VERSION "dbc-export 1 2025.20.8"

NS_ :

BS_:

BU_: ADSP APB APP APS APSB BB BMS CC CMP CMPD CP DAS DI DIF DIR DPB EPAS3P EPAS3S EPASTP EPASTS EPBL EPBR ESP EVSE FC GTW HCML HCMR HVP IBST ICR IDB LS OCS1P ODIN PARK PCS PLG PM PMF PMR PNCD PTC RADC RCM RCM2 RCM3 RCU SCCM SCM SCS SDCR TAS TCU TPMS TRCM UDS UI UIS UMC USM VC VCFRONT VCLEFT VCRIGHT VCSEC VEH

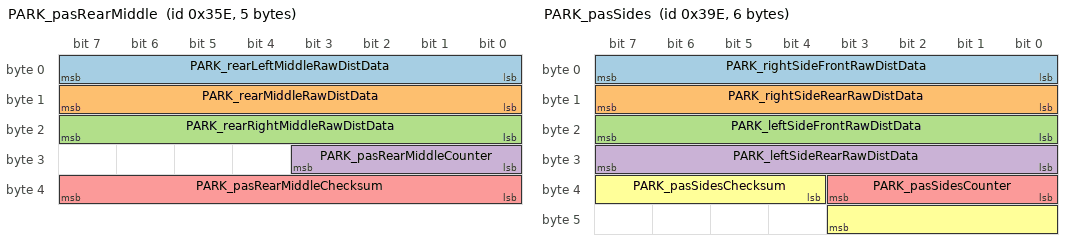
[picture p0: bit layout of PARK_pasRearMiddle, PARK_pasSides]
BO_ 862 PARK_pasRearMiddle: 5 PARK
 SG_ PARK_rearLeftMiddleRawDistData : 0|8@1+ (1,0) [0|254] "cm" Vector__XXX
 SG_ PARK_rearMiddleRawDistData : 8|8@1+ (1,0) [0|254] "cm" Vector__XXX
 SG_ PARK_rearRightMiddleRawDistData : 16|8@1+ (1,0) [0|254] "cm" Vector__XXX
 SG_ PARK_pasRearMiddleCounter : 24|4@1+ (1,0) [0|15] "" Vector__XXX
 SG_ PARK_pasRearMiddleChecksum : 32|8@1+ (1,0) [0|255] "" Vector__XXX

BO_ 926 PARK_pasSides: 6 PARK
 SG_ PARK_rightSideFrontRawDistData : 0|8@1+ (1,0) [0|254] "cm" Vector__XXX
 SG_ PARK_rightSideRearRawDistData : 8|8@1+ (1,0) [0|254] "cm" Vector__XXX
 SG_ PARK_leftSideFrontRawDistData : 16|8@1+ (1,0) [0|254] "cm" Vector__XXX
 SG_ PARK_leftSideRearRawDistData : 24|8@1+ (1,0) [0|254] "cm" Vector__XXX
 SG_ PARK_pasSidesCounter : 32|4@1+ (1,0) [0|15] "" Vector__XXX
 SG_ PARK_pasSidesChecksum : 36|8@1+ (1,0) [0|255] "" Vector__XXX

BO_ 606 PARK_pscEnvSlot: 8 PARK
 SG_ PARK_pscEnvSlotType M : 0|2@1+ (1,0) [0|3] "" Vector__XXX
 SG_ PARK_pscLeftParallelObj1X m0 : 3|11@1+ (2,-2048) [-2048|2044] "cm" Vector__XXX
 SG_ PARK_pscLeftParallelObj1Y m0 : 14|11@1+ (2,-2048) [-2048|2044] "cm" Vector__XXX
 SG_ PARK_pscLeftParallelObj1Alpha m0 : 25|7@1+ (2,-128) [-128|124] "deg" Vector__XXX
 SG_ PARK_pscLeftParallelObj2Y m0 : 35|11@1+ (2,-2048) [-2048|2044] "cm" Vector__XXX
 SG_ PARK_pscLeftParallelObj2X m0 : 46|11@1+ (2,-2048) [-2048|2044] "cm" Vector__XXX
 SG_ PARK_pscLeftParallelObj2Alpha m0 : 57|7@1+ (2,-128) [-128|124] "deg" Vector__XXX
 SG_ PARK_pscLeftCrossObj1X m1 : 3|11@1+ (2,-2048) [-2048|2044] "cm" Vector__XXX
 SG_ PARK_pscLeftCrossObj1Y m1 : 14|11@1+ (2,-2048) [-2048|2044] "cm" Vector__XXX
 SG_ PARK_pscLeftCrossObj1Alpha m1 : 25|7@1+ (2,-128) [-128|124] "deg" Vector__XXX
 SG_ PARK_pscLeftCrossObj2Y m1 : 35|11@1+ (2,-2048) [-2048|2044] "cm" Vector__XXX
 SG_ PARK_pscLeftCrossObj2X m1 : 46|11@1+ (2,-2048) [-2048|2044] "cm" Vector__XXX
 SG_ PARK_pscLeftCrossObj2Alpha m1 : 57|7@1+ (2,-128) [-128|124] "deg" Vector__XXX
 SG_ PARK_pscRightParallelObj1X m2 : 3|11@1+ (2,-2048) [-2048|2044] "cm" Vector__XXX
 SG_ PARK_pscRightParallelObj1Y m2 : 14|11@1+ (2,-2048) [-2048|2044] "cm" Vector__XXX
 SG_ PARK_pscRightParallelObj1Alpha m2 : 25|7@1+ (2,-128) [-128|124] "deg" Vector__XXX
 SG_ PARK_pscRightParallelObj2Y m2 : 35|11@1+ (2,-2048) [-2048|2044] "cm" Vector__XXX
 SG_ PARK_pscRightParallelObj2X m2 : 46|11@1+ (2,-2048) [-2048|2044] "cm" Vector__XXX
 SG_ PARK_pscRightParallelObj2Alpha m2 : 57|7@1+ (2,-128) [-128|124] "deg" Vector__XXX
 SG_ PARK_pscRightCrossObj1X m3 : 3|11@1+ (2,-2048) [-2048|2044] "cm" Vector__XXX
 SG_ PARK_pscRightCrossObj1Y m3 : 14|11@1+ (2,-2048) [-2048|2044] "cm" Vector__XXX
 SG_ PARK_pscRightCrossObj1Alpha m3 : 25|7@1+ (2,-128) [-128|124] "deg" Vector__XXX
 SG_ PARK_pscRightCrossObj2Y m3 : 35|11@1+ (2,-2048) [-2048|2044] "cm" Vector__XXX
 SG_ PARK_pscRightCrossObj2X m3 : 46|11@1+ (2,-2048) [-2048|2044] "cm" Vector__XXX
 SG_ PARK_pscRightCrossObj2Alpha m3 : 57|7@1+ (2,-128) [-128|124] "deg" Vector__XXX

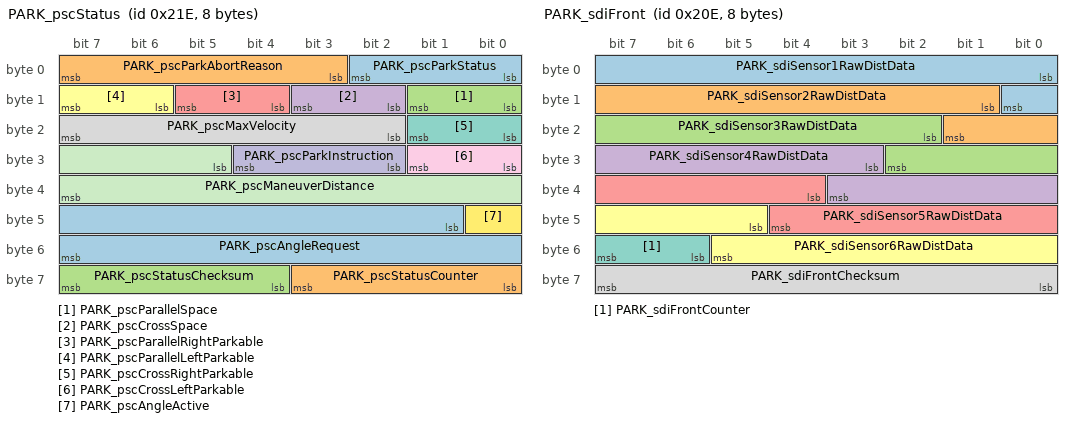
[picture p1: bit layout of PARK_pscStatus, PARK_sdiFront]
BO_ 542 PARK_pscStatus: 8 PARK
 SG_ PARK_pscParkStatus : 0|3@1+ (1,0) [0|6] "" Vector__XXX
 SG_ PARK_pscParkAbortReason : 3|5@1+ (1,0) [0|30] "" Vector__XXX
 SG_ PARK_pscParallelSpace : 8|2@1+ (1,0) [0|3] "" Vector__XXX
 SG_ PARK_pscCrossSpace : 10|2@1+ (1,0) [0|3] "" Vector__XXX
 SG_ PARK_pscParallelRightParkable : 12|2@1+ (1,0) [0|2] "" Vector__XXX
 SG_ PARK_pscParallelLeftParkable : 14|2@1+ (1,0) [0|2] "" Vector__XXX
 SG_ PARK_pscCrossRightParkable : 16|2@1+ (1,0) [0|2] "" Vector__XXX
 SG_ PARK_pscMaxVelocity : 18|6@1+ (0.1,0) [0|6.2] "kph" Vector__XXX
 SG_ PARK_pscCrossLeftParkable : 24|2@1+ (1,0) [0|2] "" Vector__XXX
 SG_ PARK_pscParkInstruction : 26|3@1+ (1,0) [0|6] "" Vector__XXX
 SG_ PARK_pscManeuverDistance : 29|11@1+ (1,0) [0|2046] "cm" Vector__XXX
 SG_ PARK_pscAngleActive : 40|1@1+ (1,0) [0|1] "" Vector__XXX
 SG_ PARK_pscAngleRequest : 41|15@1+ (0.1,-1638.4) [-1638.4|1638.3] "deg" Vector__XXX
 SG_ PARK_pscStatusCounter : 56|4@1+ (1,0) [0|15] "" Vector__XXX
 SG_ PARK_pscStatusChecksum : 60|4@1+ (1,0) [0|15] "" Vector__XXX

BO_ 590 PARK_pscVehSlot: 8 PARK
 SG_ PARK_pscVehSlotType M : 0|2@1+ (1,0) [0|3] "" Vector__XXX
 SG_ PARK_pscLeftParallelVehX m0 : 5|11@1+ (2,-2048) [-2048|2044] "cm" Vector__XXX
 SG_ PARK_pscLeftParallelVehY m0 : 16|11@1+ (2,-2048) [-2048|2044] "cm" Vector__XXX
 SG_ PARK_pscLeftParallelPsi m0 : 32|13@1+ (0.0009765625,0) [0|7.998046875] "radians" Vector__XXX
 SG_ PARK_pscLeftParallelSizeX m0 : 48|8@1+ (4,0) [0|1016] "cm" Vector__XXX
 SG_ PARK_pscLeftParallelSizeY m0 : 56|8@1+ (4,0) [0|1016] "cm" Vector__XXX
 SG_ PARK_pscLeftCrossVehX m1 : 5|11@1+ (2,-2048) [-2048|2044] "cm" Vector__XXX
 SG_ PARK_pscLeftCrossVehY m1 : 16|11@1+ (2,-2048) [-2048|2044] "cm" Vector__XXX
 SG_ PARK_pscLeftCrossPsi m1 : 32|13@1+ (0.0009765625,0) [0|7.998046875] "radians" Vector__XXX
 SG_ PARK_pscLeftCrossSizeX m1 : 48|8@1+ (4,0) [0|1016] "cm" Vector__XXX
 SG_ PARK_pscLeftCrossSizeY m1 : 56|8@1+ (4,0) [0|1016] "cm" Vector__XXX
 SG_ PARK_pscRightParallelVehX m2 : 5|11@1+ (2,-2048) [-2048|2044] "cm" Vector__XXX
 SG_ PARK_pscRightParallelVehY m2 : 16|11@1+ (2,-2048) [-2048|2044] "cm" Vector__XXX
 SG_ PARK_pscRightParallelPsi m2 : 32|13@1+ (0.0009765625,0) [0|7.998046875] "radians" Vector__XXX
 SG_ PARK_pscRightParallelSizeX m2 : 48|8@1+ (4,0) [0|1016] "cm" Vector__XXX
 SG_ PARK_pscRightParallelSizeY m2 : 56|8@1+ (4,0) [0|1016] "cm" Vector__XXX
 SG_ PARK_pscRightCrossVehX m3 : 5|11@1+ (2,-2048) [-2048|2044] "cm" Vector__XXX
 SG_ PARK_pscRightCrossVehY m3 : 16|11@1+ (2,-2048) [-2048|2044] "cm" Vector__XXX
 SG_ PARK_pscRightCrossPsi m3 : 32|13@1+ (0.0009765625,0) [0|7.998046875] "radians" Vector__XXX
 SG_ PARK_pscRightCrossSizeX m3 : 48|8@1+ (4,0) [0|1016] "cm" Vector__XXX
 SG_ PARK_pscRightCrossSizeY m3 : 56|8@1+ (4,0) [0|1016] "cm" Vector__XXX

BO_ 526 PARK_sdiFront: 8 PARK
 SG_ PARK_sdiSensor1RawDistData : 0|9@1+ (1,0) [0|510] "cm" Vector__XXX
 SG_ PARK_sdiSensor2RawDistData : 9|9@1+ (1,0) [0|510] "cm" Vector__XXX
 SG_ PARK_sdiSensor3RawDistData : 18|9@1+ (1,0) [0|510] "cm" Vector__XXX
 SG_ PARK_sdiSensor4RawDistData : 27|9@1+ (1,0) [0|510] "cm" Vector__XXX
 SG_ PARK_sdiSensor5RawDistData : 36|9@1+ (1,0) [0|510] "cm" Vector__XXX
 SG_ PARK_sdiSensor6RawDistData : 45|9@1+ (1,0) [0|510] "cm" Vector__XXX
 SG_ PARK_sdiFrontCounter : 54|2@1+ (1,0) [0|3] "" Vector__XXX
 SG_ PARK_sdiFrontChecksum : 56|8@1+ (1,0) [0|255] "" Vector__XXX

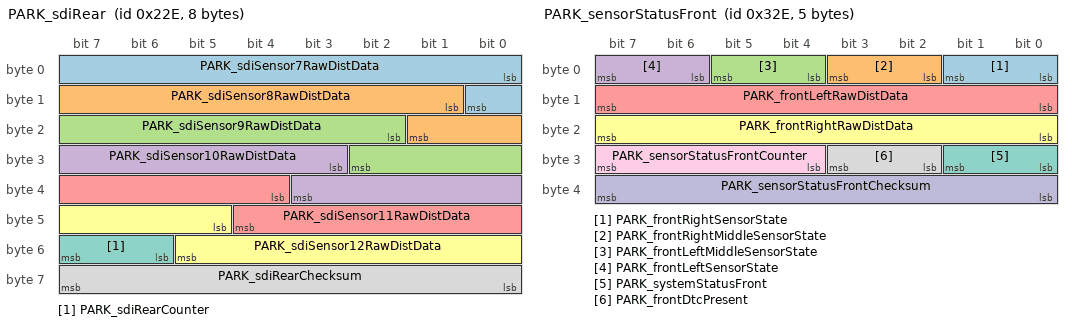
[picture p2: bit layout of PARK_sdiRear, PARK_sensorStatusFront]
BO_ 558 PARK_sdiRear: 8 PARK
 SG_ PARK_sdiSensor7RawDistData : 0|9@1+ (1,0) [0|510] "cm" Vector__XXX
 SG_ PARK_sdiSensor8RawDistData : 9|9@1+ (1,0) [0|510] "cm" Vector__XXX
 SG_ PARK_sdiSensor9RawDistData : 18|9@1+ (1,0) [0|510] "cm" Vector__XXX
 SG_ PARK_sdiSensor10RawDistData : 27|9@1+ (1,0) [0|510] "cm" Vector__XXX
 SG_ PARK_sdiSensor11RawDistData : 36|9@1+ (1,0) [0|510] "cm" Vector__XXX
 SG_ PARK_sdiSensor12RawDistData : 45|9@1+ (1,0) [0|510] "cm" Vector__XXX
 SG_ PARK_sdiRearCounter : 54|2@1+ (1,0) [0|3] "" Vector__XXX
 SG_ PARK_sdiRearChecksum : 56|8@1+ (1,0) [0|255] "" Vector__XXX

BO_ 814 PARK_sensorStatusFront: 5 PARK
 SG_ PARK_frontRightSensorState : 0|2@1+ (1,0) [0|2] "" Vector__XXX
 SG_ PARK_frontRightMiddleSensorState : 2|2@1+ (1,0) [0|2] "" Vector__XXX
 SG_ PARK_frontLeftMiddleSensorState : 4|2@1+ (1,0) [0|2] "" Vector__XXX
 SG_ PARK_frontLeftSensorState : 6|2@1+ (1,0) [0|2] "" Vector__XXX
 SG_ PARK_frontLeftRawDistData : 8|8@1+ (1,0) [0|254] "cm" Vector__XXX
 SG_ PARK_frontRightRawDistData : 16|8@1+ (1,0) [0|254] "cm" Vector__XXX
 SG_ PARK_systemStatusFront : 24|2@1+ (1,0) [0|2] "" Vector__XXX
 SG_ PARK_frontDtcPresent : 26|2@1+ (1,0) [0|2] "" Vector__XXX
 SG_ PARK_sensorStatusFrontCounter : 28|4@1+ (1,0) [0|15] "" Vector__XXX
 SG_ PARK_sensorStatusFrontChecksum : 32|8@1+ (1,0) [0|255] "" Vector__XXX

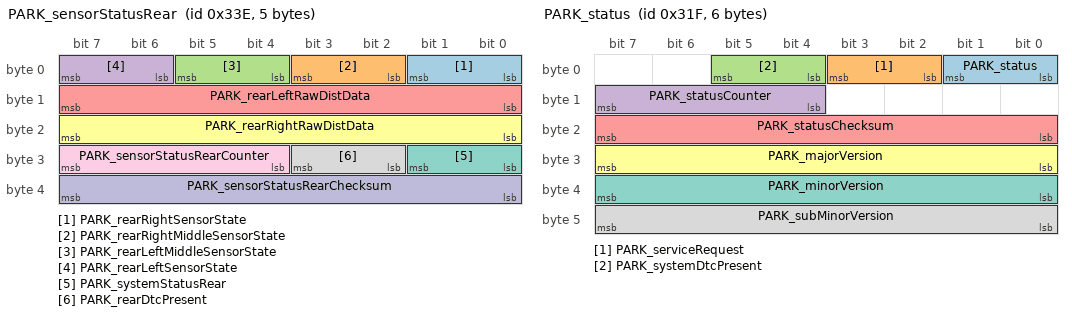
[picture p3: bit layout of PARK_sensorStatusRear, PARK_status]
BO_ 830 PARK_sensorStatusRear: 5 PARK
 SG_ PARK_rearRightSensorState : 0|2@1+ (1,0) [0|2] "" Vector__XXX
 SG_ PARK_rearRightMiddleSensorState : 2|2@1+ (1,0) [0|2] "" Vector__XXX
 SG_ PARK_rearLeftMiddleSensorState : 4|2@1+ (1,0) [0|2] "" Vector__XXX
 SG_ PARK_rearLeftSensorState : 6|2@1+ (1,0) [0|2] "" Vector__XXX
 SG_ PARK_rearLeftRawDistData : 8|8@1+ (1,0) [0|254] "cm" Vector__XXX
 SG_ PARK_rearRightRawDistData : 16|8@1+ (1,0) [0|254] "cm" Vector__XXX
 SG_ PARK_systemStatusRear : 24|2@1+ (1,0) [0|2] "" Vector__XXX
 SG_ PARK_rearDtcPresent : 26|2@1+ (1,0) [0|2] "" Vector__XXX
 SG_ PARK_sensorStatusRearCounter : 28|4@1+ (1,0) [0|15] "" Vector__XXX
 SG_ PARK_sensorStatusRearChecksum : 32|8@1+ (1,0) [0|255] "" Vector__XXX

BO_ 799 PARK_status: 6 PARK
 SG_ PARK_status : 0|2@1+ (1,0) [0|2] "" Vector__XXX
 SG_ PARK_serviceRequest : 2|2@1+ (1,0) [0|2] "" Vector__XXX
 SG_ PARK_systemDtcPresent : 4|2@1+ (1,0) [0|2] "" Vector__XXX
 SG_ PARK_statusCounter : 12|4@1+ (1,0) [0|15] "" Vector__XXX
 SG_ PARK_statusChecksum : 16|8@1+ (1,0) [0|255] "" Vector__XXX
 SG_ PARK_majorVersion : 24|8@1+ (1,0) [0|254] "" Vector__XXX
 SG_ PARK_minorVersion : 32|8@1+ (1,0) [0|254] "" Vector__XXX
 SG_ PARK_subMinorVersion : 40|8@1+ (1,0) [0|254] "" Vector__XXX

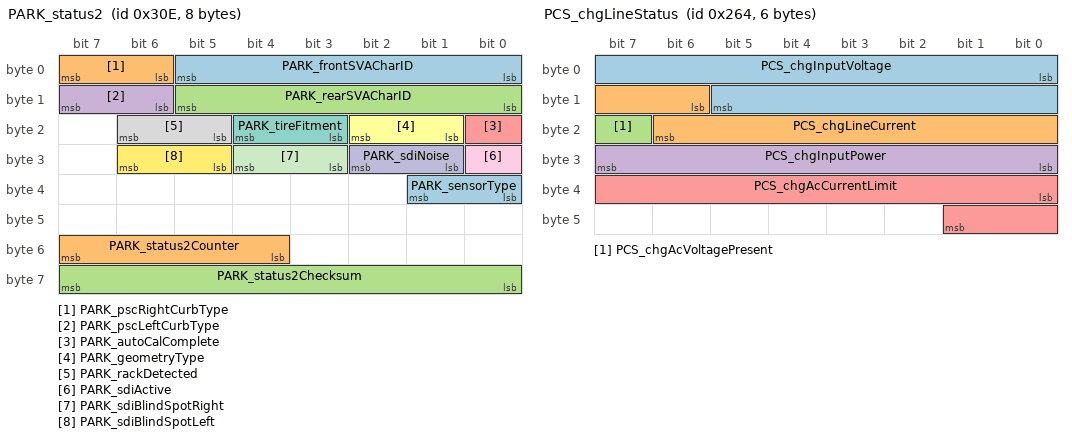
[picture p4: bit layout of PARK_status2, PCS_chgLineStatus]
BO_ 782 PARK_status2: 8 PARK
 SG_ PARK_frontSVACharID : 0|6@1+ (1,0) [0|63] "" Vector__XXX
 SG_ PARK_pscRightCurbType : 6|2@1+ (1,0) [0|3] "" Vector__XXX
 SG_ PARK_rearSVACharID : 8|6@1+ (1,0) [0|63] "" Vector__XXX
 SG_ PARK_pscLeftCurbType : 14|2@1+ (1,0) [0|3] "" Vector__XXX
 SG_ PARK_autoCalComplete : 16|1@1+ (1,0) [0|1] "" Vector__XXX
 SG_ PARK_geometryType : 17|2@1+ (1,0) [0|3] "" Vector__XXX
 SG_ PARK_tireFitment : 19|2@1+ (1,0) [0|2] "" Vector__XXX
 SG_ PARK_rackDetected : 21|2@1+ (1,0) [0|2] "" Vector__XXX
 SG_ PARK_sdiActive : 24|1@1+ (1,0) [0|1] "" Vector__XXX
 SG_ PARK_sdiNoise : 25|2@1+ (1,0) [0|2] "" Vector__XXX
 SG_ PARK_sdiBlindSpotRight : 27|2@1+ (1,0) [0|2] "" Vector__XXX
 SG_ PARK_sdiBlindSpotLeft : 29|2@1+ (1,0) [0|2] "" Vector__XXX
 SG_ PARK_sensorType : 32|2@1+ (1,0) [0|2] "" Vector__XXX
 SG_ PARK_status2Counter : 52|4@1+ (1,0) [0|15] "" Vector__XXX
 SG_ PARK_status2Checksum : 56|8@1+ (1,0) [0|255] "" Vector__XXX

BO_ 1630 PARK_udsResponse: 8 PARK
 SG_ PARK_udsResponseData : 0|64@1+ (1,0) [0|1.84467440737e+19] "" Vector__XXX

BO_ 894 PARK_warningMatrix: 8 PARK
 SG_ PARK_matrixIndex M : 0|4@1+ (1,0) [0|15] "" Vector__XXX
 SG_ PARK_a001_s1_overTemp m0 : 4|1@1+ (1,0) [0|1] "" Vector__XXX
 SG_ PARK_a002_s1_internalFail m0 : 5|1@1+ (1,0) [0|1] "" Vector__XXX
 SG_ PARK_a003_s1_linCommError m0 : 6|1@1+ (1,0) [0|1] "" Vector__XXX
 SG_ PARK_a004_s1_blocked m0 : 7|1@1+ (1,0) [0|1] "" Vector__XXX
 SG_ PARK_a005_s1_crossTalk m0 : 8|1@1+ (1,0) [0|1] "" Vector__XXX
 SG_ PARK_a006_s2_overTemp m0 : 9|1@1+ (1,0) [0|1] "" Vector__XXX
 SG_ PARK_a007_s2_internalFail m0 : 10|1@1+ (1,0) [0|1] "" Vector__XXX
 SG_ PARK_a008_s2_linCommError m0 : 11|1@1+ (1,0) [0|1] "" Vector__XXX
 SG_ PARK_a009_s2_blocked m0 : 12|1@1+ (1,0) [0|1] "" Vector__XXX
 SG_ PARK_a010_s2_crossTalk m0 : 13|1@1+ (1,0) [0|1] "" Vector__XXX
 SG_ PARK_a011_s3_overTemp m0 : 14|1@1+ (1,0) [0|1] "" Vector__XXX
 SG_ PARK_a012_s3_internalFail m0 : 15|1@1+ (1,0) [0|1] "" Vector__XXX
 SG_ PARK_a013_s3_linCommError m0 : 16|1@1+ (1,0) [0|1] "" Vector__XXX
 SG_ PARK_a014_s3_blocked m0 : 17|1@1+ (1,0) [0|1] "" Vector__XXX
 SG_ PARK_a015_s3_crossTalk m0 : 18|1@1+ (1,0) [0|1] "" Vector__XXX
 SG_ PARK_a016_s4_overTemp m0 : 19|1@1+ (1,0) [0|1] "" Vector__XXX
 SG_ PARK_a017_s4_internalFail m0 : 20|1@1+ (1,0) [0|1] "" Vector__XXX
 SG_ PARK_a018_s4_linCommError m0 : 21|1@1+ (1,0) [0|1] "" Vector__XXX
 SG_ PARK_a019_s4_blocked m0 : 22|1@1+ (1,0) [0|1] "" Vector__XXX
 SG_ PARK_a020_s4_crossTalk m0 : 23|1@1+ (1,0) [0|1] "" Vector__XXX
 SG_ PARK_a021_s5_overTemp m0 : 24|1@1+ (1,0) [0|1] "" Vector__XXX
 SG_ PARK_a022_s5_internalFail m0 : 25|1@1+ (1,0) [0|1] "" Vector__XXX
 SG_ PARK_a023_s5_linCommError m0 : 26|1@1+ (1,0) [0|1] "" Vector__XXX
 SG_ PARK_a024_s5_blocked m0 : 27|1@1+ (1,0) [0|1] "" Vector__XXX
 SG_ PARK_a025_s5_crossTalk m0 : 28|1@1+ (1,0) [0|1] "" Vector__XXX
 SG_ PARK_a026_s6_overTemp m0 : 29|1@1+ (1,0) [0|1] "" Vector__XXX
 SG_ PARK_a027_s6_internalFail m0 : 30|1@1+ (1,0) [0|1] "" Vector__XXX
 SG_ PARK_a028_s6_linCommError m0 : 31|1@1+ (1,0) [0|1] "" Vector__XXX
 SG_ PARK_a029_s6_blocked m0 : 32|1@1+ (1,0) [0|1] "" Vector__XXX
 SG_ PARK_a030_s6_crossTalk m0 : 33|1@1+ (1,0) [0|1] "" Vector__XXX
 SG_ PARK_a031_s7_overTemp m0 : 34|1@1+ (1,0) [0|1] "" Vector__XXX
 SG_ PARK_a032_s7_internalFail m0 : 35|1@1+ (1,0) [0|1] "" Vector__XXX
 SG_ PARK_a033_s7_linCommError m0 : 36|1@1+ (1,0) [0|1] "" Vector__XXX
 SG_ PARK_a034_s7_blocked m0 : 37|1@1+ (1,0) [0|1] "" Vector__XXX
 SG_ PARK_a035_s7_crossTalk m0 : 38|1@1+ (1,0) [0|1] "" Vector__XXX
 SG_ PARK_a036_s8_overTemp m0 : 39|1@1+ (1,0) [0|1] "" Vector__XXX
 SG_ PARK_a037_s8_internalFail m0 : 40|1@1+ (1,0) [0|1] "" Vector__XXX
 SG_ PARK_a038_s8_linCommError m0 : 41|1@1+ (1,0) [0|1] "" Vector__XXX
 SG_ PARK_a039_s8_blocked m0 : 42|1@1+ (1,0) [0|1] "" Vector__XXX
 SG_ PARK_a040_s8_crossTalk m0 : 43|1@1+ (1,0) [0|1] "" Vector__XXX
 SG_ PARK_a041_s9_overTemp m0 : 44|1@1+ (1,0) [0|1] "" Vector__XXX
 SG_ PARK_a042_s9_internalFail m0 : 45|1@1+ (1,0) [0|1] "" Vector__XXX
 SG_ PARK_a043_s9_linCommError m0 : 46|1@1+ (1,0) [0|1] "" Vector__XXX
 SG_ PARK_a044_s9_blocked m0 : 47|1@1+ (1,0) [0|1] "" Vector__XXX
 SG_ PARK_a045_s9_crossTalk m0 : 48|1@1+ (1,0) [0|1] "" Vector__XXX
 SG_ PARK_a046_s10_overTemp m0 : 49|1@1+ (1,0) [0|1] "" Vector__XXX
 SG_ PARK_a047_s10_internalFail m0 : 50|1@1+ (1,0) [0|1] "" Vector__XXX
 SG_ PARK_a048_s10_linCommError m0 : 51|1@1+ (1,0) [0|1] "" Vector__XXX
 SG_ PARK_a049_s10_blocked m0 : 52|1@1+ (1,0) [0|1] "" Vector__XXX
 SG_ PARK_a050_s10_crossTalk m0 : 53|1@1+ (1,0) [0|1] "" Vector__XXX
 SG_ PARK_a051_s11_overTemp m0 : 54|1@1+ (1,0) [0|1] "" Vector__XXX
 SG_ PARK_a052_s11_internalFail m0 : 55|1@1+ (1,0) [0|1] "" Vector__XXX
 SG_ PARK_a053_s11_linCommError m0 : 56|1@1+ (1,0) [0|1] "" Vector__XXX
 SG_ PARK_a054_s11_blocked m0 : 57|1@1+ (1,0) [0|1] "" Vector__XXX
 SG_ PARK_a055_s11_crossTalk m0 : 58|1@1+ (1,0) [0|1] "" Vector__XXX
 SG_ PARK_a056_s12_overTemp m0 : 59|1@1+ (1,0) [0|1] "" Vector__XXX
 SG_ PARK_a057_s12_internalFail m0 : 60|1@1+ (1,0) [0|1] "" Vector__XXX
 SG_ PARK_a058_s12_linCommError m0 : 61|1@1+ (1,0) [0|1] "" Vector__XXX
 SG_ PARK_a059_s12_blocked m0 : 62|1@1+ (1,0) [0|1] "" Vector__XXX
 SG_ PARK_a060_s12_crossTalk m0 : 63|1@1+ (1,0) [0|1] "" Vector__XXX
 SG_ PARK_a061_ecuUnderVoltage m1 : 4|1@1+ (1,0) [0|1] "" Vector__XXX
 SG_ PARK_a062_ecuOverVoltage m1 : 5|1@1+ (1,0) [0|1] "" Vector__XXX
 SG_ PARK_a063_sensorVoltage m1 : 6|1@1+ (1,0) [0|1] "" Vector__XXX
 SG_ PARK_a064_ecuFault m1 : 7|1@1+ (1,0) [0|1] "" Vector__XXX
 SG_ PARK_a065_crcFault m1 : 8|1@1+ (1,0) [0|1] "" Vector__XXX
 SG_ PARK_a066_calibrationMissing m1 : 9|1@1+ (1,0) [0|1] "" Vector__XXX
 SG_ PARK_a067_privateCANBusOff m1 : 10|1@1+ (1,0) [0|1] "" Vector__XXX
 SG_ PARK_a068_hardwareWatchDog m1 : 11|1@1+ (1,0) [0|1] "" Vector__XXX
 SG_ PARK_a069_dasMia m1 : 12|1@1+ (1,0) [0|1] "" Vector__XXX
 SG_ PARK_a070_sccmMia m1 : 13|1@1+ (1,0) [0|1] "" Vector__XXX
 SG_ PARK_a071_diMia m1 : 14|1@1+ (1,0) [0|1] "" Vector__XXX
 SG_ PARK_a072_epasMia m1 : 15|1@1+ (1,0) [0|1] "" Vector__XXX
 SG_ PARK_a073_epbMia m1 : 16|1@1+ (1,0) [0|1] "" Vector__XXX
 SG_ PARK_a074_espMia m1 : 17|1@1+ (1,0) [0|1] "" Vector__XXX
 SG_ PARK_a075_rcmMia m1 : 18|1@1+ (1,0) [0|1] "" Vector__XXX
 SG_ PARK_a076_vcFrontMia m1 : 19|1@1+ (1,0) [0|1] "" Vector__XXX
 SG_ PARK_a077_dasError m1 : 20|1@1+ (1,0) [0|1] "" Vector__XXX
 SG_ PARK_a078_diError m1 : 21|1@1+ (1,0) [0|1] "" Vector__XXX
 SG_ PARK_a079_epasError m1 : 22|1@1+ (1,0) [0|1] "" Vector__XXX
 SG_ PARK_a080_epbError m1 : 23|1@1+ (1,0) [0|1] "" Vector__XXX
 SG_ PARK_a081_espError m1 : 24|1@1+ (1,0) [0|1] "" Vector__XXX
 SG_ PARK_a082_rcmError m1 : 25|1@1+ (1,0) [0|1] "" Vector__XXX
 SG_ PARK_a083_vcFrontError m1 : 26|1@1+ (1,0) [0|1] "" Vector__XXX
 SG_ PARK_a084_sccmError m1 : 27|1@1+ (1,0) [0|1] "" Vector__XXX
 SG_ PARK_a085_watchdogReset m1 : 28|1@1+ (1,0) [0|1] "" Vector__XXX
 SG_ PARK_a086_nvmFault m1 : 29|1@1+ (1,0) [0|1] "" Vector__XXX
 SG_ PARK_a087_sensorMismatchError m1 : 30|1@1+ (1,0) [0|1] "" Vector__XXX

BO_ 1060 PCS_alertLog: 8 PCS
 SG_ PCS_alertID M : 0|7@1+ (1,0) [0|127] "" Vector__XXX
 SG_ PCS_alertSet : 15|1@1+ (1,0) [0|1] "" Vector__XXX
 SG_ PCS_alertSource : 61|3@1+ (1,0) [0|7] "" Vector__XXX
 SG_ PCS_a001_llcFrequency m1 : 16|8@1+ (1,50) [50|305] "kHz" Vector__XXX
 SG_ PCS_a001_llcCurrent m1 : 24|8@1+ (0.1,0) [0|25.5] "A" Vector__XXX
 SG_ PCS_a001_phState m1 : 32|4@1+ (1,0) [0|15] "" Vector__XXX
 SG_ PCS_a001_pfcCurrentRms m1 : 36|9@1+ (0.1,0) [0|51.1] "A" Vector__XXX
 SG_ PCS_a001_intBusV m1 : 45|9@1+ (1,0) [0|511] "V" Vector__XXX
 SG_ PCS_a002_phState m2 : 16|4@1+ (1,0) [0|15] "" Vector__XXX
 SG_ PCS_a003_phState m3 : 16|4@1+ (1,0) [0|15] "" Vector__XXX
 SG_ PCS_a004_phState m4 : 16|4@1+ (1,0) [0|15] "" Vector__XXX
 SG_ PCS_a005_outputV m5 : 16|8@1+ (2,0) [0|510] "V" Vector__XXX
 SG_ PCS_a005_outputVOvThreshold m5 : 24|8@1+ (2,0) [0|510] "V" Vector__XXX
 SG_ PCS_a006_phState m6 : 16|4@1+ (1,0) [0|15] "" Vector__XXX
 SG_ PCS_a006_intBusPrechargeTarget m6 : 20|9@1+ (1,0) [0|511] "V" Vector__XXX
 SG_ PCS_a006_intBusV m6 : 29|9@1+ (1,0) [0|511] "V" Vector__XXX
 SG_ PCS_a006_inputVrms m6 : 38|9@1+ (1,0) [0|511] "V" Vector__XXX
 SG_ PCS_a006_inputVToIntBusDeltaMax m6 : 47|7@1+ (1,0) [0|127] "V" Vector__XXX
 SG_ PCS_a006_inputFrequency m6 : 54|7@1+ (1,40) [40|167] "Hz" Vector__XXX
 SG_ PCS_a007_phATemperature m7 : 16|7@1+ (1,0) [0|127] "C" Vector__XXX
 SG_ PCS_a007_phBTemperature m7 : 23|7@1+ (1,0) [0|127] "C" Vector__XXX
 SG_ PCS_a007_phCTemperature m7 : 30|7@1+ (1,0) [0|127] "C" Vector__XXX
 SG_ PCS_a007_ambientTemperature m7 : 37|7@1+ (1,0) [0|127] "C" Vector__XXX
 SG_ PCS_a007_inputVrms m7 : 44|9@1+ (1,0) [0|511] "V" Vector__XXX
 SG_ PCS_a007_inputIrms m7 : 53|8@1+ (0.5,0) [0|127.5] "A" Vector__XXX
 SG_ PCS_a008_phState m8 : 16|4@1+ (1,0) [0|15] "" Vector__XXX
 SG_ PCS_a008_phaseTemperature m8 : 20|11@1- (0.1,40) [-62.4|142.3] "C" Vector__XXX
 SG_ PCS_a008_inputVrms m8 : 31|9@1+ (1,0) [0|511] "V" Vector__XXX
 SG_ PCS_a008_inputIrms m8 : 40|10@1+ (0.1,0) [0|102.3] "A" Vector__XXX
 SG_ PCS_a009_phState m9 : 16|4@1+ (1,0) [0|15] "" Vector__XXX
 SG_ PCS_a009_pfcCurrentRms m9 : 20|9@1+ (0.1,0) [0|51.1] "A" Vector__XXX
 SG_ PCS_a009_pfcCurrentTarget m9 : 32|12@1+ (0.01,0) [0|40.95] "A" Vector__XXX
 SG_ PCS_a009_llcCurrent m9 : 44|8@1+ (0.1,0) [0|25.5] "A" Vector__XXX
 SG_ PCS_a009_intBusV m9 : 52|8@1+ (2,0) [0|510] "V" Vector__XXX
 SG_ PCS_a010_phState m10 : 16|4@1+ (1,0) [0|15] "" Vector__XXX
 SG_ PCS_a010_pfcCurrentRms m10 : 20|9@1+ (0.1,0) [0|51.1] "A" Vector__XXX
 SG_ PCS_a010_llcCurrent m10 : 32|8@1+ (0.1,0) [0|25.5] "A" Vector__XXX
 SG_ PCS_a010_intBusV m10 : 40|9@1+ (1,0) [0|511] "V" Vector__XXX
 SG_ PCS_a010_intBusVTarget m10 : 49|9@1+ (1,0) [0|511] "V" Vector__XXX
 SG_ PCS_a011_phState m11 : 16|4@1+ (1,0) [0|15] "" Vector__XXX
 SG_ PCS_a011_llcCurrent m11 : 20|8@1+ (0.1,0) [0|25.5] "A" Vector__XXX
 SG_ PCS_a011_llcCurrentTarget m11 : 28|8@1+ (0.1,0) [0|25.5] "A" Vector__XXX
 SG_ PCS_a011_llcFrequency m11 : 36|8@1+ (1,50) [50|305] "kHz" Vector__XXX
 SG_ PCS_a011_intBusV m11 : 44|8@1+ (2,0) [0|510] "V" Vector__XXX
 SG_ PCS_a011_outputV m11 : 52|8@1+ (2,0) [0|510] "V" Vector__XXX
 SG_ PCS_a012_phState m12 : 16|4@1+ (1,0) [0|15] "" Vector__XXX
 SG_ PCS_a012_llcFrequency m12 : 20|8@1+ (1,50) [50|305] "kHz" Vector__XXX
 SG_ PCS_a012_llcCurrent m12 : 28|8@1+ (0.1,0) [0|25.5] "A" Vector__XXX
 SG_ PCS_a012_outOfIBandDuration m12 : 36|7@1+ (0.05,0) [0|6.35] "us" Vector__XXX
 SG_ PCS_a012_batteryV m12 : 43|9@1+ (1,0) [0|511] "V" Vector__XXX
 SG_ PCS_a012_transientRetryCount m12 : 52|9@1+ (0.1,0) [0|51.1] "-" Vector__XXX
 SG_ PCS_a013_phState m13 : 16|4@1+ (1,0) [0|15] "" Vector__XXX
 SG_ PCS_a013_intBusPrechargeTarget m13 : 20|9@1+ (1,0) [0|511] "V" Vector__XXX
 SG_ PCS_a013_intBusV m13 : 29|9@1+ (1,0) [0|511] "V" Vector__XXX
 SG_ PCS_a013_inputVrms m13 : 38|9@1+ (1,0) [0|511] "V" Vector__XXX
 SG_ PCS_a013_inputVToIntBusDeltaMax m13 : 47|7@1+ (1,0) [0|127] "V" Vector__XXX
 SG_ PCS_a013_inputFrequency m13 : 54|7@1+ (1,40) [40|167] "Hz" Vector__XXX
 SG_ PCS_a014_phaTemperature m14 : 16|11@1- (0.1,40) [-62.4|142.3] "C" Vector__XXX
 SG_ PCS_a014_phbTemperature m14 : 27|11@1- (0.1,40) [-62.4|142.3] "C" Vector__XXX
 SG_ PCS_a014_phcTemperature m14 : 40|11@1- (0.1,40) [-62.4|142.3] "C" Vector__XXX
 SG_ PCS_a015_lvBusVoltage m15 : 16|8@1+ (0.15625,0) [0|39.84375] "V" Vector__XXX
 SG_ PCS_a016_phAVoltSrcMissingDetect m16 : 16|1@1+ (1,0) [0|1] "" Vector__XXX
 SG_ PCS_a016_phBVoltSrcMissingDetect m16 : 17|1@1+ (1,0) [0|1] "" Vector__XXX
 SG_ PCS_a016_phCVoltSrcMissingDetect m16 : 18|1@1+ (1,0) [0|1] "" Vector__XXX
 SG_ PCS_a018_PhaseDiff_L1N_L2N m18 : 16|9@1+ (1,-1) [-1|510] "deg" Vector__XXX
 SG_ PCS_a018_PhaseDiff_L2N_L3N m18 : 25|9@1+ (1,-1) [-1|510] "deg" Vector__XXX
 SG_ PCS_a018_PhaseDiff_L1N_L3N m18 : 34|9@1+ (1,-1) [-1|510] "deg" Vector__XXX
 SG_ PCS_a018_PhaseDiff_L1L2_L1N m18 : 43|9@1+ (1,-1) [-1|510] "deg" Vector__XXX
 SG_ PCS_a018_L1NLocked m18 : 52|1@1+ (1,0) [0|1] "" Vector__XXX
 SG_ PCS_a018_L2NLocked m18 : 53|1@1+ (1,0) [0|1] "" Vector__XXX
 SG_ PCS_a018_L3NLocked m18 : 54|1@1+ (1,0) [0|1] "" Vector__XXX
 SG_ PCS_a018_L1L2Locked m18 : 55|1@1+ (1,0) [0|1] "" Vector__XXX
 SG_ PCS_a019_pcsMaxAvailablePower m19 : 16|8@1+ (0.1,0) [0|25.5] "kW" Vector__XXX
 SG_ PCS_a019_utilityPowerAvailable m19 : 24|8@1+ (0.1,0) [0|25.5] "kW" Vector__XXX
 SG_ PCS_a019_userPowerRequest m19 : 32|8@1+ (0.1,0) [0|25.5] "kW" Vector__XXX
 SG_ PCS_a019_phAFaulted m19 : 40|1@1+ (1,0) [0|1] "" Vector__XXX
 SG_ PCS_a019_phBFaulted m19 : 41|1@1+ (1,0) [0|1] "" Vector__XXX
 SG_ PCS_a019_phCFaulted m19 : 42|1@1+ (1,0) [0|1] "" Vector__XXX
 SG_ PCS_a020_chargeEnableLine m20 : 16|1@1+ (1,0) [0|1] "" Vector__XXX
 SG_ PCS_a020_chargeEnableCan m20 : 17|1@1+ (1,0) [0|1] "" Vector__XXX
 SG_ PCS_a021_HVP_hvsControl m21 : 16|1@1+ (1,0) [0|1] "" Vector__XXX
 SG_ PCS_a022_BMS_pcsRequest m22 : 16|1@1+ (1,0) [0|1] "" Vector__XXX
 SG_ PCS_a022_BMS_chargeStatus m22 : 17|1@1+ (1,0) [0|1] "" Vector__XXX
 SG_ PCS_a023_CP_chargeStatus m23 : 16|1@1+ (1,0) [0|1] "" Vector__XXX
 SG_ PCS_a023_CP_status m23 : 17|1@1+ (1,0) [0|1] "" Vector__XXX
 SG_ PCS_a024_VCFRONT_sensors m24 : 16|1@1+ (1,0) [0|1] "" Vector__XXX
 SG_ PCS_a024_VCFRONT_vehicleStatus m24 : 17|1@1+ (1,0) [0|1] "" Vector__XXX
 SG_ PCS_a024_VCFRONT_systemStatus m24 : 18|1@1+ (1,0) [0|1] "" Vector__XXX
 SG_ PCS_a024_VCFRONT_coolant m24 : 19|1@1+ (1,0) [0|1] "" Vector__XXX
 SG_ PCS_a024_VCFRONT_vehNm m24 : 20|1@1+ (1,0) [0|1] "" Vector__XXX
 SG_ PCS_a025_cpu2ErrorCode m25 : 16|4@1+ (1,0) [0|15] "" Vector__XXX
 SG_ PCS_a025_bootromStatus m25 : 20|4@1+ (1,0) [0|15] "" Vector__XXX
 SG_ PCS_a025_bootloaderStatus m25 : 24|4@1+ (1,0) [0|15] "" Vector__XXX
 SG_ PCS_a025_bootromRequestFlag m25 : 28|1@1+ (1,0) [0|1] "" Vector__XXX
 SG_ PCS_a025_bootromRequestStatusFla m25 : 29|1@1+ (1,0) [0|1] "" Vector__XXX
 SG_ PCS_a025_cpu2StoredAppCrcLsb16 m25 : 32|16@1+ (1,0) [0|65535] "" Vector__XXX
 SG_ PCS_a027_chgPhATemp m27 : 16|8@1- (1,40) [-88|167] "C" Vector__XXX
 SG_ PCS_a027_chgPhBTemp m27 : 24|8@1- (1,40) [-88|167] "C" Vector__XXX
 SG_ PCS_a027_chgPhCTemp m27 : 32|8@1- (1,40) [-88|167] "C" Vector__XXX
 SG_ PCS_a027_chgPhANoFlowBucket m27 : 40|5@1+ (0.2,0) [0|6.2] "-" Vector__XXX
 SG_ PCS_a027_chgPhBNoFlowBucket m27 : 48|5@1+ (0.2,0) [0|6.2] "-" Vector__XXX
 SG_ PCS_a027_chgPhCNoFlowBucket m27 : 56|5@1+ (0.2,0) [0|6.2] "-" Vector__XXX
 SG_ PCS_a028_outputV m28 : 16|10@1+ (0.5,0) [0|511.5] "V" Vector__XXX
 SG_ PCS_a028_outputVUvThreshold m28 : 26|10@1+ (0.5,0) [0|511.5] "V" Vector__XXX
 SG_ PCS_a029_inputVrms m29 : 16|9@1+ (1,0) [0|511] "V" Vector__XXX
 SG_ PCS_a029_chgInputPower m29 : 32|8@1+ (0.1,0) [0|25.5] "kW" Vector__XXX
 SG_ PCS_a029_bmsPowerCommand m29 : 40|8@1+ (0.1,0) [0|25.5] "kW" Vector__XXX
 SG_ PCS_a029_phaseConfig m29 : 48|4@1+ (1,0) [1|15] "" Vector__XXX
 SG_ PCS_a030_canRxErrorType m30 : 16|3@1+ (1,0) [0|7] "" Vector__XXX
 SG_ PCS_a030_canID m30 : 24|16@1+ (1,0) [0|65535] "" Vector__XXX
 SG_ PCS_a032_phATransientRetryCount m32 : 16|9@1+ (0.1,0) [0|51.1] "-" Vector__XXX
 SG_ PCS_a032_phBTransientRetryCount m32 : 25|9@1+ (0.1,0) [0|51.1] "-" Vector__XXX
 SG_ PCS_a032_phCTransientRetryCount m32 : 34|9@1+ (0.1,0) [0|51.1] "-" Vector__XXX
 SG_ PCS_a032_phAFaulted m32 : 43|1@1+ (1,0) [0|1] "" Vector__XXX
 SG_ PCS_a032_phBFaulted m32 : 44|1@1+ (1,0) [0|1] "" Vector__XXX
 SG_ PCS_a032_phCFaulted m32 : 45|1@1+ (1,0) [0|1] "" Vector__XXX
 SG_ PCS_a033_HV_busV m33 : 16|12@1+ (0.146484375,0) [0|599.853515625] "V" Vector__XXX
 SG_ PCS_a034_HV_busV m34 : 16|12@1+ (0.146484375,0) [0|599.853515625] "V" Vector__XXX
 SG_ PCS_a035_LV_busV m35 : 16|12@1+ (0.009765625,0) [0|39.990234375] "V" Vector__XXX
 SG_ PCS_a036_LV_busV m36 : 16|12@1+ (0.009765625,0) [0|39.990234375] "V" Vector__XXX
 SG_ PCS_a037_dcdcPwmDeassertedCount m37 : 16|8@1+ (1,0) [0|255] "" Vector__XXX
 SG_ PCS_a038_dcdcClaFaultCode m38 : 16|4@1+ (1,0) [0|15] "" Vector__XXX
 SG_ PCS_a038_dcdcSubState m38 : 20|5@1+ (1,0) [0|31] "" Vector__XXX
 SG_ PCS_a038_dcdcLvBusV m38 : 25|8@1+ (0.15625,0) [0|39.84375] "V" Vector__XXX
 SG_ PCS_a038_dcdcHvBusV m38 : 33|10@1+ (0.5859375,0) [0|599.4140625] "V" Vector__XXX
 SG_ PCS_a038_dcdcLvBusCurrent_A m38 : 43|10@1- (0.78125,0) [-400|399.21875] "A" Vector__XXX
 SG_ PCS_a038_dcdcPwmEnableDeasserted m38 : 53|7@1+ (1,0) [0|127] "" Vector__XXX
 SG_ PCS_a038_dcdcPwmEnableLine m38 : 60|1@1+ (1,0) [0|1] "" Vector__XXX
 SG_ PCS_a039_SDModuleClockFault_HV m39 : 16|1@1+ (1,0) [0|1] "" Vector__XXX
 SG_ PCS_a039_SDModuleClockFault_LV m39 : 17|1@1+ (1,0) [0|1] "" Vector__XXX
 SG_ PCS_a040_dcdcLvVoltageTarget m40 : 16|8@1+ (0.1,0) [0|25.5] "V" Vector__XXX
 SG_ PCS_a040_dcdcLvVoltage m40 : 24|8@1+ (0.1,0) [0|25.5] "V" Vector__XXX
 SG_ PCS_a040_dcdcLvOutputCurrent m40 : 32|13@1- (0.1,0) [-409.6|409.5] "A" Vector__XXX
 SG_ PCS_a041_dcdcTemperature m41 : 16|11@1- (0.1,40) [-62.4|142.3] "C" Vector__XXX
 SG_ PCS_a042_dcdcEnableLine m42 : 16|1@1+ (1,0) [0|1] "" Vector__XXX
 SG_ PCS_a042_dcdcEnableCan m42 : 17|1@1+ (1,0) [0|1] "" Vector__XXX
 SG_ PCS_a043_dcdcLvBusV m43 : 16|10@1+ (0.0390625,0) [0|39.9609375] "V" Vector__XXX
 SG_ PCS_a043_dcdcHvBusV m43 : 26|12@1+ (0.146484375,0) [0|599.853515625] "V" Vector__XXX
 SG_ PCS_a043_hvPrechargeTargetV m43 : 40|12@1+ (0.146484375,0) [0|599.853515625] "V" Vector__XXX
 SG_ PCS_a044_FaultReasonCode m44 : 16|2@1+ (1,0) [1|3] "" Vector__XXX
 SG_ PCS_a044_shortTime_us m44 : 18|10@1+ (0.0312805473804,0) [0|31.9999999701] "us" Vector__XXX
 SG_ PCS_a044_dcdcLvBusCurrent_A m44 : 28|10@1+ (0.391006857157,0) [0|400.000014872] "A" Vector__XXX
 SG_ PCS_a044_vTankPeak_abs_V m44 : 38|10@1+ (1,0) [0|1023] "V" Vector__XXX
 SG_ PCS_a045_hvBusEstimated_C_uF m45 : 16|10@1+ (7.820137,0) [0|8000.000151] "uF" Vector__XXX
 SG_ PCS_a045_hvBusEstimated_R_kOhm m45 : 26|10@1+ (0.0488758571446,0) [0|50.0000018589] "kOhm" Vector__XXX
 SG_ PCS_a046_hvBusEstimated_C_uF m46 : 16|10@1+ (7.820137,0) [0|8000.000151] "uF" Vector__XXX
 SG_ PCS_a046_hvBusEstimated_R_kOhm m46 : 26|10@1+ (0.0488758571446,0) [0|50.0000018589] "kOhm" Vector__XXX
 SG_ PCS_a047_cpu1BootLoaderCrcMismat m47 : 16|1@1+ (1,0) [0|1] "" Vector__XXX
 SG_ PCS_a047_cpu2BootLoaderCrcMismat m47 : 17|1@1+ (1,0) [0|1] "" Vector__XXX
 SG_ PCS_a047_calculatedBootloaderCrc m47 : 24|32@1+ (1,0) [0|4294967295] "" Vector__XXX
 SG_ PCS_a049_dcdcTemperature m49 : 16|11@1- (0.1,40) [-62.4|142.3] "C" Vector__XXX
 SG_ PCS_a051_phState m51 : 16|4@1+ (1,0) [0|15] "" Vector__XXX
 SG_ PCS_a051_pfcCurrentRms m51 : 20|9@1+ (0.1,0) [0|51.1] "A" Vector__XXX
 SG_ PCS_a051_llcCurrent m51 : 29|8@1+ (0.1,0) [0|25.5] "A" Vector__XXX
 SG_ PCS_a051_intBusV m51 : 37|9@1+ (1,0) [0|511] "V" Vector__XXX
 SG_ PCS_a051_intBusVTarget m51 : 46|9@1+ (1,0) [0|511] "V" Vector__XXX
 SG_ PCS_a051_intBusStaticRipple m51 : 55|6@1+ (1,0) [0|63] "V" Vector__XXX
 SG_ PCS_a052_inputVrms m52 : 16|9@1+ (1,0) [0|511] "V" Vector__XXX
 SG_ PCS_a053_inputVrms m53 : 16|9@1+ (1,0) [0|511] "V" Vector__XXX
 SG_ PCS_a053_inputIrms m53 : 25|10@1+ (0.1,0) [0|102.3] "A" Vector__XXX
 SG_ PCS_a053_acChargeCurrentLimit m53 : 40|7@1+ (1,0) [0|127] "A" Vector__XXX
 SG_ PCS_a053_startingInputVrms m53 : 47|9@1+ (1,0) [0|511] "V" Vector__XXX
 SG_ PCS_a053_phaseConfig m53 : 56|4@1+ (1,0) [1|15] "" Vector__XXX
 SG_ PCS_a054_inputVrms m54 : 16|9@1+ (1,0) [0|511] "V" Vector__XXX
 SG_ PCS_a054_inputIrms m54 : 25|10@1+ (0.1,0) [0|102.3] "A" Vector__XXX
 SG_ PCS_a054_acChargeCurrentLimit m54 : 40|7@1+ (1,0) [0|127] "A" Vector__XXX
 SG_ PCS_a054_startingInputVrms m54 : 47|9@1+ (1,0) [0|511] "V" Vector__XXX
 SG_ PCS_a054_phaseConfig m54 : 56|4@1+ (1,0) [1|15] "" Vector__XXX
 SG_ PCS_a057_inputVrms m57 : 16|10@1+ (0.5,0) [0|511.5] "V" Vector__XXX
 SG_ PCS_a057_inputFrequency m57 : 26|9@1+ (0.1,40) [40|91.1] "Hz" Vector__XXX
 SG_ PCS_a058_inputVrms m58 : 16|10@1+ (0.5,0) [0|511.5] "V" Vector__XXX
 SG_ PCS_a058_inputFrequency m58 : 26|12@1+ (0.01,40) [40|80.95] "Hz" Vector__XXX
 SG_ PCS_a059_inputVrms m59 : 16|10@1+ (0.5,0) [0|511.5] "V" Vector__XXX
 SG_ PCS_a059_inputOvRmsThreshold m59 : 26|10@1+ (0.5,0) [0|511.5] "V" Vector__XXX
 SG_ PCS_a060_inputVPeak m60 : 16|10@1+ (0.5,0) [0|511.5] "V" Vector__XXX
 SG_ PCS_a060_inputOvPeakThreshold m60 : 26|10@1+ (0.5,0) [0|511.5] "V" Vector__XXX
 SG_ PCS_a061_chgInputVdcOffset_L1N m61 : 16|8@1+ (1,0) [0|255] "V" Vector__XXX
 SG_ PCS_a061_chgInputVdcOffset_L2N m61 : 24|8@1+ (1,0) [0|255] "V" Vector__XXX
 SG_ PCS_a061_chgInputVdcOffset_L3N m61 : 32|8@1+ (1,0) [0|255] "V" Vector__XXX
 SG_ PCS_a061_chgInputVdcOffset_L1L2 m61 : 40|8@1+ (1,0) [0|255] "V" Vector__XXX
 SG_ PCS_a061_PllSourceIrrational_L1N m61 : 48|1@1+ (1,0) [0|1] "" Vector__XXX
 SG_ PCS_a061_PllSourceIrrational_L2N m61 : 49|1@1+ (1,0) [0|1] "" Vector__XXX
 SG_ PCS_a061_PllSourceIrrational_L3N m61 : 50|1@1+ (1,0) [0|1] "" Vector__XXX
 SG_ PCS_a061_PllSourceIrrational_L1L m61 : 51|1@1+ (1,0) [0|1] "" Vector__XXX
 SG_ PCS_a062_chgInputIOffset m62 : 16|12@1- (0.01,0) [-20.48|20.47] "A" Vector__XXX
 SG_ PCS_a063_chgOutputV m63 : 16|10@1+ (1,0) [0|1023] "V" Vector__XXX
 SG_ PCS_a063_hvpHvLinkVoltage m63 : 26|11@1- (1,0) [-1024|1023] "V" Vector__XXX
 SG_ PCS_a064_chgOutputIOffset m64 : 16|12@1- (0.01,0) [-20.48|20.47] "A" Vector__XXX
 SG_ PCS_a065_inputVrms m65 : 16|10@1+ (0.5,0) [0|511.5] "V" Vector__XXX
 SG_ PCS_a065_inputFrequency m65 : 26|9@1+ (0.1,40) [40|91.1] "Hz" Vector__XXX
 SG_ PCS_a066_dcdcHvBusVolt m66 : 16|14@1+ (0.1,0) [0|1638.3] "V" Vector__XXX
 SG_ PCS_a066_hvpHvLinkVoltage m66 : 32|11@1- (1,0) [-1024|1023] "V" Vector__XXX
 SG_ PCS_a067_dcdcLvBusVolt m67 : 16|13@1+ (0.01,0) [0|81.91] "V" Vector__XXX
 SG_ PCS_a067_vcfrontPcsEFuseV m67 : 29|10@1+ (0.1,0) [0|102.2] "V" Vector__XXX
 SG_ PCS_a067_vcfrontVcrightVoltage m67 : 40|10@1+ (0.1,0) [0|102.2] "V" Vector__XXX
 SG_ PCS_a068_dcdcTankVolt m68 : 16|16@1- (0.030517578125,0) [-1000|999.969482422] "V" Vector__XXX
 SG_ PCS_a068_dcdcTankVoltOffset m68 : 32|16@1- (0.00152587890625,0) [-50|49.9984741211] "V" Vector__XXX
 SG_ PCS_a069_phState m69 : 16|4@1+ (1,0) [0|15] "" Vector__XXX
 SG_ PCS_a069_inputIDelta m69 : 20|10@1+ (0.1,0) [0|102.3] "A" Vector__XXX
 SG_ PCS_a069_inputVrms m69 : 30|10@1+ (0.5,0) [0|511.5] "V" Vector__XXX
 SG_ PCS_a069_intBusV m69 : 40|9@1+ (1,0) [0|511] "V" Vector__XXX
 SG_ PCS_a069_inputFrequency m69 : 49|9@1+ (0.1,40) [40|91.1] "Hz" Vector__XXX
 SG_ PCS_a070_phState m70 : 16|4@1+ (1,0) [0|15] "" Vector__XXX
 SG_ PCS_a070_inputVDelta m70 : 20|10@1+ (0.1,0) [0|102.3] "V" Vector__XXX
 SG_ PCS_a070_inputVrms m70 : 30|10@1+ (0.5,0) [0|511.5] "V" Vector__XXX
 SG_ PCS_a070_intBusV m70 : 40|9@1+ (1,0) [0|511] "V" Vector__XXX
 SG_ PCS_a070_inputFrequency m70 : 49|9@1+ (0.1,40) [40|91.1] "Hz" Vector__XXX
 SG_ PCS_a071_phState m71 : 16|4@1+ (1,0) [0|15] "" Vector__XXX
 SG_ PCS_a071_inputVrms m71 : 20|10@1+ (0.5,0) [0|511.5] "V" Vector__XXX
 SG_ PCS_a071_intBusV m71 : 30|9@1+ (1,0) [0|511] "V" Vector__XXX
 SG_ PCS_a071_inputFrequency m71 : 39|9@1+ (0.1,40) [40|91.1] "Hz" Vector__XXX
 SG_ PCS_a071_llcFrequency m71 : 48|8@1+ (1,50) [50|305] "kHz" Vector__XXX
 SG_ PCS_a072_task1Stopped m72 : 16|1@1+ (1,0) [0|1] "" Vector__XXX
 SG_ PCS_a072_task2Stopped m72 : 17|1@1+ (1,0) [0|1] "" Vector__XXX
 SG_ PCS_a073_inputL1NVrms m73 : 16|9@1+ (1,0) [0|511] "V" Vector__XXX
 SG_ PCS_a073_inputL2NVrms m73 : 25|9@1+ (1,0) [0|511] "V" Vector__XXX
 SG_ PCS_a073_inputL3NVrms m73 : 34|9@1+ (1,0) [0|511] "V" Vector__XXX
 SG_ PCS_a073_inputNGVrms m73 : 43|9@1+ (1,0) [0|511] "V" Vector__XXX
 SG_ PCS_a073_phaseConfig m73 : 52|4@1+ (1,0) [1|15] "" Vector__XXX
 SG_ PCS_a073_cpType m73 : 56|2@1+ (1,0) [0|3] "" Vector__XXX
 SG_ PCS_a074_dcdcLvBusV m74 : 16|10@1+ (0.0390625,0) [0|39.9609375] "V" Vector__XXX
 SG_ PCS_a074_dcdcHvBusV m74 : 26|12@1+ (0.146484375,0) [0|599.853515625] "V" Vector__XXX
 SG_ PCS_a075_dcdcLvBusV m75 : 16|10@1+ (0.0390625,0) [0|39.9609375] "V" Vector__XXX
 SG_ PCS_a075_dcdcHvBusV m75 : 26|12@1+ (0.146484375,0) [0|599.853515625] "V" Vector__XXX
 SG_ PCS_a075_dcdcSubState m75 : 40|5@1+ (1,0) [0|31] "" Vector__XXX
 SG_ PCS_a076_pcsControlRequest m76 : 16|2@1+ (1,0) [0|3] "" Vector__XXX
 SG_ PCS_a076_dcdcSubState m76 : 18|5@1+ (1,0) [0|31] "" Vector__XXX
 SG_ PCS_a076_dcdcEnableLine m76 : 23|1@1+ (1,0) [0|1] "" Vector__XXX
 SG_ PCS_a076_dcdcPwmEnableDeasserted m76 : 24|8@1+ (1,0) [0|255] "" Vector__XXX
 SG_ PCS_a078_phaTemperature m78 : 16|8@1- (1,40) [-88|167] "C" Vector__XXX
 SG_ PCS_a078_phbTemperature m78 : 24|8@1- (1,40) [-88|167] "C" Vector__XXX
 SG_ PCS_a078_phcTemperature m78 : 32|8@1- (1,40) [-88|167] "C" Vector__XXX
 SG_ PCS_a078_dcdcTemperature m78 : 40|8@1- (1,40) [-88|167] "C" Vector__XXX
 SG_ PCS_a078_ptCoolantTemp m78 : 48|8@1- (1,40) [-88|167] "C" Vector__XXX
 SG_ PCS_a079_eepromOperation m79 : 16|4@1+ (1,0) [0|14] "" Vector__XXX
 SG_ PCS_a079_eepromOperationRegion m79 : 20|2@1+ (1,0) [0|3] "" Vector__XXX
 SG_ PCS_a079_recordID m79 : 24|8@1+ (1,0) [0|255] "" Vector__XXX
 SG_ PCS_a079_eepromOperationErrorCod m79 : 32|5@1+ (1,0) [0|31] "" Vector__XXX
 SG_ PCS_a079_operationAddress m79 : 40|16@1+ (1,0) [0|65535] "" Vector__XXX
 SG_ PCS_a079_eepromErrorCount m79 : 56|5@1+ (1,0) [0|31] "" Vector__XXX
 SG_ PCS_a080_phADamaged m80 : 16|1@1+ (1,0) [0|1] "" Vector__XXX
 SG_ PCS_a080_phBDamaged m80 : 17|1@1+ (1,0) [0|1] "" Vector__XXX
 SG_ PCS_a080_phCDamaged m80 : 18|1@1+ (1,0) [0|1] "" Vector__XXX
 SG_ PCS_a080_phANVRAMStoredState m80 : 19|3@1+ (1,0) [0|7] "" Vector__XXX
 SG_ PCS_a080_phBNVRAMStoredState m80 : 24|3@1+ (1,0) [0|7] "" Vector__XXX
 SG_ PCS_a080_phCNVRAMStoredState m80 : 27|3@1+ (1,0) [0|7] "" Vector__XXX
 SG_ PCS_a081_dcdcLvBusV m81 : 16|10@1+ (0.0390625,0) [0|39.9609375] "V" Vector__XXX
 SG_ PCS_a081_dcdcHvBusV m81 : 26|12@1+ (0.146484375,0) [0|599.853515625] "V" Vector__XXX
 SG_ PCS_a081_faultedSubstate m81 : 40|5@1+ (1,0) [0|31] "" Vector__XXX
 SG_ PCS_a082_dcdcLvBusV m82 : 16|10@1+ (0.0390625,0) [0|39.9609375] "V" Vector__XXX
 SG_ PCS_a082_dcdcHvBusV m82 : 26|12@1+ (0.146484375,0) [0|599.853515625] "V" Vector__XXX
 SG_ PCS_a082_faultedSubstate m82 : 40|5@1+ (1,0) [0|31] "" Vector__XXX
 SG_ PCS_a085_dcdcHalfPeriodUs m85 : 16|16@1+ (0.005,0) [0|327.675] "us" Vector__XXX
 SG_ PCS_a086_dcdcTemperature m86 : 16|12@1- (0.1,0) [-204.8|204.7] "C" Vector__XXX
 SG_ PCS_a086_pcsAmbientTemperature m86 : 28|12@1- (0.1,0) [-204.8|204.7] "C" Vector__XXX
 SG_ PCS_a086_vcfrontPTCoolantTemp m86 : 40|12@1- (0.1,0) [-204.8|204.7] "C" Vector__XXX
 SG_ PCS_a088_gridConfig m88 : 16|4@1+ (1,0) [1|15] "" Vector__XXX
 SG_ PCS_a088_phAFrequency m88 : 20|12@1+ (0.01,40) [40|80.95] "Hz" Vector__XXX
 SG_ PCS_a088_phBFrequency m88 : 32|12@1+ (0.01,40) [40|80.95] "Hz" Vector__XXX
 SG_ PCS_a088_phCFrequency m88 : 44|12@1+ (0.01,40) [40|80.95] "Hz" Vector__XXX
 SG_ PCS_a089_hvSlewRate m89 : 16|8@1- (2,0) [-256|254] "V/sec" Vector__XXX
 SG_ PCS_a089_avgSlewRate m89 : 24|8@1- (2,0) [-256|254] "V/sec" Vector__XXX
 SG_ PCS_a089_G m89 : 32|4@1+ (0.2,0) [0|3] "-" Vector__XXX
 SG_ PCS_a089_HV_busV m89 : 36|9@1+ (0.8203125,0) [0|419.1796875] "V" Vector__XXX
 SG_ PCS_a089_PhaseShift m89 : 45|5@1+ (0.5,0) [0|15.5] "-" Vector__XXX
 SG_ PCS_a089_Freq m89 : 50|9@1+ (1,0) [0|511] "kHz" Vector__XXX
 SG_ PCS_a089_fastDischargeMode m89 : 59|1@1+ (1,0) [0|1] "" Vector__XXX
 SG_ PCS_a089_slowDischargeMode m89 : 60|1@1+ (1,0) [0|1] "" Vector__XXX
 SG_ PCS_a090_vRmsL1N m90 : 16|9@1+ (1,0) [0|511] "V" Vector__XXX
 SG_ PCS_a090_vRmsL2N m90 : 25|9@1+ (1,0) [0|511] "V" Vector__XXX
 SG_ PCS_a090_vRmsL3N m90 : 34|9@1+ (1,0) [0|511] "V" Vector__XXX
 SG_ PCS_a090_vRmsL1L2 m90 : 43|9@1+ (1,0) [0|511] "V" Vector__XXX
 SG_ PCS_a090_evaluatedGridConfig m90 : 52|4@1+ (1,0) [1|15] "" Vector__XXX
 SG_ PCS_a090_phASourceMissing m90 : 56|1@1+ (1,0) [0|1] "" Vector__XXX
 SG_ PCS_a090_phBSourceMissing m90 : 57|1@1+ (1,0) [0|1] "" Vector__XXX
 SG_ PCS_a090_phCSourceMissing m90 : 58|1@1+ (1,0) [0|1] "" Vector__XXX
 SG_ PCS_a091_intBusTarget m91 : 16|9@1+ (1,0) [0|511] "V" Vector__XXX
 SG_ PCS_a091_intBusMaxRippleLevel m91 : 25|9@1+ (0.1,0) [0|51.1] "V" Vector__XXX
 SG_ PCS_a091_pfcCurrentIrms m91 : 34|8@1+ (0.1,0) [0|25.5] "A" Vector__XXX
 SG_ PCS_a091_phaseInputVrms m91 : 42|9@1+ (1,0) [0|511] "A" Vector__XXX
 SG_ PCS_a091_phaseTemp m91 : 51|8@1- (1,0) [-128|127] "C" Vector__XXX
 SG_ PCS_a092_pfcIrmsPhA m92 : 16|7@1+ (0.2,0) [0|25.4] "A" Vector__XXX
 SG_ PCS_a092_pfcIrmsPhB m92 : 23|7@1+ (0.2,0) [0|25.4] "A" Vector__XXX
 SG_ PCS_a092_pfcIrmsPhC m92 : 30|7@1+ (0.2,0) [0|25.4] "A" Vector__XXX
 SG_ PCS_a092_chgTempPhA m92 : 37|8@1- (1,40) [-88|167] "C" Vector__XXX
 SG_ PCS_a092_chgTempPhB m92 : 45|8@1- (1,40) [-88|167] "C" Vector__XXX
 SG_ PCS_a092_chgTempPhC m92 : 53|8@1- (1,40) [-88|167] "C" Vector__XXX
 SG_ PCS_a093_powerRail5VN m93 : 16|10@1+ (0.01,0) [0|10.23] "V" Vector__XXX
 SG_ PCS_a093_powerRail3V3 m93 : 26|10@1+ (0.01,0) [0|10.23] "V" Vector__XXX
 SG_ PCS_a093_powerRail1V5 m93 : 40|8@1+ (0.01,0) [0|2.55] "V" Vector__XXX
 SG_ PCS_a093_powerRail1V2 m93 : 48|8@1+ (0.01,0) [0|2.55] "V" Vector__XXX
 SG_ PCS_a093_irrational1V2Rail m93 : 56|1@1+ (1,0) [0|1] "" Vector__XXX
 SG_ PCS_a093_irrational1V5Rail m93 : 57|1@1+ (1,0) [0|1] "" Vector__XXX
 SG_ PCS_a093_irrational3V3Rail m93 : 58|1@1+ (1,0) [0|1] "" Vector__XXX
 SG_ PCS_a093_irrational5VNRail m93 : 59|1@1+ (1,0) [0|1] "" Vector__XXX
 SG_ PCS_a094_malfunctionCode m94 : 16|2@1+ (1,0) [0|3] "" Vector__XXX
 SG_ PCS_a095_powerRail5VN m95 : 16|10@1+ (0.01,0) [0|10.23] "V" Vector__XXX
 SG_ PCS_a095_pcsControlRequest m95 : 26|2@1+ (1,0) [0|3] "" Vector__XXX
 SG_ PCS_a096_gridConfig m96 : 16|4@1+ (1,0) [1|15] "" Vector__XXX
 SG_ PCS_a096_phAFrequency m96 : 20|12@1+ (0.01,40) [40|80.95] "Hz" Vector__XXX
 SG_ PCS_a096_phBFrequency m96 : 32|12@1+ (0.01,40) [40|80.95] "Hz" Vector__XXX
 SG_ PCS_a096_phCFrequency m96 : 44|12@1+ (0.01,40) [40|80.95] "Hz" Vector__XXX
 SG_ PCS_a097_phADamaged m97 : 16|1@1+ (1,0) [0|1] "" Vector__XXX
 SG_ PCS_a097_phBDamaged m97 : 17|1@1+ (1,0) [0|1] "" Vector__XXX
 SG_ PCS_a097_phCDamaged m97 : 18|1@1+ (1,0) [0|1] "" Vector__XXX
 SG_ PCS_a097_phANVRAMStoredState m97 : 19|3@1+ (1,0) [0|7] "" Vector__XXX
 SG_ PCS_a097_phBNVRAMStoredState m97 : 24|3@1+ (1,0) [0|7] "" Vector__XXX
 SG_ PCS_a097_phCNVRAMStoredState m97 : 27|3@1+ (1,0) [0|7] "" Vector__XXX
 SG_ PCS_a100_inputVrms m100 : 16|9@1+ (1,0) [0|511] "V" Vector__XXX
 SG_ PCS_a100_phIntBusVolt m100 : 25|9@1+ (1,0) [0|511] "V" Vector__XXX
 SG_ PCS_a100_phKwhCounter m100 : 34|13@1+ (1,0) [0|8191] "kwh" Vector__XXX
 SG_ PCS_a100_phKwhCounterDeltaFromMa m100 : 48|13@1+ (1,0) [0|8191] "kwh" Vector__XXX
 SG_ PCS_a102_pcsControlRequest m102 : 16|2@1+ (1,0) [0|3] "" Vector__XXX
 SG_ PCS_a102_NMIFlagRegisters m102 : 18|11@1+ (1,0) [0|2047] "" Vector__XXX
 SG_ PCS_a102_systemResetRegisters m102 : 29|11@1+ (1,0) [0|2047] "" Vector__XXX
 SG_ PCS_a102_dcdcEnableLine m102 : 40|1@1+ (1,0) [0|1] "" Vector__XXX
 SG_ PCS_a104_ambientTemperature m104 : 16|11@1- (0.1,40) [-62.4|142.3] "C" Vector__XXX
 SG_ PCS_a107_VC_pcsInterface m107 : 16|1@1+ (1,0) [0|1] "" Vector__XXX
 SG_ PCS_a108_installedInAWrongPlatfo m108 : 16|1@1+ (1,0) [0|1] "" Vector__XXX
 SG_ PCS_a109_inputL2NVrms m109 : 16|9@1+ (1,0) [0|511] "V" Vector__XXX
 SG_ PCS_a109_inputL3NVrms m109 : 25|9@1+ (1,0) [0|511] "V" Vector__XXX

BO_ 932 PCS_alertMatrix: 8 PCS
 SG_ PCS_matrixIndex M : 0|4@1+ (1,0) [0|15] "" Vector__XXX
 SG_ PCS_a001_chgHwInputOc m0 : 4|1@1+ (1,0) [0|1] "" Vector__XXX
 SG_ PCS_a002_chgHwOutputOc m0 : 5|1@1+ (1,0) [0|1] "" Vector__XXX
 SG_ PCS_a003_chgHwInputOv m0 : 6|1@1+ (1,0) [0|1] "" Vector__XXX
 SG_ PCS_a004_chgHwIntBusOv m0 : 7|1@1+ (1,0) [0|1] "" Vector__XXX
 SG_ PCS_a005_chgOutputOv m0 : 8|1@1+ (1,0) [0|1] "" Vector__XXX
 SG_ PCS_a006_chgPrechargeFailedScr m0 : 9|1@1+ (1,0) [0|1] "" Vector__XXX
 SG_ PCS_a007_chgPhaseTempHot m0 : 10|1@1+ (1,0) [0|1] "" Vector__XXX
 SG_ PCS_a008_chgPhaseOverTemp m0 : 11|1@1+ (1,0) [0|1] "" Vector__XXX
 SG_ PCS_a009_chgPfcCurrentRegulation m0 : 12|1@1+ (1,0) [0|1] "" Vector__XXX
 SG_ PCS_a010_chgIntBusVRegulation m0 : 13|1@1+ (1,0) [0|1] "" Vector__XXX
 SG_ PCS_a011_chgLlcCurrentRegulation m0 : 14|1@1+ (1,0) [0|1] "" Vector__XXX
 SG_ PCS_a012_chgPfcIBandTracerFault m0 : 15|1@1+ (1,0) [0|1] "" Vector__XXX
 SG_ PCS_a013_chgPrechargeFailedBoost m0 : 16|1@1+ (1,0) [0|1] "" Vector__XXX
 SG_ PCS_a014_chgTempRationality m0 : 17|1@1+ (1,0) [0|1] "" Vector__XXX
 SG_ PCS_a015_chg12vUv m0 : 18|1@1+ (1,0) [0|1] "" Vector__XXX
 SG_ PCS_a016_chgAllPhasesFaulted m0 : 19|1@1+ (1,0) [0|1] "" Vector__XXX
 SG_ PCS_a017_chgWallPowerRemoval m0 : 20|1@1+ (1,0) [0|1] "" Vector__XXX
 SG_ PCS_a018_chgUnknownGridConfig m0 : 21|1@1+ (1,0) [0|1] "" Vector__XXX
 SG_ PCS_a019_acChargePowerLimited m0 : 22|1@1+ (1,0) [0|1] "" Vector__XXX
 SG_ PCS_a020_chgEnableLineMismatch m0 : 23|1@1+ (1,0) [0|1] "" Vector__XXX
 SG_ PCS_a021_hvpMia m0 : 24|1@1+ (1,0) [0|1] "" Vector__XXX
 SG_ PCS_a022_bmsMia m0 : 25|1@1+ (1,0) [0|1] "" Vector__XXX
 SG_ PCS_a023_cpMia m0 : 26|1@1+ (1,0) [0|1] "" Vector__XXX
 SG_ PCS_a024_vcfrontMia m0 : 27|1@1+ (1,0) [0|1] "" Vector__XXX
 SG_ PCS_a025_cpu2Malfunction m0 : 28|1@1+ (1,0) [0|1] "" Vector__XXX
 SG_ PCS_a026_watchdogAlarmed m0 : 29|1@1+ (1,0) [0|1] "" Vector__XXX
 SG_ PCS_a027_chgInsufficientCooling m0 : 30|1@1+ (1,0) [0|1] "" Vector__XXX
 SG_ PCS_a028_chgOutputUv m0 : 31|1@1+ (1,0) [0|1] "" Vector__XXX
 SG_ PCS_a029_chgPowerRationality m0 : 32|1@1+ (1,0) [0|1] "" Vector__XXX
 SG_ PCS_a030_canRationality m0 : 33|1@1+ (1,0) [0|1] "" Vector__XXX
 SG_ PCS_a031_uiMia m0 : 34|1@1+ (1,0) [0|1] "" Vector__XXX
 SG_ PCS_a032_excessiveGridTransients m0 : 35|1@1+ (1,0) [0|1] "" Vector__XXX
 SG_ PCS_a033_hvBusUv m0 : 36|1@1+ (1,0) [0|1] "" Vector__XXX
 SG_ PCS_a034_hvBusOv m0 : 37|1@1+ (1,0) [0|1] "" Vector__XXX
 SG_ PCS_a035_lvBusUv m0 : 38|1@1+ (1,0) [0|1] "" Vector__XXX
 SG_ PCS_a036_lvBusOv m0 : 39|1@1+ (1,0) [0|1] "" Vector__XXX
 SG_ PCS_a037_resonantTankOc m0 : 40|1@1+ (1,0) [0|1] "" Vector__XXX
 SG_ PCS_a038_claFaulted m0 : 41|1@1+ (1,0) [0|1] "" Vector__XXX
 SG_ PCS_a039_sdModuleClkFault m0 : 42|1@1+ (1,0) [0|1] "" Vector__XXX
 SG_ PCS_a040_dcdcMaxPowerReached m0 : 43|1@1+ (1,0) [0|1] "" Vector__XXX
 SG_ PCS_a041_dcdcOverTemp m0 : 44|1@1+ (1,0) [0|1] "" Vector__XXX
 SG_ PCS_a042_dcdcEnableLineMismatch m0 : 45|1@1+ (1,0) [0|1] "" Vector__XXX
 SG_ PCS_a043_hvBusPrechargeFailure m0 : 46|1@1+ (1,0) [0|1] "" Vector__XXX
 SG_ PCS_a044_12vSupportRegulation m0 : 47|1@1+ (1,0) [0|1] "" Vector__XXX
 SG_ PCS_a045_hvBusLowImpedance m0 : 48|1@1+ (1,0) [0|1] "" Vector__XXX
 SG_ PCS_a046_hvBusHighImpedence m0 : 49|1@1+ (1,0) [0|1] "" Vector__XXX
 SG_ PCS_a047_bootloaderCrcMismatch m0 : 50|1@1+ (1,0) [0|1] "" Vector__XXX
 SG_ PCS_a048_softwareAssertion m0 : 51|1@1+ (1,0) [0|1] "" Vector__XXX
 SG_ PCS_a049_dcdcTempRationality m0 : 52|1@1+ (1,0) [0|1] "" Vector__XXX
 SG_ PCS_a050_dcdc12VsupportFaulted m0 : 53|1@1+ (1,0) [0|1] "" Vector__XXX
 SG_ PCS_a051_chgIntBusUv m0 : 54|1@1+ (1,0) [0|1] "" Vector__XXX
 SG_ PCS_a052_acVoltageNotPresent m0 : 55|1@1+ (1,0) [0|1] "" Vector__XXX
 SG_ PCS_a053_chgInputVDropHigh m0 : 56|1@1+ (1,0) [0|1] "" Vector__XXX
 SG_ PCS_a054_chgInputVDropTooHigh m0 : 57|1@1+ (1,0) [0|1] "" Vector__XXX
 SG_ PCS_a055_chgLineImpedanceHigh m0 : 58|1@1+ (1,0) [0|1] "" Vector__XXX
 SG_ PCS_a056_chgLineImpedanceTooHigh m0 : 59|1@1+ (1,0) [0|1] "" Vector__XXX
 SG_ PCS_a057_chgInputOverFreq m0 : 60|1@1+ (1,0) [0|1] "" Vector__XXX
 SG_ PCS_a058_chgInputUnderFreq m0 : 61|1@1+ (1,0) [0|1] "" Vector__XXX
 SG_ PCS_a059_chgInputOvRms m0 : 62|1@1+ (1,0) [0|1] "" Vector__XXX
 SG_ PCS_a060_chgInputOvPeak m0 : 63|1@1+ (1,0) [0|1] "" Vector__XXX
 SG_ PCS_a061_chgVLineRationality m1 : 4|1@1+ (1,0) [0|1] "" Vector__XXX
 SG_ PCS_a062_chgILineRationality m1 : 5|1@1+ (1,0) [0|1] "" Vector__XXX
 SG_ PCS_a063_chgVOutRationality m1 : 6|1@1+ (1,0) [0|1] "" Vector__XXX
 SG_ PCS_a064_chgIOutRationality m1 : 7|1@1+ (1,0) [0|1] "" Vector__XXX
 SG_ PCS_a065_chgPllNotLocked m1 : 8|1@1+ (1,0) [0|1] "" Vector__XXX
 SG_ PCS_a066_dcdcHvRationality m1 : 9|1@1+ (1,0) [0|1] "" Vector__XXX
 SG_ PCS_a067_dcdcLvRationality m1 : 10|1@1+ (1,0) [0|1] "" Vector__XXX
 SG_ PCS_a068_dcdcTankvRationality m1 : 11|1@1+ (1,0) [0|1] "" Vector__XXX
 SG_ PCS_a069_chgPfcLineDidt m1 : 12|1@1+ (1,0) [0|1] "" Vector__XXX
 SG_ PCS_a070_chgPfcLineDvdt m1 : 13|1@1+ (1,0) [0|1] "" Vector__XXX
 SG_ PCS_a071_chgPfcILoopRationality m1 : 14|1@1+ (1,0) [0|1] "" Vector__XXX
 SG_ PCS_a072_cpu2ClaStopped m1 : 15|1@1+ (1,0) [0|1] "" Vector__XXX
 SG_ PCS_a073_unexpectedAcInputVoltag m1 : 16|1@1+ (1,0) [0|1] "" Vector__XXX
 SG_ PCS_a074_hvBusDischargeFailure m1 : 17|1@1+ (1,0) [0|1] "" Vector__XXX
 SG_ PCS_a075_hvBusDischargeTimeout m1 : 18|1@1+ (1,0) [0|1] "" Vector__XXX
 SG_ PCS_a076_dcdcEnDeassertedErr m1 : 19|1@1+ (1,0) [0|1] "" Vector__XXX
 SG_ PCS_a077_microGridWobbleDetected m1 : 20|1@1+ (1,0) [0|1] "" Vector__XXX
 SG_ PCS_a078_chgStopDcdcTooHot m1 : 21|1@1+ (1,0) [0|1] "" Vector__XXX
 SG_ PCS_a079_eepromOperationError m1 : 22|1@1+ (1,0) [0|1] "" Vector__XXX
 SG_ PCS_a080_damagedPhaseDetected m1 : 23|1@1+ (1,0) [0|1] "" Vector__XXX
 SG_ PCS_a081_dcdcPchgTimeout m1 : 24|1@1+ (1,0) [0|1] "" Vector__XXX
 SG_ PCS_a082_dcdcPchgUnsafeDiVoltage m1 : 25|1@1+ (1,0) [0|1] "" Vector__XXX
 SG_ PCS_a083_triggerOdin m1 : 26|1@1+ (1,0) [0|1] "" Vector__XXX
 SG_ PCS_a084_vDropFastInParasiticDio m1 : 27|1@1+ (1,0) [0|1] "" Vector__XXX
 SG_ PCS_a085_dcdcFetsNotSwitching m1 : 28|1@1+ (1,0) [0|1] "" Vector__XXX
 SG_ PCS_a086_dcdcInsufficientCooling m1 : 29|1@1+ (1,0) [0|1] "" Vector__XXX
 SG_ PCS_a087_nvramRecordStatusError m1 : 30|1@1+ (1,0) [0|1] "" Vector__XXX
 SG_ PCS_a088_gridFreqDroopDetected m1 : 31|1@1+ (1,0) [0|1] "" Vector__XXX
 SG_ PCS_a089_hvBusDischargeIrrationa m1 : 32|1@1+ (1,0) [0|1] "" Vector__XXX
 SG_ PCS_a090_expectedAcVoltageSource m1 : 33|1@1+ (1,0) [0|1] "" Vector__XXX
 SG_ PCS_a091_chgIntBusRationality m1 : 34|1@1+ (1,0) [0|1] "" Vector__XXX
 SG_ PCS_a092_chgPowerLimitedByBusRip m1 : 35|1@1+ (1,0) [0|1] "" Vector__XXX
 SG_ PCS_a093_powerRailRationality m1 : 36|1@1+ (1,0) [0|1] "" Vector__XXX
 SG_ PCS_a094_pcsDcdcNeedService m1 : 37|1@1+ (1,0) [0|1] "" Vector__XXX
 SG_ PCS_a095_dcdcSensorlessModeActiv m1 : 38|1@1+ (1,0) [0|1] "" Vector__XXX
 SG_ PCS_a096_microGridOverLoaded m1 : 39|1@1+ (1,0) [0|1] "" Vector__XXX
 SG_ PCS_a097_rebootPhaseDetected m1 : 40|1@1+ (1,0) [0|1] "" Vector__XXX
 SG_ PCS_a098_gridFreqDroopDetectedSi m1 : 41|1@1+ (1,0) [0|1] "" Vector__XXX
 SG_ PCS_a099_microGridOverLoadedSile m1 : 42|1@1+ (1,0) [0|1] "" Vector__XXX
 SG_ PCS_a100_suspectedViperChipIssue m1 : 43|1@1+ (1,0) [0|1] "" Vector__XXX
 SG_ PCS_a101_phMachineModelIrrationa m1 : 44|1@1+ (1,0) [0|1] "" Vector__XXX
 SG_ PCS_a102_resetWithDCDCCmdAsserte m1 : 45|1@1+ (1,0) [0|1] "" Vector__XXX
 SG_ PCS_a103_pchgWithLowLvDetected m1 : 46|1@1+ (1,0) [0|1] "" Vector__XXX
 SG_ PCS_a104_ambientTempRationality m1 : 47|1@1+ (1,0) [0|1] "" Vector__XXX
 SG_ PCS_a105_redundantVoltageSourceI m1 : 48|1@1+ (1,0) [0|1] "" Vector__XXX
 SG_ PCS_a106_clockSourceNotFromExter m1 : 49|1@1+ (1,0) [0|1] "" Vector__XXX
 SG_ PCS_a107_vcPcsDCDCInterfaceMia m1 : 50|1@1+ (1,0) [0|1] "" Vector__XXX
 SG_ PCS_a108_misconfigurationDetecte m1 : 51|1@1+ (1,0) [0|1] "" Vector__XXX
 SG_ PCS_a109_deltaChargingL2L3Swappe m1 : 52|1@1+ (1,0) [0|1] "" Vector__XXX

BO_ 612 PCS_chgLineStatus: 6 PCS
 SG_ PCS_chgInputVoltage : 0|14@1+ (0.033,0) [0|540.639] "V" Vector__XXX
 SG_ PCS_chgLineCurrent : 14|9@1+ (0.1,0) [0|50] "A" Vector__XXX
 SG_ PCS_chgAcVoltagePresent : 23|1@1+ (1,0) [0|1] "" Vector__XXX
 SG_ PCS_chgInputPower : 24|8@1+ (0.1,0) [0|20] "kW" Vector__XXX
 SG_ PCS_chgAcCurrentLimit : 32|10@1+ (0.1,0) [0|102.3] "A" Vector__XXX

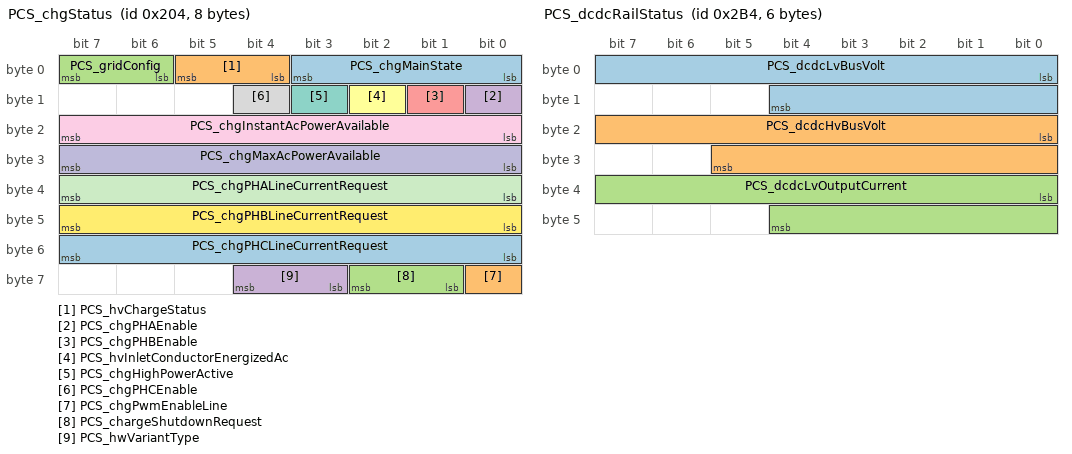
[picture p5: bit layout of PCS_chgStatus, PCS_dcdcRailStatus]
BO_ 516 PCS_chgStatus: 8 PCS
 SG_ PCS_chgMainState : 0|4@1+ (1,0) [0|15] "" Vector__XXX
 SG_ PCS_hvChargeStatus : 4|2@1+ (1,0) [0|3] "" Vector__XXX
 SG_ PCS_gridConfig : 6|2@1+ (1,0) [1|3] "" Vector__XXX
 SG_ PCS_chgPHAEnable : 8|1@1+ (1,0) [0|1] "" Vector__XXX
 SG_ PCS_chgPHBEnable : 9|1@1+ (1,0) [0|1] "" Vector__XXX
 SG_ PCS_hvInletConductorEnergizedAc : 10|1@1+ (1,0) [0|1] "" Vector__XXX
 SG_ PCS_chgHighPowerActive : 11|1@1+ (1,0) [0|1] "" Vector__XXX
 SG_ PCS_chgPHCEnable : 12|1@1+ (1,0) [0|1] "" Vector__XXX
 SG_ PCS_chgInstantAcPowerAvailable : 16|8@1+ (0.1,0) [0|20] "kW" Vector__XXX
 SG_ PCS_chgMaxAcPowerAvailable : 24|8@1+ (0.1,0) [0|20] "kW" Vector__XXX
 SG_ PCS_chgPHALineCurrentRequest : 32|8@1+ (0.1,0) [0|20] "A" Vector__XXX
 SG_ PCS_chgPHBLineCurrentRequest : 40|8@1+ (0.1,0) [0|20] "A" Vector__XXX
 SG_ PCS_chgPHCLineCurrentRequest : 48|8@1+ (0.1,0) [0|20] "A" Vector__XXX
 SG_ PCS_chgPwmEnableLine : 56|1@1+ (1,0) [0|1] "" Vector__XXX
 SG_ PCS_chargeShutdownRequest : 57|2@1+ (1,0) [0|3] "" Vector__XXX
 SG_ PCS_hwVariantType : 59|2@1+ (1,0) [0|2] "" Vector__XXX

BO_ 692 PCS_dcdcRailStatus: 6 PCS
 SG_ PCS_dcdcLvBusVolt : 0|13@1+ (0.01,0) [0|80] "V" Vector__XXX
 SG_ PCS_dcdcHvBusVolt : 16|14@1+ (0.1,0) [0|1600] "V" Vector__XXX
 SG_ PCS_dcdcLvOutputCurrent : 32|13@1- (0.1,0) [-400|400] "A" Vector__XXX

BO_ 548 PCS_dcdcStatus: 8 PCS
 SG_ PCS_dcdcPrechargeStatus : 0|2@1+ (1,0) [0|3] "" Vector__XXX
 SG_ PCS_dcdcLvSupportStatus : 2|2@1+ (1,0) [0|3] "" Vector__XXX
 SG_ PCS_dcdcHvBusDischargeStatus : 4|2@1+ (1,0) [0|3] "" Vector__XXX
 SG_ PCS_coldSleepAllowed : 8|1@1+ (1,0) [0|1] "" Vector__XXX
 SG_ PCS_dcdcPchgHVBusLowRDetected : 9|1@1+ (1,0) [0|1] "" Vector__XXX
 SG_ PCS_dcdcSubState : 10|5@1+ (1,0) [0|31] "" Vector__XXX
 SG_ PCS_dcdcFaulted : 15|1@1+ (1,0) [0|1] "" Vector__XXX
 SG_ PCS_okToBePowerCycled : 27|1@1+ (1,0) [0|1] "" Vector__XXX
 SG_ PCS_dcdcOutputIsLimited : 28|1@1+ (1,0) [0|1] "" Vector__XXX
 SG_ PCS_dcdcMaxOutputCurrentAllowed : 29|12@1+ (0.1,0) [0|400] "A" Vector__XXX
 SG_ PCS_dcdcPrechargeRtyCnt : 41|3@1+ (1,0) [0|7] "" Vector__XXX
 SG_ PCS_dcdcLvSupportRtyCnt : 44|4@1+ (1,0) [0|15] "" Vector__XXX
 SG_ PCS_dcdcDischargeRtyCnt : 48|4@1+ (1,0) [0|15] "" Vector__XXX
 SG_ PCS_dcdcPwmEnableLine : 52|1@1+ (1,0) [0|1] "" Vector__XXX
 SG_ PCS_dcdcSupportingFixedLvTarget : 53|1@1+ (1,0) [0|1] "" Vector__XXX
 SG_ PCS_ecuLogUploadRequest : 54|2@1+ (1,0) [0|3] "" Vector__XXX
 SG_ PCS_dcdcPrechargeRestartCnt : 56|3@1+ (1,0) [0|7] "" Vector__XXX
 SG_ PCS_dcdcInitialPrechargeSubState : 59|5@1+ (1,0) [0|31] "" Vector__XXX

BO_TX_BU_ 862 : PARK;
BO_TX_BU_ 926 : PARK;
BO_TX_BU_ 606 : PARK;
BO_TX_BU_ 542 : PARK;
BO_TX_BU_ 590 : PARK;
BO_TX_BU_ 526 : PARK;
BO_TX_BU_ 558 : PARK;
BO_TX_BU_ 814 : PARK;
BO_TX_BU_ 830 : PARK;
BO_TX_BU_ 799 : PARK;
BO_TX_BU_ 782 : PARK;
BO_TX_BU_ 1630 : PARK;
BO_TX_BU_ 894 : PARK;
BO_TX_BU_ 1060 : PCS;
BO_TX_BU_ 932 : PCS;
BO_TX_BU_ 612 : PCS;
BO_TX_BU_ 516 : PCS;
BO_TX_BU_ 692 : PCS;
BO_TX_BU_ 548 : PCS;
CM_ BO_ 862 "Parking assist sensors message: pas rear middle";
CM_ SG_ 862 PARK_rearLeftMiddleRawDistData "Zone defined as -124 degrees to -166 degrees, distance to object in units of centimeters; raw 255 = signal not available (SNA)";
CM_ SG_ 862 PARK_rearMiddleRawDistData "Zone defined as -166 degrees to +166 degrees, distance to object in units of centimeters; raw 255 = signal not available (SNA)";
CM_ SG_ 862 PARK_rearRightMiddleRawDistData "Zone defined as +166 degrees to +124 degrees, distance to object in units of centimeters; raw 255 = signal not available (SNA)";
CM_ SG_ 862 PARK_pasRearMiddleCounter "Parking assist sensors: pas rear middle counter";
CM_ SG_ 862 PARK_pasRearMiddleChecksum "Parking assist sensors: pas rear middle checksum";
CM_ BO_ 926 "Parking assist sensors message: pas sides";
CM_ SG_ 926 PARK_rightSideFrontRawDistData "Right side (from inside the car) towards the front of the car (split evenly between axles); raw 255 = signal not available (SNA)";
CM_ SG_ 926 PARK_rightSideRearRawDistData "Right side (from inside the car) towards the rear of the car (split evenly between axles); raw 255 = signal not available (SNA)";
CM_ SG_ 926 PARK_leftSideFrontRawDistData "Left side (from inside the car) towards the front of the car (split evenly between axles); raw 255 = signal not available (SNA)";
CM_ SG_ 926 PARK_leftSideRearRawDistData "Left side (from inside the car) towards the rear of the car (split evenly between axles); raw 255 = signal not available (SNA)";
CM_ SG_ 926 PARK_pasSidesCounter "Parking assist sensors: pas sides counter";
CM_ SG_ 926 PARK_pasSidesChecksum "Parking assist sensors: pas sides checksum";
CM_ BO_ 606 "Parking assist sensors message: psc env slot";
CM_ SG_ 606 PARK_pscEnvSlotType "Parking assist sensors: psc env slot type";
CM_ SG_ 606 PARK_pscLeftParallelObj1X "Parking assist sensors: psc left parallel obj1 x; raw 2047 = signal not available (SNA)";
CM_ SG_ 606 PARK_pscLeftParallelObj1Y "Parking assist sensors: psc left parallel obj1 y; raw 2047 = signal not available (SNA)";
CM_ SG_ 606 PARK_pscLeftParallelObj1Alpha "Parking assist sensors: psc left parallel obj1 alpha; raw 127 = signal not available (SNA)";
CM_ SG_ 606 PARK_pscLeftParallelObj2Y "Parking assist sensors: psc left parallel obj2 y; raw 2047 = signal not available (SNA)";
CM_ SG_ 606 PARK_pscLeftParallelObj2X "Parking assist sensors: psc left parallel obj2 x; raw 2047 = signal not available (SNA)";
CM_ SG_ 606 PARK_pscLeftParallelObj2Alpha "Parking assist sensors: psc left parallel obj2 alpha; raw 127 = signal not available (SNA)";
CM_ SG_ 606 PARK_pscLeftCrossObj1X "Parking assist sensors: psc left cross obj1 x; raw 2047 = signal not available (SNA)";
CM_ SG_ 606 PARK_pscLeftCrossObj1Y "Parking assist sensors: psc left cross obj1 y; raw 2047 = signal not available (SNA)";
CM_ SG_ 606 PARK_pscLeftCrossObj1Alpha "Parking assist sensors: psc left cross obj1 alpha; raw 127 = signal not available (SNA)";
CM_ SG_ 606 PARK_pscLeftCrossObj2Y "Parking assist sensors: psc left cross obj2 y; raw 2047 = signal not available (SNA)";
CM_ SG_ 606 PARK_pscLeftCrossObj2X "Parking assist sensors: psc left cross obj2 x; raw 2047 = signal not available (SNA)";
CM_ SG_ 606 PARK_pscLeftCrossObj2Alpha "Parking assist sensors: psc left cross obj2 alpha; raw 127 = signal not available (SNA)";
CM_ SG_ 606 PARK_pscRightParallelObj1X "Parking assist sensors: psc right parallel obj1 x; raw 2047 = signal not available (SNA)";
CM_ SG_ 606 PARK_pscRightParallelObj1Y "Parking assist sensors: psc right parallel obj1 y; raw 2047 = signal not available (SNA)";
CM_ SG_ 606 PARK_pscRightParallelObj1Alpha "Parking assist sensors: psc right parallel obj1 alpha; raw 127 = signal not available (SNA)";
CM_ SG_ 606 PARK_pscRightParallelObj2Y "Parking assist sensors: psc right parallel obj2 y; raw 2047 = signal not available (SNA)";
CM_ SG_ 606 PARK_pscRightParallelObj2X "Parking assist sensors: psc right parallel obj2 x; raw 2047 = signal not available (SNA)";
CM_ SG_ 606 PARK_pscRightParallelObj2Alpha "Parking assist sensors: psc right parallel obj2 alpha; raw 127 = signal not available (SNA)";
CM_ SG_ 606 PARK_pscRightCrossObj1X "Parking assist sensors: psc right cross obj1 x; raw 2047 = signal not available (SNA)";
CM_ SG_ 606 PARK_pscRightCrossObj1Y "Parking assist sensors: psc right cross obj1 y; raw 2047 = signal not available (SNA)";
CM_ SG_ 606 PARK_pscRightCrossObj1Alpha "Parking assist sensors: psc right cross obj1 alpha; raw 127 = signal not available (SNA)";
CM_ SG_ 606 PARK_pscRightCrossObj2Y "Parking assist sensors: psc right cross obj2 y; raw 2047 = signal not available (SNA)";
CM_ SG_ 606 PARK_pscRightCrossObj2X "Parking assist sensors: psc right cross obj2 x; raw 2047 = signal not available (SNA)";
CM_ SG_ 606 PARK_pscRightCrossObj2Alpha "Parking assist sensors: psc right cross obj2 alpha; raw 127 = signal not available (SNA)";
CM_ BO_ 542 "Parking assist sensors message: psc status";
CM_ SG_ 542 PARK_pscParkStatus "Parking assist sensors: psc park status; raw 7 = signal not available (SNA)";
CM_ SG_ 542 PARK_pscParkAbortReason "Parking assist sensors: psc park abort reason; raw 31 = signal not available (SNA)";
CM_ SG_ 542 PARK_pscParallelSpace "The existence and type of a parallel parking slot identified by the ultrasonics.";
CM_ SG_ 542 PARK_pscCrossSpace "The type and existence of perpendicular parking slot identified through the ultrasonics";
CM_ SG_ 542 PARK_pscParallelRightParkable "Whether or not there is a valid path into a parallel parking slot on the right; raw 3 = signal not available (SNA)";
CM_ SG_ 542 PARK_pscParallelLeftParkable "Whether or not there is a valid path into a parallel parking slot on the left; raw 3 = signal not available (SNA)";
CM_ SG_ 542 PARK_pscCrossRightParkable "Parking assist sensors: psc cross right parkable; raw 3 = signal not available (SNA)";
CM_ SG_ 542 PARK_pscMaxVelocity "Parking assist sensors: psc max velocity; raw 63 = signal not available (SNA)";
CM_ SG_ 542 PARK_pscCrossLeftParkable "Parking assist sensors: psc cross left parkable; raw 3 = signal not available (SNA)";
CM_ SG_ 542 PARK_pscParkInstruction "The control request from PARK ECU during autopark manuever; raw 7 = signal not available (SNA)";
CM_ SG_ 542 PARK_pscManeuverDistance "Real time updated path length from center of vehicle reference frame to desired center of vehicle at end of current parking manuever; raw 2047 = signal not available (SNA)";
CM_ SG_ 542 PARK_pscAngleActive "Parking assist sensors: psc angle active";
CM_ SG_ 542 PARK_pscAngleRequest "Parking assist sensors: psc angle request";
CM_ SG_ 542 PARK_pscStatusCounter "Parking assist sensors: psc status counter";
CM_ SG_ 542 PARK_pscStatusChecksum "Parking assist sensors: psc status checksum";
CM_ BO_ 590 "Parking assist sensors message: psc veh slot";
CM_ SG_ 590 PARK_pscVehSlotType "Parking assist sensors: psc veh slot type";
CM_ SG_ 590 PARK_pscLeftParallelVehX "Parking assist sensors: psc left parallel veh x; raw 2047 = signal not available (SNA)";
CM_ SG_ 590 PARK_pscLeftParallelVehY "Parking assist sensors: psc left parallel veh y; raw 2047 = signal not available (SNA)";
CM_ SG_ 590 PARK_pscLeftParallelPsi "Parking assist sensors: psc left parallel psi; raw 8191 = signal not available (SNA)";
CM_ SG_ 590 PARK_pscLeftParallelSizeX "Parking assist sensors: psc left parallel size x; raw 255 = signal not available (SNA)";
CM_ SG_ 590 PARK_pscLeftParallelSizeY "Parking assist sensors: psc left parallel size y; raw 255 = signal not available (SNA)";
CM_ SG_ 590 PARK_pscLeftCrossVehX "Parking assist sensors: psc left cross veh x; raw 2047 = signal not available (SNA)";
CM_ SG_ 590 PARK_pscLeftCrossVehY "Parking assist sensors: psc left cross veh y; raw 2047 = signal not available (SNA)";
CM_ SG_ 590 PARK_pscLeftCrossPsi "Parking assist sensors: psc left cross psi; raw 8191 = signal not available (SNA)";
CM_ SG_ 590 PARK_pscLeftCrossSizeX "Parking assist sensors: psc left cross size x; raw 255 = signal not available (SNA)";
CM_ SG_ 590 PARK_pscLeftCrossSizeY "Parking assist sensors: psc left cross size y; raw 255 = signal not available (SNA)";
CM_ SG_ 590 PARK_pscRightParallelVehX "Parking assist sensors: psc right parallel veh x; raw 2047 = signal not available (SNA)";
CM_ SG_ 590 PARK_pscRightParallelVehY "Parking assist sensors: psc right parallel veh y; raw 2047 = signal not available (SNA)";
CM_ SG_ 590 PARK_pscRightParallelPsi "Parking assist sensors: psc right parallel psi; raw 8191 = signal not available (SNA)";
CM_ SG_ 590 PARK_pscRightParallelSizeX "Parking assist sensors: psc right parallel size x; raw 255 = signal not available (SNA)";
CM_ SG_ 590 PARK_pscRightParallelSizeY "Parking assist sensors: psc right parallel size y; raw 255 = signal not available (SNA)";
CM_ SG_ 590 PARK_pscRightCrossVehX "Parking assist sensors: psc right cross veh x; raw 2047 = signal not available (SNA)";
CM_ SG_ 590 PARK_pscRightCrossVehY "Parking assist sensors: psc right cross veh y; raw 2047 = signal not available (SNA)";
CM_ SG_ 590 PARK_pscRightCrossPsi "Parking assist sensors: psc right cross psi; raw 8191 = signal not available (SNA)";
CM_ SG_ 590 PARK_pscRightCrossSizeX "Parking assist sensors: psc right cross size x; raw 255 = signal not available (SNA)";
CM_ SG_ 590 PARK_pscRightCrossSizeY "Parking assist sensors: psc right cross size y; raw 255 = signal not available (SNA)";
CM_ BO_ 526 "Parking assist sensors message: sdi front";
CM_ SG_ 526 PARK_sdiSensor1RawDistData "Parking assist sensors: sdi sensor1 raw dist data; raw 511 = signal not available (SNA)";
CM_ SG_ 526 PARK_sdiSensor2RawDistData "Parking assist sensors: sdi sensor2 raw dist data; raw 511 = signal not available (SNA)";
CM_ SG_ 526 PARK_sdiSensor3RawDistData "Parking assist sensors: sdi sensor3 raw dist data; raw 511 = signal not available (SNA)";
CM_ SG_ 526 PARK_sdiSensor4RawDistData "Parking assist sensors: sdi sensor4 raw dist data; raw 511 = signal not available (SNA)";
CM_ SG_ 526 PARK_sdiSensor5RawDistData "Parking assist sensors: sdi sensor5 raw dist data; raw 511 = signal not available (SNA)";
CM_ SG_ 526 PARK_sdiSensor6RawDistData "Parking assist sensors: sdi sensor6 raw dist data; raw 511 = signal not available (SNA)";
CM_ SG_ 526 PARK_sdiFrontCounter "Parking assist sensors: sdi front counter";
CM_ SG_ 526 PARK_sdiFrontChecksum "Parking assist sensors: sdi front checksum";
CM_ BO_ 558 "Parking assist sensors message: sdi rear";
CM_ SG_ 558 PARK_sdiSensor7RawDistData "Parking assist sensors: sdi sensor7 raw dist data; raw 511 = signal not available (SNA)";
CM_ SG_ 558 PARK_sdiSensor8RawDistData "Parking assist sensors: sdi sensor8 raw dist data; raw 511 = signal not available (SNA)";
CM_ SG_ 558 PARK_sdiSensor9RawDistData "Parking assist sensors: sdi sensor9 raw dist data; raw 511 = signal not available (SNA)";
CM_ SG_ 558 PARK_sdiSensor10RawDistData "Parking assist sensors: sdi sensor10 raw dist data; raw 511 = signal not available (SNA)";
CM_ SG_ 558 PARK_sdiSensor11RawDistData "Parking assist sensors: sdi sensor11 raw dist data; raw 511 = signal not available (SNA)";
CM_ SG_ 558 PARK_sdiSensor12RawDistData "Parking assist sensors: sdi sensor12 raw dist data; raw 511 = signal not available (SNA)";
CM_ SG_ 558 PARK_sdiRearCounter "Parking assist sensors: sdi rear counter";
CM_ SG_ 558 PARK_sdiRearChecksum "Parking assist sensors: sdi rear checksum";
CM_ BO_ 814 "Parking assist sensors message: sensor status front";
CM_ SG_ 814 PARK_frontRightSensorState "Reports the state of the front right ultrasonic sensor; raw 3 = signal not available (SNA)";
CM_ SG_ 814 PARK_frontRightMiddleSensorState "Reports the state of the front right middle ultrasonic sensor; raw 3 = signal not available (SNA)";
CM_ SG_ 814 PARK_frontLeftMiddleSensorState "Reports the state of the front left middle ultrasonic sensor; raw 3 = signal not available (SNA)";
CM_ SG_ 814 PARK_frontLeftSensorState "Reports the state of the front left ultrasonic sensor; raw 3 = signal not available (SNA)";
CM_ SG_ 814 PARK_frontLeftRawDistData "Zone defined as -90 degrees -> -38 degrees, distance to object in units of centimeters; raw 255 = signal not available (SNA)";
CM_ SG_ 814 PARK_frontRightRawDistData "Zone defined as +38 degrees -> +90 degrees, distance to object in units of centimeters; raw 255 = signal not available (SNA)";
CM_ SG_ 814 PARK_systemStatusFront "Parking assist sensors: system status front; raw 3 = signal not available (SNA)";
CM_ SG_ 814 PARK_frontDtcPresent "Parking assist sensors: front dtc present; raw 3 = signal not available (SNA)";
CM_ SG_ 814 PARK_sensorStatusFrontCounter "Parking assist sensors: sensor status front counter";
CM_ SG_ 814 PARK_sensorStatusFrontChecksum "Parking assist sensors: sensor status front checksum";
CM_ BO_ 830 "Parking assist sensors message: sensor status rear";
CM_ SG_ 830 PARK_rearRightSensorState "Reports the state of the rear right ultrasonic sensor; raw 3 = signal not available (SNA)";
CM_ SG_ 830 PARK_rearRightMiddleSensorState "Reports the state of the rear right middle ultrasonic sensor; raw 3 = signal not available (SNA)";
CM_ SG_ 830 PARK_rearLeftMiddleSensorState "Reports the state of the rear left middle ultrasonic sensor; raw 3 = signal not available (SNA)";
CM_ SG_ 830 PARK_rearLeftSensorState "Reports the state of the rear left ultrasonic sensor; raw 3 = signal not available (SNA)";
CM_ SG_ 830 PARK_rearLeftRawDistData "Zone defined as -90 degrees to -125 degrees, distance to object in units of centimeters; raw 255 = signal not available (SNA)";
CM_ SG_ 830 PARK_rearRightRawDistData "Zone defined as +125 degrees to +90 degrees, distance to object in units of centimeters; raw 255 = signal not available (SNA)";
CM_ SG_ 830 PARK_systemStatusRear "Parking assist sensors: system status rear; raw 3 = signal not available (SNA)";
CM_ SG_ 830 PARK_rearDtcPresent "Parking assist sensors: rear dtc present; raw 3 = signal not available (SNA)";
CM_ SG_ 830 PARK_sensorStatusRearCounter "Parking assist sensors: sensor status rear counter";
CM_ SG_ 830 PARK_sensorStatusRearChecksum "Parking assist sensors: sensor status rear checksum";
CM_ BO_ 799 "Parking assist sensors message: status";
CM_ SG_ 799 PARK_status "Indicates status of park assist function; raw 3 = signal not available (SNA)";
CM_ SG_ 799 PARK_serviceRequest "Indicates whether or not PARK sensors/ECU require service; raw 3 = signal not available (SNA)";
CM_ SG_ 799 PARK_systemDtcPresent "Boolean indicating whether or not there is a DTC present; raw 3 = signal not available (SNA)";
CM_ SG_ 799 PARK_statusCounter "Parking assist sensors: status counter";
CM_ SG_ 799 PARK_statusChecksum "Parking assist sensors: status checksum";
CM_ SG_ 799 PARK_majorVersion "Parking assist sensors: major version; raw 255 = signal not available (SNA)";
CM_ SG_ 799 PARK_minorVersion "Parking assist sensors: minor version; raw 255 = signal not available (SNA)";
CM_ SG_ 799 PARK_subMinorVersion "Parking assist sensors: sub minor version; raw 255 = signal not available (SNA)";
CM_ BO_ 782 "Parking assist sensors message: status2";
CM_ SG_ 782 PARK_frontSVACharID "Parking assist sensors: front SVA char ID";
CM_ SG_ 782 PARK_pscRightCurbType "The type of curb for the parallel parking slot on the right side.";
CM_ SG_ 782 PARK_rearSVACharID "Parking assist sensors: rear SVA char ID";
CM_ SG_ 782 PARK_pscLeftCurbType "The type of curb identified for a parallel parking space on the left.";
CM_ SG_ 782 PARK_autoCalComplete "Parking assist sensors: auto cal complete";
CM_ SG_ 782 PARK_geometryType "Parking assist sensors: geometry type";
CM_ SG_ 782 PARK_tireFitment "Parking assist sensors: tire fitment; raw 3 = signal not available (SNA)";
CM_ SG_ 782 PARK_rackDetected "Parking assist sensors: rack detected; raw 3 = signal not available (SNA)";
CM_ SG_ 782 PARK_sdiActive "Whether or not the raw sensor measurements from the ultrasonics are present and valid";
CM_ SG_ 782 PARK_sdiNoise "The output of the noise detection algorithm for raw sensor measurements, indicates if the measurements are degraded due to ambient noise; raw 3 = signal not available (SNA)";
CM_ SG_ 782 PARK_sdiBlindSpotRight "The output of the PARK ECU blindspot algorithm on the right side of the car, indicates the presence of a vehicle; raw 3 = signal not available (SNA)";
CM_ SG_ 782 PARK_sdiBlindSpotLeft "The output of the PARK ECU blindspot algorithm on the left side of the car, indicates the presence of a vehicle; raw 3 = signal not available (SNA)";
CM_ SG_ 782 PARK_sensorType "Parking assist sensors: sensor type; raw 3 = signal not available (SNA)";
CM_ SG_ 782 PARK_status2Counter "Parking assist sensors: status2 counter";
CM_ SG_ 782 PARK_status2Checksum "Parking assist sensors: status2 checksum";
CM_ BO_ 1630 "Parking assist sensors message: uds response";
CM_ SG_ 1630 PARK_udsResponseData "Parking assist sensors: uds response data";
CM_ BO_ 894 "Parking assist sensors message: warning matrix";
CM_ SG_ 894 PARK_matrixIndex "Parking assist sensors: matrix index";
CM_ SG_ 894 PARK_a001_s1_overTemp "Parking assist sensors: a001 s1 over temp";
CM_ SG_ 894 PARK_a002_s1_internalFail "Parking assist sensors: a002 s1 internal fail";
CM_ SG_ 894 PARK_a003_s1_linCommError "Parking assist sensors: a003 s1 lin comm error";
CM_ SG_ 894 PARK_a004_s1_blocked "Parking assist sensors: a004 s1 blocked";
CM_ SG_ 894 PARK_a005_s1_crossTalk "Parking assist sensors: a005 s1 cross talk";
CM_ SG_ 894 PARK_a006_s2_overTemp "Parking assist sensors: a006 s2 over temp";
CM_ SG_ 894 PARK_a007_s2_internalFail "Parking assist sensors: a007 s2 internal fail";
CM_ SG_ 894 PARK_a008_s2_linCommError "Parking assist sensors: a008 s2 lin comm error";
CM_ SG_ 894 PARK_a009_s2_blocked "Parking assist sensors: a009 s2 blocked";
CM_ SG_ 894 PARK_a010_s2_crossTalk "Parking assist sensors: a010 s2 cross talk";
CM_ SG_ 894 PARK_a011_s3_overTemp "Parking assist sensors: a011 s3 over temp";
CM_ SG_ 894 PARK_a012_s3_internalFail "Parking assist sensors: a012 s3 internal fail";
CM_ SG_ 894 PARK_a013_s3_linCommError "Parking assist sensors: a013 s3 lin comm error";
CM_ SG_ 894 PARK_a014_s3_blocked "Parking assist sensors: a014 s3 blocked";
CM_ SG_ 894 PARK_a015_s3_crossTalk "Parking assist sensors: a015 s3 cross talk";
CM_ SG_ 894 PARK_a016_s4_overTemp "Parking assist sensors: a016 s4 over temp";
CM_ SG_ 894 PARK_a017_s4_internalFail "Parking assist sensors: a017 s4 internal fail";
CM_ SG_ 894 PARK_a018_s4_linCommError "Parking assist sensors: a018 s4 lin comm error";
CM_ SG_ 894 PARK_a019_s4_blocked "Parking assist sensors: a019 s4 blocked";
CM_ SG_ 894 PARK_a020_s4_crossTalk "Parking assist sensors: a020 s4 cross talk";
CM_ SG_ 894 PARK_a021_s5_overTemp "Parking assist sensors: a021 s5 over temp";
CM_ SG_ 894 PARK_a022_s5_internalFail "Parking assist sensors: a022 s5 internal fail";
CM_ SG_ 894 PARK_a023_s5_linCommError "Parking assist sensors: a023 s5 lin comm error";
CM_ SG_ 894 PARK_a024_s5_blocked "Parking assist sensors: a024 s5 blocked";
CM_ SG_ 894 PARK_a025_s5_crossTalk "Parking assist sensors: a025 s5 cross talk";
CM_ SG_ 894 PARK_a026_s6_overTemp "Parking assist sensors: a026 s6 over temp";
CM_ SG_ 894 PARK_a027_s6_internalFail "Parking assist sensors: a027 s6 internal fail";
CM_ SG_ 894 PARK_a028_s6_linCommError "Parking assist sensors: a028 s6 lin comm error";
CM_ SG_ 894 PARK_a029_s6_blocked "Parking assist sensors: a029 s6 blocked";
CM_ SG_ 894 PARK_a030_s6_crossTalk "Parking assist sensors: a030 s6 cross talk";
CM_ SG_ 894 PARK_a031_s7_overTemp "Parking assist sensors: a031 s7 over temp";
CM_ SG_ 894 PARK_a032_s7_internalFail "Parking assist sensors: a032 s7 internal fail";
CM_ SG_ 894 PARK_a033_s7_linCommError "Parking assist sensors: a033 s7 lin comm error";
CM_ SG_ 894 PARK_a034_s7_blocked "Parking assist sensors: a034 s7 blocked";
CM_ SG_ 894 PARK_a035_s7_crossTalk "Parking assist sensors: a035 s7 cross talk";
CM_ SG_ 894 PARK_a036_s8_overTemp "Parking assist sensors: a036 s8 over temp";
CM_ SG_ 894 PARK_a037_s8_internalFail "Parking assist sensors: a037 s8 internal fail";
CM_ SG_ 894 PARK_a038_s8_linCommError "Parking assist sensors: a038 s8 lin comm error";
CM_ SG_ 894 PARK_a039_s8_blocked "Parking assist sensors: a039 s8 blocked";
CM_ SG_ 894 PARK_a040_s8_crossTalk "Parking assist sensors: a040 s8 cross talk";
CM_ SG_ 894 PARK_a041_s9_overTemp "Parking assist sensors: a041 s9 over temp";
CM_ SG_ 894 PARK_a042_s9_internalFail "Parking assist sensors: a042 s9 internal fail";
CM_ SG_ 894 PARK_a043_s9_linCommError "Parking assist sensors: a043 s9 lin comm error";
CM_ SG_ 894 PARK_a044_s9_blocked "Parking assist sensors: a044 s9 blocked";
CM_ SG_ 894 PARK_a045_s9_crossTalk "Parking assist sensors: a045 s9 cross talk";
CM_ SG_ 894 PARK_a046_s10_overTemp "Parking assist sensors: a046 s10 over temp";
CM_ SG_ 894 PARK_a047_s10_internalFail "Parking assist sensors: a047 s10 internal fail";
CM_ SG_ 894 PARK_a048_s10_linCommError "Parking assist sensors: a048 s10 lin comm error";
CM_ SG_ 894 PARK_a049_s10_blocked "Parking assist sensors: a049 s10 blocked";
CM_ SG_ 894 PARK_a050_s10_crossTalk "Parking assist sensors: a050 s10 cross talk";
CM_ SG_ 894 PARK_a051_s11_overTemp "Parking assist sensors: a051 s11 over temp";
CM_ SG_ 894 PARK_a052_s11_internalFail "Parking assist sensors: a052 s11 internal fail";
CM_ SG_ 894 PARK_a053_s11_linCommError "Parking assist sensors: a053 s11 lin comm error";
CM_ SG_ 894 PARK_a054_s11_blocked "Parking assist sensors: a054 s11 blocked";
CM_ SG_ 894 PARK_a055_s11_crossTalk "Parking assist sensors: a055 s11 cross talk";
CM_ SG_ 894 PARK_a056_s12_overTemp "Parking assist sensors: a056 s12 over temp";
CM_ SG_ 894 PARK_a057_s12_internalFail "Parking assist sensors: a057 s12 internal fail";
CM_ SG_ 894 PARK_a058_s12_linCommError "Parking assist sensors: a058 s12 lin comm error";
CM_ SG_ 894 PARK_a059_s12_blocked "Parking assist sensors: a059 s12 blocked";
CM_ SG_ 894 PARK_a060_s12_crossTalk "Parking assist sensors: a060 s12 cross talk";
CM_ SG_ 894 PARK_a061_ecuUnderVoltage "Parking assist sensors: a061 ecu under voltage";
CM_ SG_ 894 PARK_a062_ecuOverVoltage "Parking assist sensors: a062 ecu over voltage";
CM_ SG_ 894 PARK_a063_sensorVoltage "Parking assist sensors: a063 sensor voltage";
CM_ SG_ 894 PARK_a064_ecuFault "Parking assist sensors: a064 ecu fault";
CM_ SG_ 894 PARK_a065_crcFault "Parking assist sensors: a065 crc fault";
CM_ SG_ 894 PARK_a066_calibrationMissing "Parking assist sensors: a066 calibration missing";
CM_ SG_ 894 PARK_a067_privateCANBusOff "Parking assist sensors: a067 private CAN bus off";
CM_ SG_ 894 PARK_a068_hardwareWatchDog "Parking assist sensors: a068 hardware watch dog";
CM_ SG_ 894 PARK_a069_dasMia "Parking assist sensors: a069 das mia";
CM_ SG_ 894 PARK_a070_sccmMia "Parking assist sensors: a070 sccm mia";
CM_ SG_ 894 PARK_a071_diMia "Parking assist sensors: a071 di mia";
CM_ SG_ 894 PARK_a072_epasMia "Parking assist sensors: a072 epas mia";
CM_ SG_ 894 PARK_a073_epbMia "Parking assist sensors: a073 epb mia";
CM_ SG_ 894 PARK_a074_espMia "Parking assist sensors: a074 esp mia";
CM_ SG_ 894 PARK_a075_rcmMia "Parking assist sensors: a075 rcm mia";
CM_ SG_ 894 PARK_a076_vcFrontMia "Parking assist sensors: a076 vc front mia";
CM_ SG_ 894 PARK_a077_dasError "Parking assist sensors: a077 das error";
CM_ SG_ 894 PARK_a078_diError "Parking assist sensors: a078 di error";
CM_ SG_ 894 PARK_a079_epasError "Parking assist sensors: a079 epas error";
CM_ SG_ 894 PARK_a080_epbError "Parking assist sensors: a080 epb error";
CM_ SG_ 894 PARK_a081_espError "Parking assist sensors: a081 esp error";
CM_ SG_ 894 PARK_a082_rcmError "Parking assist sensors: a082 rcm error";
CM_ SG_ 894 PARK_a083_vcFrontError "Parking assist sensors: a083 vc front error";
CM_ SG_ 894 PARK_a084_sccmError "Parking assist sensors: a084 sccm error";
CM_ SG_ 894 PARK_a085_watchdogReset "Parking assist sensors: a085 watchdog reset";
CM_ SG_ 894 PARK_a086_nvmFault "Parking assist sensors: a086 nvm fault";
CM_ SG_ 894 PARK_a087_sensorMismatchError "Parking assist sensors: a087 sensor mismatch error";
CM_ BO_ 1060 "Power conversion system (on-board charger and DC-DC converter) message: alert log";
CM_ SG_ 1060 PCS_alertID "Power conversion system (on-board charger and DC-DC converter): alert ID";
CM_ SG_ 1060 PCS_alertSet "Power conversion system (on-board charger and DC-DC converter): alert set";
CM_ SG_ 1060 PCS_alertSource "Power conversion system (on-board charger and DC-DC converter): alert source";
CM_ SG_ 1060 PCS_a001_llcFrequency "Power conversion system (on-board charger and DC-DC converter): a001 llc frequency";
CM_ SG_ 1060 PCS_a001_llcCurrent "Power conversion system (on-board charger and DC-DC converter): a001 llc current";
CM_ SG_ 1060 PCS_a001_phState "Power conversion system (on-board charger and DC-DC converter): a001 ph state";
CM_ SG_ 1060 PCS_a001_pfcCurrentRms "Power conversion system (on-board charger and DC-DC converter): a001 pfc current rms";
CM_ SG_ 1060 PCS_a001_intBusV "Power conversion system (on-board charger and DC-DC converter): a001 int bus v";
CM_ SG_ 1060 PCS_a002_phState "Power conversion system (on-board charger and DC-DC converter): a002 ph state";
CM_ SG_ 1060 PCS_a003_phState "Power conversion system (on-board charger and DC-DC converter): a003 ph state";
CM_ SG_ 1060 PCS_a004_phState "Power conversion system (on-board charger and DC-DC converter): a004 ph state";
CM_ SG_ 1060 PCS_a005_outputV "Power conversion system (on-board charger and DC-DC converter): a005 output v";
CM_ SG_ 1060 PCS_a005_outputVOvThreshold "Power conversion system (on-board charger and DC-DC converter): a005 output v ov threshold";
CM_ SG_ 1060 PCS_a006_phState "Power conversion system (on-board charger and DC-DC converter): a006 ph state";
CM_ SG_ 1060 PCS_a006_intBusPrechargeTarget "Power conversion system (on-board charger and DC-DC converter): a006 int bus precharge target";
CM_ SG_ 1060 PCS_a006_intBusV "Power conversion system (on-board charger and DC-DC converter): a006 int bus v";
CM_ SG_ 1060 PCS_a006_inputVrms "Power conversion system (on-board charger and DC-DC converter): a006 input vrms";
CM_ SG_ 1060 PCS_a006_inputVToIntBusDeltaMax "Power conversion system (on-board charger and DC-DC converter): a006 input v to int bus delta max";
CM_ SG_ 1060 PCS_a006_inputFrequency "Power conversion system (on-board charger and DC-DC converter): a006 input frequency";
CM_ SG_ 1060 PCS_a007_phATemperature "Power conversion system (on-board charger and DC-DC converter): a007 ph a temperature";
CM_ SG_ 1060 PCS_a007_phBTemperature "Power conversion system (on-board charger and DC-DC converter): a007 ph b temperature";
CM_ SG_ 1060 PCS_a007_phCTemperature "Power conversion system (on-board charger and DC-DC converter): a007 ph c temperature";
CM_ SG_ 1060 PCS_a007_ambientTemperature "Power conversion system (on-board charger and DC-DC converter): a007 ambient temperature";
CM_ SG_ 1060 PCS_a007_inputVrms "Power conversion system (on-board charger and DC-DC converter): a007 input vrms";
CM_ SG_ 1060 PCS_a007_inputIrms "Power conversion system (on-board charger and DC-DC converter): a007 input irms";
CM_ SG_ 1060 PCS_a008_phState "Power conversion system (on-board charger and DC-DC converter): a008 ph state";
CM_ SG_ 1060 PCS_a008_phaseTemperature "Power conversion system (on-board charger and DC-DC converter): a008 phase temperature";
CM_ SG_ 1060 PCS_a008_inputVrms "Power conversion system (on-board charger and DC-DC converter): a008 input vrms";
CM_ SG_ 1060 PCS_a008_inputIrms "Power conversion system (on-board charger and DC-DC converter): a008 input irms";
CM_ SG_ 1060 PCS_a009_phState "Power conversion system (on-board charger and DC-DC converter): a009 ph state";
CM_ SG_ 1060 PCS_a009_pfcCurrentRms "Power conversion system (on-board charger and DC-DC converter): a009 pfc current rms";
CM_ SG_ 1060 PCS_a009_pfcCurrentTarget "Power conversion system (on-board charger and DC-DC converter): a009 pfc current target";
CM_ SG_ 1060 PCS_a009_llcCurrent "Power conversion system (on-board charger and DC-DC converter): a009 llc current";
CM_ SG_ 1060 PCS_a009_intBusV "Power conversion system (on-board charger and DC-DC converter): a009 int bus v";
CM_ SG_ 1060 PCS_a010_phState "Power conversion system (on-board charger and DC-DC converter): a010 ph state";
CM_ SG_ 1060 PCS_a010_pfcCurrentRms "Power conversion system (on-board charger and DC-DC converter): a010 pfc current rms";
CM_ SG_ 1060 PCS_a010_llcCurrent "Power conversion system (on-board charger and DC-DC converter): a010 llc current";
CM_ SG_ 1060 PCS_a010_intBusV "Power conversion system (on-board charger and DC-DC converter): a010 int bus v";
CM_ SG_ 1060 PCS_a010_intBusVTarget "Power conversion system (on-board charger and DC-DC converter): a010 int bus v target";
CM_ SG_ 1060 PCS_a011_phState "Power conversion system (on-board charger and DC-DC converter): a011 ph state";
CM_ SG_ 1060 PCS_a011_llcCurrent "Power conversion system (on-board charger and DC-DC converter): a011 llc current";
CM_ SG_ 1060 PCS_a011_llcCurrentTarget "Power conversion system (on-board charger and DC-DC converter): a011 llc current target";
CM_ SG_ 1060 PCS_a011_llcFrequency "Power conversion system (on-board charger and DC-DC converter): a011 llc frequency";
CM_ SG_ 1060 PCS_a011_intBusV "Power conversion system (on-board charger and DC-DC converter): a011 int bus v";
CM_ SG_ 1060 PCS_a011_outputV "Power conversion system (on-board charger and DC-DC converter): a011 output v";
CM_ SG_ 1060 PCS_a012_phState "Power conversion system (on-board charger and DC-DC converter): a012 ph state";
CM_ SG_ 1060 PCS_a012_llcFrequency "Power conversion system (on-board charger and DC-DC converter): a012 llc frequency";
CM_ SG_ 1060 PCS_a012_llcCurrent "Power conversion system (on-board charger and DC-DC converter): a012 llc current";
CM_ SG_ 1060 PCS_a012_outOfIBandDuration "Power conversion system (on-board charger and DC-DC converter): a012 out of i band duration";
CM_ SG_ 1060 PCS_a012_batteryV "Power conversion system (on-board charger and DC-DC converter): a012 battery v";
CM_ SG_ 1060 PCS_a012_transientRetryCount "Power conversion system (on-board charger and DC-DC converter): a012 transient retry count";
CM_ SG_ 1060 PCS_a013_phState "Power conversion system (on-board charger and DC-DC converter): a013 ph state";
CM_ SG_ 1060 PCS_a013_intBusPrechargeTarget "Power conversion system (on-board charger and DC-DC converter): a013 int bus precharge target";
CM_ SG_ 1060 PCS_a013_intBusV "Power conversion system (on-board charger and DC-DC converter): a013 int bus v";
CM_ SG_ 1060 PCS_a013_inputVrms "Power conversion system (on-board charger and DC-DC converter): a013 input vrms";
CM_ SG_ 1060 PCS_a013_inputVToIntBusDeltaMax "Power conversion system (on-board charger and DC-DC converter): a013 input v to int bus delta max";
CM_ SG_ 1060 PCS_a013_inputFrequency "Power conversion system (on-board charger and DC-DC converter): a013 input frequency";
CM_ SG_ 1060 PCS_a014_phaTemperature "Power conversion system (on-board charger and DC-DC converter): a014 pha temperature";
CM_ SG_ 1060 PCS_a014_phbTemperature "Power conversion system (on-board charger and DC-DC converter): a014 phb temperature";
CM_ SG_ 1060 PCS_a014_phcTemperature "Power conversion system (on-board charger and DC-DC converter): a014 phc temperature";
CM_ SG_ 1060 PCS_a015_lvBusVoltage "Power conversion system (on-board charger and DC-DC converter): a015 lv bus voltage";
CM_ SG_ 1060 PCS_a016_phAVoltSrcMissingDetect "Power conversion system (on-board charger and DC-DC converter): a016 ph a volt src missing detected";
CM_ SG_ 1060 PCS_a016_phBVoltSrcMissingDetect "Power conversion system (on-board charger and DC-DC converter): a016 ph b volt src missing detected";
CM_ SG_ 1060 PCS_a016_phCVoltSrcMissingDetect "Power conversion system (on-board charger and DC-DC converter): a016 ph c volt src missing detected";
CM_ SG_ 1060 PCS_a018_PhaseDiff_L1N_L2N "Power conversion system (on-board charger and DC-DC converter): a018 phase diff L1 n L2 n";
CM_ SG_ 1060 PCS_a018_PhaseDiff_L2N_L3N "Power conversion system (on-board charger and DC-DC converter): a018 phase diff L2 n L3 n";
CM_ SG_ 1060 PCS_a018_PhaseDiff_L1N_L3N "Power conversion system (on-board charger and DC-DC converter): a018 phase diff L1 n L3 n";
CM_ SG_ 1060 PCS_a018_PhaseDiff_L1L2_L1N "Power conversion system (on-board charger and DC-DC converter): a018 phase diff L1 L2 L1 n";
CM_ SG_ 1060 PCS_a018_L1NLocked "Power conversion system (on-board charger and DC-DC converter): a018 L1 n locked";
CM_ SG_ 1060 PCS_a018_L2NLocked "Power conversion system (on-board charger and DC-DC converter): a018 L2 n locked";
CM_ SG_ 1060 PCS_a018_L3NLocked "Power conversion system (on-board charger and DC-DC converter): a018 L3 n locked";
CM_ SG_ 1060 PCS_a018_L1L2Locked "Power conversion system (on-board charger and DC-DC converter): a018 L1 L2 locked";
CM_ SG_ 1060 PCS_a019_pcsMaxAvailablePower "Power conversion system (on-board charger and DC-DC converter): a019 pcs max available power";
CM_ SG_ 1060 PCS_a019_utilityPowerAvailable "Power conversion system (on-board charger and DC-DC converter): a019 utility power available";
CM_ SG_ 1060 PCS_a019_userPowerRequest "Power conversion system (on-board charger and DC-DC converter): a019 user power request";
CM_ SG_ 1060 PCS_a019_phAFaulted "Power conversion system (on-board charger and DC-DC converter): a019 ph a faulted";
CM_ SG_ 1060 PCS_a019_phBFaulted "Power conversion system (on-board charger and DC-DC converter): a019 ph b faulted";
CM_ SG_ 1060 PCS_a019_phCFaulted "Power conversion system (on-board charger and DC-DC converter): a019 ph c faulted";
CM_ SG_ 1060 PCS_a020_chargeEnableLine "Power conversion system (on-board charger and DC-DC converter): a020 charge enable line";
CM_ SG_ 1060 PCS_a020_chargeEnableCan "Power conversion system (on-board charger and DC-DC converter): a020 charge enable can";
CM_ SG_ 1060 PCS_a021_HVP_hvsControl "Power conversion system (on-board charger and DC-DC converter): a021 HVP hvs control";
CM_ SG_ 1060 PCS_a022_BMS_pcsRequest "Power conversion system (on-board charger and DC-DC converter): a022 BMS pcs request";
CM_ SG_ 1060 PCS_a022_BMS_chargeStatus "Power conversion system (on-board charger and DC-DC converter): a022 BMS charge status";
CM_ SG_ 1060 PCS_a023_CP_chargeStatus "Power conversion system (on-board charger and DC-DC converter): a023 CP charge status";
CM_ SG_ 1060 PCS_a023_CP_status "Power conversion system (on-board charger and DC-DC converter): a023 CP status";
CM_ SG_ 1060 PCS_a024_VCFRONT_sensors "Power conversion system (on-board charger and DC-DC converter): a024 VCFRONT sensors";
CM_ SG_ 1060 PCS_a024_VCFRONT_vehicleStatus "Power conversion system (on-board charger and DC-DC converter): a024 VCFRONT vehicle status";
CM_ SG_ 1060 PCS_a024_VCFRONT_systemStatus "Power conversion system (on-board charger and DC-DC converter): a024 VCFRONT system status";
CM_ SG_ 1060 PCS_a024_VCFRONT_coolant "Power conversion system (on-board charger and DC-DC converter): a024 VCFRONT coolant";
CM_ SG_ 1060 PCS_a024_VCFRONT_vehNm "Power conversion system (on-board charger and DC-DC converter): a024 VCFRONT veh nm";
CM_ SG_ 1060 PCS_a025_cpu2ErrorCode "Power conversion system (on-board charger and DC-DC converter): a025 cpu2 error code";
CM_ SG_ 1060 PCS_a025_bootromStatus "Power conversion system (on-board charger and DC-DC converter): a025 bootrom status";
CM_ SG_ 1060 PCS_a025_bootloaderStatus "Power conversion system (on-board charger and DC-DC converter): a025 bootloader status";
CM_ SG_ 1060 PCS_a025_bootromRequestFlag "Power conversion system (on-board charger and DC-DC converter): a025 bootrom request flag";
CM_ SG_ 1060 PCS_a025_bootromRequestStatusFla "Power conversion system (on-board charger and DC-DC converter): a025 bootrom request status flag";
CM_ SG_ 1060 PCS_a025_cpu2StoredAppCrcLsb16 "Power conversion system (on-board charger and DC-DC converter): a025 cpu2 stored app crc lsb16";
CM_ SG_ 1060 PCS_a027_chgPhATemp "Power conversion system (on-board charger and DC-DC converter): a027 chg ph a temp";
CM_ SG_ 1060 PCS_a027_chgPhBTemp "Power conversion system (on-board charger and DC-DC converter): a027 chg ph b temp";
CM_ SG_ 1060 PCS_a027_chgPhCTemp "Power conversion system (on-board charger and DC-DC converter): a027 chg ph c temp";
CM_ SG_ 1060 PCS_a027_chgPhANoFlowBucket "Power conversion system (on-board charger and DC-DC converter): a027 chg ph a no flow bucket";
CM_ SG_ 1060 PCS_a027_chgPhBNoFlowBucket "Power conversion system (on-board charger and DC-DC converter): a027 chg ph b no flow bucket";
CM_ SG_ 1060 PCS_a027_chgPhCNoFlowBucket "Power conversion system (on-board charger and DC-DC converter): a027 chg ph c no flow bucket";
CM_ SG_ 1060 PCS_a028_outputV "Power conversion system (on-board charger and DC-DC converter): a028 output v";
CM_ SG_ 1060 PCS_a028_outputVUvThreshold "Power conversion system (on-board charger and DC-DC converter): a028 output v uv threshold";
CM_ SG_ 1060 PCS_a029_inputVrms "Power conversion system (on-board charger and DC-DC converter): a029 input vrms";
CM_ SG_ 1060 PCS_a029_chgInputPower "Power conversion system (on-board charger and DC-DC converter): a029 chg input power";
CM_ SG_ 1060 PCS_a029_bmsPowerCommand "Power conversion system (on-board charger and DC-DC converter): a029 bms power command";
CM_ SG_ 1060 PCS_a029_phaseConfig "Power conversion system (on-board charger and DC-DC converter): a029 phase config; raw 0 = signal not available (SNA)";
CM_ SG_ 1060 PCS_a030_canRxErrorType "Power conversion system (on-board charger and DC-DC converter): a030 can rx error type";
CM_ SG_ 1060 PCS_a030_canID "Power conversion system (on-board charger and DC-DC converter): a030 can ID";
CM_ SG_ 1060 PCS_a032_phATransientRetryCount "Power conversion system (on-board charger and DC-DC converter): a032 ph a transient retry count";
CM_ SG_ 1060 PCS_a032_phBTransientRetryCount "Power conversion system (on-board charger and DC-DC converter): a032 ph b transient retry count";
CM_ SG_ 1060 PCS_a032_phCTransientRetryCount "Power conversion system (on-board charger and DC-DC converter): a032 ph c transient retry count";
CM_ SG_ 1060 PCS_a032_phAFaulted "Power conversion system (on-board charger and DC-DC converter): a032 ph a faulted";
CM_ SG_ 1060 PCS_a032_phBFaulted "Power conversion system (on-board charger and DC-DC converter): a032 ph b faulted";
CM_ SG_ 1060 PCS_a032_phCFaulted "Power conversion system (on-board charger and DC-DC converter): a032 ph c faulted";
CM_ SG_ 1060 PCS_a033_HV_busV "Power conversion system (on-board charger and DC-DC converter): a033 HV bus v";
CM_ SG_ 1060 PCS_a034_HV_busV "Power conversion system (on-board charger and DC-DC converter): a034 HV bus v";
CM_ SG_ 1060 PCS_a035_LV_busV "Power conversion system (on-board charger and DC-DC converter): a035 LV bus v";
CM_ SG_ 1060 PCS_a036_LV_busV "Power conversion system (on-board charger and DC-DC converter): a036 LV bus v";
CM_ SG_ 1060 PCS_a037_dcdcPwmDeassertedCount "Power conversion system (on-board charger and DC-DC converter): a037 dcdc pwm deasserted count";
CM_ SG_ 1060 PCS_a038_dcdcClaFaultCode "Power conversion system (on-board charger and DC-DC converter): a038 dcdc cla fault code";
CM_ SG_ 1060 PCS_a038_dcdcSubState "Power conversion system (on-board charger and DC-DC converter): a038 dcdc sub state";
CM_ SG_ 1060 PCS_a038_dcdcLvBusV "Power conversion system (on-board charger and DC-DC converter): a038 dcdc lv bus v";
CM_ SG_ 1060 PCS_a038_dcdcHvBusV "Power conversion system (on-board charger and DC-DC converter): a038 dcdc hv bus v";
CM_ SG_ 1060 PCS_a038_dcdcLvBusCurrent_A "Power conversion system (on-board charger and DC-DC converter): a038 dcdc lv bus current a";
CM_ SG_ 1060 PCS_a038_dcdcPwmEnableDeasserted "Power conversion system (on-board charger and DC-DC converter): a038 dcdc pwm enable deasserted count";
CM_ SG_ 1060 PCS_a038_dcdcPwmEnableLine "Power conversion system (on-board charger and DC-DC converter): a038 dcdc pwm enable line";
CM_ SG_ 1060 PCS_a039_SDModuleClockFault_HV "Power conversion system (on-board charger and DC-DC converter): a039 SD module clock fault HV";
CM_ SG_ 1060 PCS_a039_SDModuleClockFault_LV "Power conversion system (on-board charger and DC-DC converter): a039 SD module clock fault LV";
CM_ SG_ 1060 PCS_a040_dcdcLvVoltageTarget "Power conversion system (on-board charger and DC-DC converter): a040 dcdc lv voltage target";
CM_ SG_ 1060 PCS_a040_dcdcLvVoltage "Power conversion system (on-board charger and DC-DC converter): a040 dcdc lv voltage";
CM_ SG_ 1060 PCS_a040_dcdcLvOutputCurrent "Power conversion system (on-board charger and DC-DC converter): a040 dcdc lv output current";
CM_ SG_ 1060 PCS_a041_dcdcTemperature "Power conversion system (on-board charger and DC-DC converter): a041 dcdc temperature";
CM_ SG_ 1060 PCS_a042_dcdcEnableLine "Power conversion system (on-board charger and DC-DC converter): a042 dcdc enable line";
CM_ SG_ 1060 PCS_a042_dcdcEnableCan "Power conversion system (on-board charger and DC-DC converter): a042 dcdc enable can";
CM_ SG_ 1060 PCS_a043_dcdcLvBusV "Power conversion system (on-board charger and DC-DC converter): a043 dcdc lv bus v";
CM_ SG_ 1060 PCS_a043_dcdcHvBusV "Power conversion system (on-board charger and DC-DC converter): a043 dcdc hv bus v";
CM_ SG_ 1060 PCS_a043_hvPrechargeTargetV "Power conversion system (on-board charger and DC-DC converter): a043 hv precharge target v";
CM_ SG_ 1060 PCS_a044_FaultReasonCode "Power conversion system (on-board charger and DC-DC converter): a044 fault reason code; raw 0 = signal not available (SNA)";
CM_ SG_ 1060 PCS_a044_shortTime_us "Power conversion system (on-board charger and DC-DC converter): a044 short time us";
CM_ SG_ 1060 PCS_a044_dcdcLvBusCurrent_A "Power conversion system (on-board charger and DC-DC converter): a044 dcdc lv bus current a";
CM_ SG_ 1060 PCS_a044_vTankPeak_abs_V "Power conversion system (on-board charger and DC-DC converter): a044 v tank peak abs v";
CM_ SG_ 1060 PCS_a045_hvBusEstimated_C_uF "Power conversion system (on-board charger and DC-DC converter): a045 hv bus estimated c u f";
CM_ SG_ 1060 PCS_a045_hvBusEstimated_R_kOhm "Power conversion system (on-board charger and DC-DC converter): a045 hv bus estimated r k ohm";
CM_ SG_ 1060 PCS_a046_hvBusEstimated_C_uF "Power conversion system (on-board charger and DC-DC converter): a046 hv bus estimated c u f";
CM_ SG_ 1060 PCS_a046_hvBusEstimated_R_kOhm "Power conversion system (on-board charger and DC-DC converter): a046 hv bus estimated r k ohm";
CM_ SG_ 1060 PCS_a047_cpu1BootLoaderCrcMismat "Power conversion system (on-board charger and DC-DC converter): a047 cpu1 boot loader crc mismatch";
CM_ SG_ 1060 PCS_a047_cpu2BootLoaderCrcMismat "Power conversion system (on-board charger and DC-DC converter): a047 cpu2 boot loader crc mismatch";
CM_ SG_ 1060 PCS_a047_calculatedBootloaderCrc "Power conversion system (on-board charger and DC-DC converter): a047 calculated bootloader crc";
CM_ SG_ 1060 PCS_a049_dcdcTemperature "Power conversion system (on-board charger and DC-DC converter): a049 dcdc temperature";
CM_ SG_ 1060 PCS_a051_phState "Power conversion system (on-board charger and DC-DC converter): a051 ph state";
CM_ SG_ 1060 PCS_a051_pfcCurrentRms "Power conversion system (on-board charger and DC-DC converter): a051 pfc current rms";
CM_ SG_ 1060 PCS_a051_llcCurrent "Power conversion system (on-board charger and DC-DC converter): a051 llc current";
CM_ SG_ 1060 PCS_a051_intBusV "Power conversion system (on-board charger and DC-DC converter): a051 int bus v";
CM_ SG_ 1060 PCS_a051_intBusVTarget "Power conversion system (on-board charger and DC-DC converter): a051 int bus v target";
CM_ SG_ 1060 PCS_a051_intBusStaticRipple "Power conversion system (on-board charger and DC-DC converter): a051 int bus static ripple";
CM_ SG_ 1060 PCS_a052_inputVrms "Power conversion system (on-board charger and DC-DC converter): a052 input vrms";
CM_ SG_ 1060 PCS_a053_inputVrms "Power conversion system (on-board charger and DC-DC converter): a053 input vrms";
CM_ SG_ 1060 PCS_a053_inputIrms "Power conversion system (on-board charger and DC-DC converter): a053 input irms";
CM_ SG_ 1060 PCS_a053_acChargeCurrentLimit "Power conversion system (on-board charger and DC-DC converter): a053 ac charge current limit";
CM_ SG_ 1060 PCS_a053_startingInputVrms "Power conversion system (on-board charger and DC-DC converter): a053 starting input vrms";
CM_ SG_ 1060 PCS_a053_phaseConfig "Power conversion system (on-board charger and DC-DC converter): a053 phase config; raw 0 = signal not available (SNA)";
CM_ SG_ 1060 PCS_a054_inputVrms "Power conversion system (on-board charger and DC-DC converter): a054 input vrms";
CM_ SG_ 1060 PCS_a054_inputIrms "Power conversion system (on-board charger and DC-DC converter): a054 input irms";
CM_ SG_ 1060 PCS_a054_acChargeCurrentLimit "Power conversion system (on-board charger and DC-DC converter): a054 ac charge current limit";
CM_ SG_ 1060 PCS_a054_startingInputVrms "Power conversion system (on-board charger and DC-DC converter): a054 starting input vrms";
CM_ SG_ 1060 PCS_a054_phaseConfig "Power conversion system (on-board charger and DC-DC converter): a054 phase config; raw 0 = signal not available (SNA)";
CM_ SG_ 1060 PCS_a057_inputVrms "Power conversion system (on-board charger and DC-DC converter): a057 input vrms";
CM_ SG_ 1060 PCS_a057_inputFrequency "Power conversion system (on-board charger and DC-DC converter): a057 input frequency";
CM_ SG_ 1060 PCS_a058_inputVrms "Power conversion system (on-board charger and DC-DC converter): a058 input vrms";
CM_ SG_ 1060 PCS_a058_inputFrequency "Power conversion system (on-board charger and DC-DC converter): a058 input frequency";
CM_ SG_ 1060 PCS_a059_inputVrms "Power conversion system (on-board charger and DC-DC converter): a059 input vrms";
CM_ SG_ 1060 PCS_a059_inputOvRmsThreshold "Power conversion system (on-board charger and DC-DC converter): a059 input ov rms threshold";
CM_ SG_ 1060 PCS_a060_inputVPeak "Power conversion system (on-board charger and DC-DC converter): a060 input v peak";
CM_ SG_ 1060 PCS_a060_inputOvPeakThreshold "Power conversion system (on-board charger and DC-DC converter): a060 input ov peak threshold";
CM_ SG_ 1060 PCS_a061_chgInputVdcOffset_L1N "Power conversion system (on-board charger and DC-DC converter): a061 chg input vdc offset L1 n";
CM_ SG_ 1060 PCS_a061_chgInputVdcOffset_L2N "Power conversion system (on-board charger and DC-DC converter): a061 chg input vdc offset L2 n";
CM_ SG_ 1060 PCS_a061_chgInputVdcOffset_L3N "Power conversion system (on-board charger and DC-DC converter): a061 chg input vdc offset L3 n";
CM_ SG_ 1060 PCS_a061_chgInputVdcOffset_L1L2 "Power conversion system (on-board charger and DC-DC converter): a061 chg input vdc offset L1 L2";
CM_ SG_ 1060 PCS_a061_PllSourceIrrational_L1N "Power conversion system (on-board charger and DC-DC converter): a061 pll source irrational L1 n";
CM_ SG_ 1060 PCS_a061_PllSourceIrrational_L2N "Power conversion system (on-board charger and DC-DC converter): a061 pll source irrational L2 n";
CM_ SG_ 1060 PCS_a061_PllSourceIrrational_L3N "Power conversion system (on-board charger and DC-DC converter): a061 pll source irrational L3 n";
CM_ SG_ 1060 PCS_a061_PllSourceIrrational_L1L "Power conversion system (on-board charger and DC-DC converter): a061 pll source irrational L1 L2";
CM_ SG_ 1060 PCS_a062_chgInputIOffset "Power conversion system (on-board charger and DC-DC converter): a062 chg input i offset";
CM_ SG_ 1060 PCS_a063_chgOutputV "Power conversion system (on-board charger and DC-DC converter): a063 chg output v";
CM_ SG_ 1060 PCS_a063_hvpHvLinkVoltage "Power conversion system (on-board charger and DC-DC converter): a063 hvp hv link voltage";
CM_ SG_ 1060 PCS_a064_chgOutputIOffset "Power conversion system (on-board charger and DC-DC converter): a064 chg output i offset";
CM_ SG_ 1060 PCS_a065_inputVrms "Power conversion system (on-board charger and DC-DC converter): a065 input vrms";
CM_ SG_ 1060 PCS_a065_inputFrequency "Power conversion system (on-board charger and DC-DC converter): a065 input frequency";
CM_ SG_ 1060 PCS_a066_dcdcHvBusVolt "Power conversion system (on-board charger and DC-DC converter): a066 dcdc hv bus volt";
CM_ SG_ 1060 PCS_a066_hvpHvLinkVoltage "Power conversion system (on-board charger and DC-DC converter): a066 hvp hv link voltage";
CM_ SG_ 1060 PCS_a067_dcdcLvBusVolt "Power conversion system (on-board charger and DC-DC converter): a067 dcdc lv bus volt";
CM_ SG_ 1060 PCS_a067_vcfrontPcsEFuseV "Power conversion system (on-board charger and DC-DC converter): a067 vcfront pcs e fuse v; raw 1023 = signal not available (SNA)";
CM_ SG_ 1060 PCS_a067_vcfrontVcrightVoltage "Power conversion system (on-board charger and DC-DC converter): a067 vcfront vcright voltage; raw 1023 = signal not available (SNA)";
CM_ SG_ 1060 PCS_a068_dcdcTankVolt "Power conversion system (on-board charger and DC-DC converter): a068 dcdc tank volt";
CM_ SG_ 1060 PCS_a068_dcdcTankVoltOffset "Power conversion system (on-board charger and DC-DC converter): a068 dcdc tank volt offset";
CM_ SG_ 1060 PCS_a069_phState "Power conversion system (on-board charger and DC-DC converter): a069 ph state";
CM_ SG_ 1060 PCS_a069_inputIDelta "Power conversion system (on-board charger and DC-DC converter): a069 input i delta";
CM_ SG_ 1060 PCS_a069_inputVrms "Power conversion system (on-board charger and DC-DC converter): a069 input vrms";
CM_ SG_ 1060 PCS_a069_intBusV "Power conversion system (on-board charger and DC-DC converter): a069 int bus v";
CM_ SG_ 1060 PCS_a069_inputFrequency "Power conversion system (on-board charger and DC-DC converter): a069 input frequency";
CM_ SG_ 1060 PCS_a070_phState "Power conversion system (on-board charger and DC-DC converter): a070 ph state";
CM_ SG_ 1060 PCS_a070_inputVDelta "Power conversion system (on-board charger and DC-DC converter): a070 input v delta";
CM_ SG_ 1060 PCS_a070_inputVrms "Power conversion system (on-board charger and DC-DC converter): a070 input vrms";
CM_ SG_ 1060 PCS_a070_intBusV "Power conversion system (on-board charger and DC-DC converter): a070 int bus v";
CM_ SG_ 1060 PCS_a070_inputFrequency "Power conversion system (on-board charger and DC-DC converter): a070 input frequency";
CM_ SG_ 1060 PCS_a071_phState "Power conversion system (on-board charger and DC-DC converter): a071 ph state";
CM_ SG_ 1060 PCS_a071_inputVrms "Power conversion system (on-board charger and DC-DC converter): a071 input vrms";
CM_ SG_ 1060 PCS_a071_intBusV "Power conversion system (on-board charger and DC-DC converter): a071 int bus v";
CM_ SG_ 1060 PCS_a071_inputFrequency "Power conversion system (on-board charger and DC-DC converter): a071 input frequency";
CM_ SG_ 1060 PCS_a071_llcFrequency "Power conversion system (on-board charger and DC-DC converter): a071 llc frequency";
CM_ SG_ 1060 PCS_a072_task1Stopped "Power conversion system (on-board charger and DC-DC converter): a072 task1 stopped";
CM_ SG_ 1060 PCS_a072_task2Stopped "Power conversion system (on-board charger and DC-DC converter): a072 task2 stopped";
CM_ SG_ 1060 PCS_a073_inputL1NVrms "Power conversion system (on-board charger and DC-DC converter): a073 input L1 n vrms";
CM_ SG_ 1060 PCS_a073_inputL2NVrms "Power conversion system (on-board charger and DC-DC converter): a073 input L2 n vrms";
CM_ SG_ 1060 PCS_a073_inputL3NVrms "Power conversion system (on-board charger and DC-DC converter): a073 input L3 n vrms";
CM_ SG_ 1060 PCS_a073_inputNGVrms "Power conversion system (on-board charger and DC-DC converter): a073 input NG vrms";
CM_ SG_ 1060 PCS_a073_phaseConfig "Power conversion system (on-board charger and DC-DC converter): a073 phase config; raw 0 = signal not available (SNA)";
CM_ SG_ 1060 PCS_a073_cpType "Power conversion system (on-board charger and DC-DC converter): a073 cp type";
CM_ SG_ 1060 PCS_a074_dcdcLvBusV "Power conversion system (on-board charger and DC-DC converter): a074 dcdc lv bus v";
CM_ SG_ 1060 PCS_a074_dcdcHvBusV "Power conversion system (on-board charger and DC-DC converter): a074 dcdc hv bus v";
CM_ SG_ 1060 PCS_a075_dcdcLvBusV "Power conversion system (on-board charger and DC-DC converter): a075 dcdc lv bus v";
CM_ SG_ 1060 PCS_a075_dcdcHvBusV "Power conversion system (on-board charger and DC-DC converter): a075 dcdc hv bus v";
CM_ SG_ 1060 PCS_a075_dcdcSubState "Power conversion system (on-board charger and DC-DC converter): a075 dcdc sub state";
CM_ SG_ 1060 PCS_a076_pcsControlRequest "Power conversion system (on-board charger and DC-DC converter): a076 pcs control request";
CM_ SG_ 1060 PCS_a076_dcdcSubState "Power conversion system (on-board charger and DC-DC converter): a076 dcdc sub state";
CM_ SG_ 1060 PCS_a076_dcdcEnableLine "Power conversion system (on-board charger and DC-DC converter): a076 dcdc enable line";
CM_ SG_ 1060 PCS_a076_dcdcPwmEnableDeasserted "Power conversion system (on-board charger and DC-DC converter): a076 dcdc pwm enable deasserted count";
CM_ SG_ 1060 PCS_a078_phaTemperature "Power conversion system (on-board charger and DC-DC converter): a078 pha temperature";
CM_ SG_ 1060 PCS_a078_phbTemperature "Power conversion system (on-board charger and DC-DC converter): a078 phb temperature";
CM_ SG_ 1060 PCS_a078_phcTemperature "Power conversion system (on-board charger and DC-DC converter): a078 phc temperature";
CM_ SG_ 1060 PCS_a078_dcdcTemperature "Power conversion system (on-board charger and DC-DC converter): a078 dcdc temperature";
CM_ SG_ 1060 PCS_a078_ptCoolantTemp "Power conversion system (on-board charger and DC-DC converter): a078 pt coolant temp";
CM_ SG_ 1060 PCS_a079_eepromOperation "Power conversion system (on-board charger and DC-DC converter): a079 eeprom operation; raw 15 = signal not available (SNA)";
CM_ SG_ 1060 PCS_a079_eepromOperationRegion "Power conversion system (on-board charger and DC-DC converter): a079 eeprom operation region";
CM_ SG_ 1060 PCS_a079_recordID "Power conversion system (on-board charger and DC-DC converter): a079 record ID";
CM_ SG_ 1060 PCS_a079_eepromOperationErrorCod "Power conversion system (on-board charger and DC-DC converter): a079 eeprom operation error code";
CM_ SG_ 1060 PCS_a079_operationAddress "Power conversion system (on-board charger and DC-DC converter): a079 operation address";
CM_ SG_ 1060 PCS_a079_eepromErrorCount "Power conversion system (on-board charger and DC-DC converter): a079 eeprom error count";
CM_ SG_ 1060 PCS_a080_phADamaged "Power conversion system (on-board charger and DC-DC converter): a080 ph a damaged";
CM_ SG_ 1060 PCS_a080_phBDamaged "Power conversion system (on-board charger and DC-DC converter): a080 ph b damaged";
CM_ SG_ 1060 PCS_a080_phCDamaged "Power conversion system (on-board charger and DC-DC converter): a080 ph c damaged";
CM_ SG_ 1060 PCS_a080_phANVRAMStoredState "Power conversion system (on-board charger and DC-DC converter): a080 ph ANVRAM stored state";
CM_ SG_ 1060 PCS_a080_phBNVRAMStoredState "Power conversion system (on-board charger and DC-DC converter): a080 ph BNVRAM stored state";
CM_ SG_ 1060 PCS_a080_phCNVRAMStoredState "Power conversion system (on-board charger and DC-DC converter): a080 ph CNVRAM stored state";
CM_ SG_ 1060 PCS_a081_dcdcLvBusV "Power conversion system (on-board charger and DC-DC converter): a081 dcdc lv bus v";
CM_ SG_ 1060 PCS_a081_dcdcHvBusV "Power conversion system (on-board charger and DC-DC converter): a081 dcdc hv bus v";
CM_ SG_ 1060 PCS_a081_faultedSubstate "Power conversion system (on-board charger and DC-DC converter): a081 faulted substate";
CM_ SG_ 1060 PCS_a082_dcdcLvBusV "Power conversion system (on-board charger and DC-DC converter): a082 dcdc lv bus v";
CM_ SG_ 1060 PCS_a082_dcdcHvBusV "Power conversion system (on-board charger and DC-DC converter): a082 dcdc hv bus v";
CM_ SG_ 1060 PCS_a082_faultedSubstate "Power conversion system (on-board charger and DC-DC converter): a082 faulted substate";
CM_ SG_ 1060 PCS_a085_dcdcHalfPeriodUs "Power conversion system (on-board charger and DC-DC converter): a085 dcdc half period us";
CM_ SG_ 1060 PCS_a086_dcdcTemperature "Power conversion system (on-board charger and DC-DC converter): a086 dcdc temperature";
CM_ SG_ 1060 PCS_a086_pcsAmbientTemperature "Power conversion system (on-board charger and DC-DC converter): a086 pcs ambient temperature";
CM_ SG_ 1060 PCS_a086_vcfrontPTCoolantTemp "Power conversion system (on-board charger and DC-DC converter): a086 vcfront PT coolant temp";
CM_ SG_ 1060 PCS_a088_gridConfig "Power conversion system (on-board charger and DC-DC converter): a088 grid config; raw 0 = signal not available (SNA)";
CM_ SG_ 1060 PCS_a088_phAFrequency "Power conversion system (on-board charger and DC-DC converter): a088 ph a frequency";
CM_ SG_ 1060 PCS_a088_phBFrequency "Power conversion system (on-board charger and DC-DC converter): a088 ph b frequency";
CM_ SG_ 1060 PCS_a088_phCFrequency "Power conversion system (on-board charger and DC-DC converter): a088 ph c frequency";
CM_ SG_ 1060 PCS_a089_hvSlewRate "Power conversion system (on-board charger and DC-DC converter): a089 hv slew rate";
CM_ SG_ 1060 PCS_a089_avgSlewRate "Power conversion system (on-board charger and DC-DC converter): a089 avg slew rate";
CM_ SG_ 1060 PCS_a089_G "Power conversion system (on-board charger and DC-DC converter): a089 g";
CM_ SG_ 1060 PCS_a089_HV_busV "Power conversion system (on-board charger and DC-DC converter): a089 HV bus v";
CM_ SG_ 1060 PCS_a089_PhaseShift "Power conversion system (on-board charger and DC-DC converter): a089 phase shift";
CM_ SG_ 1060 PCS_a089_Freq "Power conversion system (on-board charger and DC-DC converter): a089 freq";
CM_ SG_ 1060 PCS_a089_fastDischargeMode "Power conversion system (on-board charger and DC-DC converter): a089 fast discharge mode";
CM_ SG_ 1060 PCS_a089_slowDischargeMode "Power conversion system (on-board charger and DC-DC converter): a089 slow discharge mode";
CM_ SG_ 1060 PCS_a090_vRmsL1N "Power conversion system (on-board charger and DC-DC converter): a090 v rms L1 n";
CM_ SG_ 1060 PCS_a090_vRmsL2N "Power conversion system (on-board charger and DC-DC converter): a090 v rms L2 n";
CM_ SG_ 1060 PCS_a090_vRmsL3N "Power conversion system (on-board charger and DC-DC converter): a090 v rms L3 n";
CM_ SG_ 1060 PCS_a090_vRmsL1L2 "Power conversion system (on-board charger and DC-DC converter): a090 v rms L1 L2";
CM_ SG_ 1060 PCS_a090_evaluatedGridConfig "Power conversion system (on-board charger and DC-DC converter): a090 evaluated grid config; raw 0 = signal not available (SNA)";
CM_ SG_ 1060 PCS_a090_phASourceMissing "Power conversion system (on-board charger and DC-DC converter): a090 ph a source missing";
CM_ SG_ 1060 PCS_a090_phBSourceMissing "Power conversion system (on-board charger and DC-DC converter): a090 ph b source missing";
CM_ SG_ 1060 PCS_a090_phCSourceMissing "Power conversion system (on-board charger and DC-DC converter): a090 ph c source missing";
CM_ SG_ 1060 PCS_a091_intBusTarget "Power conversion system (on-board charger and DC-DC converter): a091 int bus target";
CM_ SG_ 1060 PCS_a091_intBusMaxRippleLevel "Power conversion system (on-board charger and DC-DC converter): a091 int bus max ripple level";
CM_ SG_ 1060 PCS_a091_pfcCurrentIrms "Power conversion system (on-board charger and DC-DC converter): a091 pfc current irms";
CM_ SG_ 1060 PCS_a091_phaseInputVrms "Power conversion system (on-board charger and DC-DC converter): a091 phase input vrms";
CM_ SG_ 1060 PCS_a091_phaseTemp "Power conversion system (on-board charger and DC-DC converter): a091 phase temp";
CM_ SG_ 1060 PCS_a092_pfcIrmsPhA "Power conversion system (on-board charger and DC-DC converter): a092 pfc irms ph a";
CM_ SG_ 1060 PCS_a092_pfcIrmsPhB "Power conversion system (on-board charger and DC-DC converter): a092 pfc irms ph b";
CM_ SG_ 1060 PCS_a092_pfcIrmsPhC "Power conversion system (on-board charger and DC-DC converter): a092 pfc irms ph c";
CM_ SG_ 1060 PCS_a092_chgTempPhA "Power conversion system (on-board charger and DC-DC converter): a092 chg temp ph a";
CM_ SG_ 1060 PCS_a092_chgTempPhB "Power conversion system (on-board charger and DC-DC converter): a092 chg temp ph b";
CM_ SG_ 1060 PCS_a092_chgTempPhC "Power conversion system (on-board charger and DC-DC converter): a092 chg temp ph c";
CM_ SG_ 1060 PCS_a093_powerRail5VN "Power conversion system (on-board charger and DC-DC converter): a093 power rail5 VN";
CM_ SG_ 1060 PCS_a093_powerRail3V3 "Power conversion system (on-board charger and DC-DC converter): a093 power rail3 V3";
CM_ SG_ 1060 PCS_a093_powerRail1V5 "Power conversion system (on-board charger and DC-DC converter): a093 power rail1 V5";
CM_ SG_ 1060 PCS_a093_powerRail1V2 "Power conversion system (on-board charger and DC-DC converter): a093 power rail1 V2";
CM_ SG_ 1060 PCS_a093_irrational1V2Rail "Power conversion system (on-board charger and DC-DC converter): a093 irrational1 V2 rail";
CM_ SG_ 1060 PCS_a093_irrational1V5Rail "Power conversion system (on-board charger and DC-DC converter): a093 irrational1 V5 rail";
CM_ SG_ 1060 PCS_a093_irrational3V3Rail "Power conversion system (on-board charger and DC-DC converter): a093 irrational3 V3 rail";
CM_ SG_ 1060 PCS_a093_irrational5VNRail "Power conversion system (on-board charger and DC-DC converter): a093 irrational5 VN rail";
CM_ SG_ 1060 PCS_a094_malfunctionCode "Power conversion system (on-board charger and DC-DC converter): a094 malfunction code";
CM_ SG_ 1060 PCS_a095_powerRail5VN "Power conversion system (on-board charger and DC-DC converter): a095 power rail5 VN";
CM_ SG_ 1060 PCS_a095_pcsControlRequest "Power conversion system (on-board charger and DC-DC converter): a095 pcs control request";
CM_ SG_ 1060 PCS_a096_gridConfig "Power conversion system (on-board charger and DC-DC converter): a096 grid config; raw 0 = signal not available (SNA)";
CM_ SG_ 1060 PCS_a096_phAFrequency "Power conversion system (on-board charger and DC-DC converter): a096 ph a frequency";
CM_ SG_ 1060 PCS_a096_phBFrequency "Power conversion system (on-board charger and DC-DC converter): a096 ph b frequency";
CM_ SG_ 1060 PCS_a096_phCFrequency "Power conversion system (on-board charger and DC-DC converter): a096 ph c frequency";
CM_ SG_ 1060 PCS_a097_phADamaged "Power conversion system (on-board charger and DC-DC converter): a097 ph a damaged";
CM_ SG_ 1060 PCS_a097_phBDamaged "Power conversion system (on-board charger and DC-DC converter): a097 ph b damaged";
CM_ SG_ 1060 PCS_a097_phCDamaged "Power conversion system (on-board charger and DC-DC converter): a097 ph c damaged";
CM_ SG_ 1060 PCS_a097_phANVRAMStoredState "Power conversion system (on-board charger and DC-DC converter): a097 ph ANVRAM stored state";
CM_ SG_ 1060 PCS_a097_phBNVRAMStoredState "Power conversion system (on-board charger and DC-DC converter): a097 ph BNVRAM stored state";
CM_ SG_ 1060 PCS_a097_phCNVRAMStoredState "Power conversion system (on-board charger and DC-DC converter): a097 ph CNVRAM stored state";
CM_ SG_ 1060 PCS_a100_inputVrms "Power conversion system (on-board charger and DC-DC converter): a100 input vrms";
CM_ SG_ 1060 PCS_a100_phIntBusVolt "Power conversion system (on-board charger and DC-DC converter): a100 ph int bus volt";
CM_ SG_ 1060 PCS_a100_phKwhCounter "Power conversion system (on-board charger and DC-DC converter): a100 ph kwh counter";
CM_ SG_ 1060 PCS_a100_phKwhCounterDeltaFromMa "Power conversion system (on-board charger and DC-DC converter): a100 ph kwh counter delta from max";
CM_ SG_ 1060 PCS_a102_pcsControlRequest "Power conversion system (on-board charger and DC-DC converter): a102 pcs control request";
CM_ SG_ 1060 PCS_a102_NMIFlagRegisters "Power conversion system (on-board charger and DC-DC converter): a102 NMI flag registers";
CM_ SG_ 1060 PCS_a102_systemResetRegisters "Power conversion system (on-board charger and DC-DC converter): a102 system reset registers";
CM_ SG_ 1060 PCS_a102_dcdcEnableLine "Power conversion system (on-board charger and DC-DC converter): a102 dcdc enable line";
CM_ SG_ 1060 PCS_a104_ambientTemperature "Power conversion system (on-board charger and DC-DC converter): a104 ambient temperature";
CM_ SG_ 1060 PCS_a107_VC_pcsInterface "Power conversion system (on-board charger and DC-DC converter): a107 VC pcs interface";
CM_ SG_ 1060 PCS_a108_installedInAWrongPlatfo "Power conversion system (on-board charger and DC-DC converter): a108 installed in a wrong platform";
CM_ SG_ 1060 PCS_a109_inputL2NVrms "Power conversion system (on-board charger and DC-DC converter): a109 input L2 n vrms";
CM_ SG_ 1060 PCS_a109_inputL3NVrms "Power conversion system (on-board charger and DC-DC converter): a109 input L3 n vrms";
CM_ BO_ 932 "Power conversion system (on-board charger and DC-DC converter) message: alert matrix";
CM_ SG_ 932 PCS_matrixIndex "Power conversion system (on-board charger and DC-DC converter): matrix index";
CM_ SG_ 932 PCS_a001_chgHwInputOc "Power conversion system (on-board charger and DC-DC converter): a001 chg hw input oc";
CM_ SG_ 932 PCS_a002_chgHwOutputOc "Power conversion system (on-board charger and DC-DC converter): a002 chg hw output oc";
CM_ SG_ 932 PCS_a003_chgHwInputOv "Power conversion system (on-board charger and DC-DC converter): a003 chg hw input ov";
CM_ SG_ 932 PCS_a004_chgHwIntBusOv "Power conversion system (on-board charger and DC-DC converter): a004 chg hw int bus ov";
CM_ SG_ 932 PCS_a005_chgOutputOv "Power conversion system (on-board charger and DC-DC converter): a005 chg output ov";
CM_ SG_ 932 PCS_a006_chgPrechargeFailedScr "Power conversion system (on-board charger and DC-DC converter): a006 chg precharge failed scr";
CM_ SG_ 932 PCS_a007_chgPhaseTempHot "Power conversion system (on-board charger and DC-DC converter): a007 chg phase temp hot";
CM_ SG_ 932 PCS_a008_chgPhaseOverTemp "Power conversion system (on-board charger and DC-DC converter): a008 chg phase over temp";
CM_ SG_ 932 PCS_a009_chgPfcCurrentRegulation "Power conversion system (on-board charger and DC-DC converter): a009 chg pfc current regulation";
CM_ SG_ 932 PCS_a010_chgIntBusVRegulation "Power conversion system (on-board charger and DC-DC converter): a010 chg int bus v regulation";
CM_ SG_ 932 PCS_a011_chgLlcCurrentRegulation "Power conversion system (on-board charger and DC-DC converter): a011 chg llc current regulation";
CM_ SG_ 932 PCS_a012_chgPfcIBandTracerFault "Power conversion system (on-board charger and DC-DC converter): a012 chg pfc i band tracer fault";
CM_ SG_ 932 PCS_a013_chgPrechargeFailedBoost "Power conversion system (on-board charger and DC-DC converter): a013 chg precharge failed boost";
CM_ SG_ 932 PCS_a014_chgTempRationality "Power conversion system (on-board charger and DC-DC converter): a014 chg temp rationality";
CM_ SG_ 932 PCS_a015_chg12vUv "Power conversion system (on-board charger and DC-DC converter): a015 chg12v uv";
CM_ SG_ 932 PCS_a016_chgAllPhasesFaulted "Power conversion system (on-board charger and DC-DC converter): a016 chg all phases faulted";
CM_ SG_ 932 PCS_a017_chgWallPowerRemoval "Power conversion system (on-board charger and DC-DC converter): a017 chg wall power removal";
CM_ SG_ 932 PCS_a018_chgUnknownGridConfig "Power conversion system (on-board charger and DC-DC converter): a018 chg unknown grid config";
CM_ SG_ 932 PCS_a019_acChargePowerLimited "Power conversion system (on-board charger and DC-DC converter): a019 ac charge power limited";
CM_ SG_ 932 PCS_a020_chgEnableLineMismatch "Power conversion system (on-board charger and DC-DC converter): a020 chg enable line mismatch";
CM_ SG_ 932 PCS_a021_hvpMia "Power conversion system (on-board charger and DC-DC converter): a021 hvp mia";
CM_ SG_ 932 PCS_a022_bmsMia "Power conversion system (on-board charger and DC-DC converter): a022 bms mia";
CM_ SG_ 932 PCS_a023_cpMia "Power conversion system (on-board charger and DC-DC converter): a023 cp mia";
CM_ SG_ 932 PCS_a024_vcfrontMia "Power conversion system (on-board charger and DC-DC converter): a024 vcfront mia";
CM_ SG_ 932 PCS_a025_cpu2Malfunction "Power conversion system (on-board charger and DC-DC converter): a025 cpu2 malfunction";
CM_ SG_ 932 PCS_a026_watchdogAlarmed "Power conversion system (on-board charger and DC-DC converter): a026 watchdog alarmed";
CM_ SG_ 932 PCS_a027_chgInsufficientCooling "Power conversion system (on-board charger and DC-DC converter): a027 chg insufficient cooling";
CM_ SG_ 932 PCS_a028_chgOutputUv "Power conversion system (on-board charger and DC-DC converter): a028 chg output uv";
CM_ SG_ 932 PCS_a029_chgPowerRationality "Power conversion system (on-board charger and DC-DC converter): a029 chg power rationality";
CM_ SG_ 932 PCS_a030_canRationality "Power conversion system (on-board charger and DC-DC converter): a030 can rationality";
CM_ SG_ 932 PCS_a031_uiMia "Power conversion system (on-board charger and DC-DC converter): a031 ui mia";
CM_ SG_ 932 PCS_a032_excessiveGridTransients "Power conversion system (on-board charger and DC-DC converter): a032 excessive grid transients detected";
CM_ SG_ 932 PCS_a033_hvBusUv "Power conversion system (on-board charger and DC-DC converter): a033 hv bus uv";
CM_ SG_ 932 PCS_a034_hvBusOv "Power conversion system (on-board charger and DC-DC converter): a034 hv bus ov";
CM_ SG_ 932 PCS_a035_lvBusUv "Power conversion system (on-board charger and DC-DC converter): a035 lv bus uv";
CM_ SG_ 932 PCS_a036_lvBusOv "Power conversion system (on-board charger and DC-DC converter): a036 lv bus ov";
CM_ SG_ 932 PCS_a037_resonantTankOc "Power conversion system (on-board charger and DC-DC converter): a037 resonant tank oc";
CM_ SG_ 932 PCS_a038_claFaulted "Power conversion system (on-board charger and DC-DC converter): a038 cla faulted";
CM_ SG_ 932 PCS_a039_sdModuleClkFault "Power conversion system (on-board charger and DC-DC converter): a039 sd module clk fault";
CM_ SG_ 932 PCS_a040_dcdcMaxPowerReached "Power conversion system (on-board charger and DC-DC converter): a040 dcdc max power reached";
CM_ SG_ 932 PCS_a041_dcdcOverTemp "Power conversion system (on-board charger and DC-DC converter): a041 dcdc over temp";
CM_ SG_ 932 PCS_a042_dcdcEnableLineMismatch "Power conversion system (on-board charger and DC-DC converter): a042 dcdc enable line mismatch";
CM_ SG_ 932 PCS_a043_hvBusPrechargeFailure "Power conversion system (on-board charger and DC-DC converter): a043 hv bus precharge failure";
CM_ SG_ 932 PCS_a044_12vSupportRegulation "Power conversion system (on-board charger and DC-DC converter): a044 12v support regulation";
CM_ SG_ 932 PCS_a045_hvBusLowImpedance "Power conversion system (on-board charger and DC-DC converter): a045 hv bus low impedance";
CM_ SG_ 932 PCS_a046_hvBusHighImpedence "Power conversion system (on-board charger and DC-DC converter): a046 hv bus high impedence";
CM_ SG_ 932 PCS_a047_bootloaderCrcMismatch "Power conversion system (on-board charger and DC-DC converter): a047 bootloader crc mismatch";
CM_ SG_ 932 PCS_a048_softwareAssertion "Power conversion system (on-board charger and DC-DC converter): a048 software assertion";
CM_ SG_ 932 PCS_a049_dcdcTempRationality "Power conversion system (on-board charger and DC-DC converter): a049 dcdc temp rationality";
CM_ SG_ 932 PCS_a050_dcdc12VsupportFaulted "Power conversion system (on-board charger and DC-DC converter): a050 dcdc12 vsupport faulted";
CM_ SG_ 932 PCS_a051_chgIntBusUv "Power conversion system (on-board charger and DC-DC converter): a051 chg int bus uv";
CM_ SG_ 932 PCS_a052_acVoltageNotPresent "Power conversion system (on-board charger and DC-DC converter): a052 ac voltage not present";
CM_ SG_ 932 PCS_a053_chgInputVDropHigh "Power conversion system (on-board charger and DC-DC converter): a053 chg input v drop high";
CM_ SG_ 932 PCS_a054_chgInputVDropTooHigh "Power conversion system (on-board charger and DC-DC converter): a054 chg input v drop too high";
CM_ SG_ 932 PCS_a055_chgLineImpedanceHigh "Power conversion system (on-board charger and DC-DC converter): a055 chg line impedance high";
CM_ SG_ 932 PCS_a056_chgLineImpedanceTooHigh "Power conversion system (on-board charger and DC-DC converter): a056 chg line impedance too high";
CM_ SG_ 932 PCS_a057_chgInputOverFreq "Power conversion system (on-board charger and DC-DC converter): a057 chg input over freq";
CM_ SG_ 932 PCS_a058_chgInputUnderFreq "Power conversion system (on-board charger and DC-DC converter): a058 chg input under freq";
CM_ SG_ 932 PCS_a059_chgInputOvRms "Power conversion system (on-board charger and DC-DC converter): a059 chg input ov rms";
CM_ SG_ 932 PCS_a060_chgInputOvPeak "Power conversion system (on-board charger and DC-DC converter): a060 chg input ov peak";
CM_ SG_ 932 PCS_a061_chgVLineRationality "Power conversion system (on-board charger and DC-DC converter): a061 chg v line rationality";
CM_ SG_ 932 PCS_a062_chgILineRationality "Power conversion system (on-board charger and DC-DC converter): a062 chg i line rationality";
CM_ SG_ 932 PCS_a063_chgVOutRationality "Power conversion system (on-board charger and DC-DC converter): a063 chg v out rationality";
CM_ SG_ 932 PCS_a064_chgIOutRationality "Power conversion system (on-board charger and DC-DC converter): a064 chg i out rationality";
CM_ SG_ 932 PCS_a065_chgPllNotLocked "Power conversion system (on-board charger and DC-DC converter): a065 chg pll not locked";
CM_ SG_ 932 PCS_a066_dcdcHvRationality "Power conversion system (on-board charger and DC-DC converter): a066 dcdc hv rationality";
CM_ SG_ 932 PCS_a067_dcdcLvRationality "Power conversion system (on-board charger and DC-DC converter): a067 dcdc lv rationality";
CM_ SG_ 932 PCS_a068_dcdcTankvRationality "Power conversion system (on-board charger and DC-DC converter): a068 dcdc tankv rationality";
CM_ SG_ 932 PCS_a069_chgPfcLineDidt "Power conversion system (on-board charger and DC-DC converter): a069 chg pfc line didt";
CM_ SG_ 932 PCS_a070_chgPfcLineDvdt "Power conversion system (on-board charger and DC-DC converter): a070 chg pfc line dvdt";
CM_ SG_ 932 PCS_a071_chgPfcILoopRationality "Power conversion system (on-board charger and DC-DC converter): a071 chg pfc i loop rationality";
CM_ SG_ 932 PCS_a072_cpu2ClaStopped "Power conversion system (on-board charger and DC-DC converter): a072 cpu2 cla stopped";
CM_ SG_ 932 PCS_a073_unexpectedAcInputVoltag "Power conversion system (on-board charger and DC-DC converter): a073 unexpected ac input voltage";
CM_ SG_ 932 PCS_a074_hvBusDischargeFailure "Power conversion system (on-board charger and DC-DC converter): a074 hv bus discharge failure";
CM_ SG_ 932 PCS_a075_hvBusDischargeTimeout "Power conversion system (on-board charger and DC-DC converter): a075 hv bus discharge timeout";
CM_ SG_ 932 PCS_a076_dcdcEnDeassertedErr "Power conversion system (on-board charger and DC-DC converter): a076 dcdc en deasserted err";
CM_ SG_ 932 PCS_a077_microGridWobbleDetected "Power conversion system (on-board charger and DC-DC converter): a077 micro grid wobble detected";
CM_ SG_ 932 PCS_a078_chgStopDcdcTooHot "Power conversion system (on-board charger and DC-DC converter): a078 chg stop dcdc too hot";
CM_ SG_ 932 PCS_a079_eepromOperationError "Power conversion system (on-board charger and DC-DC converter): a079 eeprom operation error";
CM_ SG_ 932 PCS_a080_damagedPhaseDetected "Power conversion system (on-board charger and DC-DC converter): a080 damaged phase detected";
CM_ SG_ 932 PCS_a081_dcdcPchgTimeout "Power conversion system (on-board charger and DC-DC converter): a081 dcdc pchg timeout";
CM_ SG_ 932 PCS_a082_dcdcPchgUnsafeDiVoltage "Power conversion system (on-board charger and DC-DC converter): a082 dcdc pchg unsafe di voltage";
CM_ SG_ 932 PCS_a083_triggerOdin "Signal reported by Power conversion system (on-board charger and DC-DC converter)";
CM_ SG_ 932 PCS_a084_vDropFastInParasiticDio "Power conversion system (on-board charger and DC-DC converter): a084 v drop fast in parasitic diode region";
CM_ SG_ 932 PCS_a085_dcdcFetsNotSwitching "Power conversion system (on-board charger and DC-DC converter): a085 dcdc fets not switching";
CM_ SG_ 932 PCS_a086_dcdcInsufficientCooling "Power conversion system (on-board charger and DC-DC converter): a086 dcdc insufficient cooling";
CM_ SG_ 932 PCS_a087_nvramRecordStatusError "Power conversion system (on-board charger and DC-DC converter): a087 nvram record status error";
CM_ SG_ 932 PCS_a088_gridFreqDroopDetected "Power conversion system (on-board charger and DC-DC converter): a088 grid freq droop detected";
CM_ SG_ 932 PCS_a089_hvBusDischargeIrrationa "Power conversion system (on-board charger and DC-DC converter): a089 hv bus discharge irrational";
CM_ SG_ 932 PCS_a090_expectedAcVoltageSource "Power conversion system (on-board charger and DC-DC converter): a090 expected ac voltage source missing";
CM_ SG_ 932 PCS_a091_chgIntBusRationality "Power conversion system (on-board charger and DC-DC converter): a091 chg int bus rationality";
CM_ SG_ 932 PCS_a092_chgPowerLimitedByBusRip "Power conversion system (on-board charger and DC-DC converter): a092 chg power limited by bus ripple";
CM_ SG_ 932 PCS_a093_powerRailRationality "Power conversion system (on-board charger and DC-DC converter): a093 power rail rationality";
CM_ SG_ 932 PCS_a094_pcsDcdcNeedService "Power conversion system (on-board charger and DC-DC converter): a094 pcs dcdc need service";
CM_ SG_ 932 PCS_a095_dcdcSensorlessModeActiv "Power conversion system (on-board charger and DC-DC converter): a095 dcdc sensorless mode active";
CM_ SG_ 932 PCS_a096_microGridOverLoaded "Power conversion system (on-board charger and DC-DC converter): a096 micro grid over loaded";
CM_ SG_ 932 PCS_a097_rebootPhaseDetected "Power conversion system (on-board charger and DC-DC converter): a097 reboot phase detected";
CM_ SG_ 932 PCS_a098_gridFreqDroopDetectedSi "Power conversion system (on-board charger and DC-DC converter): a098 grid freq droop detected silent";
CM_ SG_ 932 PCS_a099_microGridOverLoadedSile "Power conversion system (on-board charger and DC-DC converter): a099 micro grid over loaded silent";
CM_ SG_ 932 PCS_a100_suspectedViperChipIssue "Power conversion system (on-board charger and DC-DC converter): a100 suspected viper chip issue";
CM_ SG_ 932 PCS_a101_phMachineModelIrrationa "Power conversion system (on-board charger and DC-DC converter): a101 ph machine model irrational";
CM_ SG_ 932 PCS_a102_resetWithDCDCCmdAsserte "Power conversion system (on-board charger and DC-DC converter): a102 reset with DCDC cmd asserted";
CM_ SG_ 932 PCS_a103_pchgWithLowLvDetected "Power conversion system (on-board charger and DC-DC converter): a103 pchg with low lv detected";
CM_ SG_ 932 PCS_a104_ambientTempRationality "Power conversion system (on-board charger and DC-DC converter): a104 ambient temp rationality";
CM_ SG_ 932 PCS_a105_redundantVoltageSourceI "Power conversion system (on-board charger and DC-DC converter): a105 redundant voltage source irrational";
CM_ SG_ 932 PCS_a106_clockSourceNotFromExter "Power conversion system (on-board charger and DC-DC converter): a106 clock source not from external crystal";
CM_ SG_ 932 PCS_a107_vcPcsDCDCInterfaceMia "Power conversion system (on-board charger and DC-DC converter): a107 vc pcs DCDC interface mia";
CM_ SG_ 932 PCS_a108_misconfigurationDetecte "Power conversion system (on-board charger and DC-DC converter): a108 misconfiguration detected";
CM_ SG_ 932 PCS_a109_deltaChargingL2L3Swappe "Power conversion system (on-board charger and DC-DC converter): a109 delta charging L2 L3 swapped detected";
CM_ BO_ 612 "Power conversion system (on-board charger and DC-DC converter) message: chg line status";
CM_ SG_ 612 PCS_chgInputVoltage "RMS value of AC charger's sensed input voltage";
CM_ SG_ 612 PCS_chgLineCurrent "AC charger's sensed input line current";
CM_ SG_ 612 PCS_chgAcVoltagePresent "Indicates whether AC voltage is present on the PCS input";
CM_ SG_ 612 PCS_chgInputPower "Total AC charger input power";
CM_ SG_ 612 PCS_chgAcCurrentLimit "Maximum AC current that can be pulled from a single conductor";
CM_ BO_ 516 "Power conversion system (on-board charger and DC-DC converter) message: chg status";
CM_ SG_ 516 PCS_chgMainState "Power conversion system (on-board charger and DC-DC converter): chg main state";
CM_ SG_ 516 PCS_hvChargeStatus "Power conversion system (on-board charger and DC-DC converter): hv charge status";
CM_ SG_ 516 PCS_gridConfig "AC charger sensed grid configuration; raw 0 = signal not available (SNA)";
CM_ SG_ 516 PCS_chgPHAEnable "Indicates whether AC charger phase A is enabled";
CM_ SG_ 516 PCS_chgPHBEnable "Indicates whether AC charger phase B is enabled";
CM_ SG_ 516 PCS_hvInletConductorEnergizedAc "Power conversion system (on-board charger and DC-DC converter): hv inlet conductor energized ac";
CM_ SG_ 516 PCS_chgHighPowerActive "Power conversion system (on-board charger and DC-DC converter): chg high power active";
CM_ SG_ 516 PCS_chgPHCEnable "Indicates whether AC charger phase C is enabled";
CM_ SG_ 516 PCS_chgInstantAcPowerAvailable "Instantaneous power capability of the AC charger";
CM_ SG_ 516 PCS_chgMaxAcPowerAvailable "Maximum power capability of the AC charger; raw 255 = signal not available (SNA)";
CM_ SG_ 516 PCS_chgPHALineCurrentRequest "AC charger phase A input current command";
CM_ SG_ 516 PCS_chgPHBLineCurrentRequest "AC charger phase B input current command";
CM_ SG_ 516 PCS_chgPHCLineCurrentRequest "AC charger phase B input current command";
CM_ SG_ 516 PCS_chgPwmEnableLine "Sensed state of the charger PWM enable hardline";
CM_ SG_ 516 PCS_chargeShutdownRequest "Power conversion system (on-board charger and DC-DC converter): charge shutdown request";
CM_ SG_ 516 PCS_hwVariantType "Hardware variant of AC charger; raw 3 = signal not available (SNA)";
CM_ BO_ 692 "Power conversion system (on-board charger and DC-DC converter) message: dcdc rail status";
CM_ SG_ 692 PCS_dcdcLvBusVolt "DCDC's sensed LV bus voltage";
CM_ SG_ 692 PCS_dcdcHvBusVolt "DCDC's sensed HV bus voltage";
CM_ SG_ 692 PCS_dcdcLvOutputCurrent "DCDC's computed LV output current";
CM_ BO_ 548 "Power conversion system (on-board charger and DC-DC converter) message: dcdc status";
CM_ SG_ 548 PCS_dcdcPrechargeStatus "Status of DCDC HV bus precharge";
CM_ SG_ 548 PCS_dcdcLvSupportStatus "Status of DCDC LV support";
CM_ SG_ 548 PCS_dcdcHvBusDischargeStatus "Power conversion system (on-board charger and DC-DC converter): dcdc hv bus discharge status";
CM_ SG_ 548 PCS_coldSleepAllowed "Power conversion system (on-board charger and DC-DC converter): cold sleep allowed";
CM_ SG_ 548 PCS_dcdcPchgHVBusLowRDetected "Power conversion system (on-board charger and DC-DC converter): dcdc pchg HV bus low r detected";
CM_ SG_ 548 PCS_dcdcSubState "Substate of DCDC state machine";
CM_ SG_ 548 PCS_dcdcFaulted "Whether the DCDC is in faulted state";
CM_ SG_ 548 PCS_okToBePowerCycled "Power conversion system (on-board charger and DC-DC converter): ok to be power cycled";
CM_ SG_ 548 PCS_dcdcOutputIsLimited "Whether the DCDC's output is current limiting";
CM_ SG_ 548 PCS_dcdcMaxOutputCurrentAllowed "Maximum LV output current capability of DCDC based on operating point";
CM_ SG_ 548 PCS_dcdcPrechargeRtyCnt "Power conversion system (on-board charger and DC-DC converter): dcdc precharge rty cnt";
CM_ SG_ 548 PCS_dcdcLvSupportRtyCnt "Power conversion system (on-board charger and DC-DC converter): dcdc lv support rty cnt";
CM_ SG_ 548 PCS_dcdcDischargeRtyCnt "Power conversion system (on-board charger and DC-DC converter): dcdc discharge rty cnt";
CM_ SG_ 548 PCS_dcdcPwmEnableLine "Sensed state of the DCDC PWM enable hardline";
CM_ SG_ 548 PCS_dcdcSupportingFixedLvTarget "Whether DCDC is running LV support at a fixed voltage target";
CM_ SG_ 548 PCS_ecuLogUploadRequest "Power conversion system (on-board charger and DC-DC converter): ecu log upload request";
CM_ SG_ 548 PCS_dcdcPrechargeRestartCnt "Power conversion system (on-board charger and DC-DC converter): dcdc precharge restart cnt";
CM_ SG_ 548 PCS_dcdcInitialPrechargeSubState "Power conversion system (on-board charger and DC-DC converter): dcdc initial precharge sub state";
BA_DEF_ BO_ "GenMsgCycleTime" INT 0 3600000;
BA_DEF_ BO_ "GenMsgSendType" ENUM "Cyclic","NotUsed","NotUsed","NotUsed","NotUsed","NotUsed","NotUsed","IfActive","NoMsgSendType","NotUsed";
BA_DEF_ BO_ "VFrameFormat" ENUM "StandardCAN","ExtendedCAN","reserved","J1939PG","reserved","reserved","reserved","reserved","reserved","reserved","reserved","reserved","reserved","reserved","StandardCAN_FD","ExtendedCAN_FD";
BA_DEF_ BO_ "CANFD_BRS" ENUM "0","1";
BA_DEF_ SG_ "GenSigSNA" STRING;
BA_DEF_ SG_ "SystemSignalLongSymbol" STRING;
BA_DEF_ SG_ "Confidence" ENUM "validated","plausible","layout-only","contradicted";
BA_DEF_DEF_ "GenMsgCycleTime" 0;
BA_DEF_DEF_ "GenMsgSendType" "NoMsgSendType";
BA_DEF_DEF_ "VFrameFormat" "StandardCAN";
BA_DEF_DEF_ "CANFD_BRS" "1";
BA_DEF_DEF_ "GenSigSNA" "";
BA_DEF_DEF_ "SystemSignalLongSymbol" "";
BA_DEF_DEF_ "Confidence" "layout-only";
BA_ "GenMsgCycleTime" BO_ 862 100;
BA_ "GenMsgSendType" BO_ 862 0;
BA_ "GenMsgCycleTime" BO_ 926 100;
BA_ "GenMsgSendType" BO_ 926 0;
BA_ "GenMsgCycleTime" BO_ 606 100;
BA_ "GenMsgSendType" BO_ 606 0;
BA_ "GenMsgCycleTime" BO_ 542 40;
BA_ "GenMsgSendType" BO_ 542 0;
BA_ "GenMsgCycleTime" BO_ 590 100;
BA_ "GenMsgSendType" BO_ 590 0;
BA_ "GenMsgCycleTime" BO_ 526 40;
BA_ "GenMsgSendType" BO_ 526 0;
BA_ "GenMsgCycleTime" BO_ 558 40;
BA_ "GenMsgSendType" BO_ 558 0;
BA_ "GenMsgCycleTime" BO_ 814 100;
BA_ "GenMsgSendType" BO_ 814 0;
BA_ "GenMsgCycleTime" BO_ 830 100;
BA_ "GenMsgSendType" BO_ 830 0;
BA_ "GenMsgCycleTime" BO_ 799 500;
BA_ "GenMsgSendType" BO_ 799 0;
BA_ "GenMsgCycleTime" BO_ 782 250;
BA_ "GenMsgSendType" BO_ 782 0;
BA_ "GenMsgCycleTime" BO_ 894 1000;
BA_ "GenMsgSendType" BO_ 894 0;
BA_ "GenMsgCycleTime" BO_ 932 1000;
BA_ "GenMsgSendType" BO_ 932 0;
BA_ "GenMsgCycleTime" BO_ 612 100;
BA_ "GenMsgSendType" BO_ 612 0;
BA_ "GenMsgCycleTime" BO_ 516 100;
BA_ "GenMsgSendType" BO_ 516 0;
BA_ "GenMsgCycleTime" BO_ 692 100;
BA_ "GenMsgSendType" BO_ 692 0;
BA_ "GenMsgCycleTime" BO_ 548 100;
BA_ "GenMsgSendType" BO_ 548 0;
BA_ "Confidence" SG_ 862 PARK_rearLeftMiddleRawDistData 0;
BA_ "GenSigSNA" SG_ 862 PARK_rearLeftMiddleRawDistData "255";
BA_ "Confidence" SG_ 862 PARK_rearMiddleRawDistData 0;
BA_ "GenSigSNA" SG_ 862 PARK_rearMiddleRawDistData "255";
BA_ "Confidence" SG_ 862 PARK_rearRightMiddleRawDistData 0;
BA_ "GenSigSNA" SG_ 862 PARK_rearRightMiddleRawDistData "255";
BA_ "Confidence" SG_ 862 PARK_pasRearMiddleCounter 0;
BA_ "Confidence" SG_ 862 PARK_pasRearMiddleChecksum 0;
BA_ "Confidence" SG_ 926 PARK_rightSideFrontRawDistData 0;
BA_ "GenSigSNA" SG_ 926 PARK_rightSideFrontRawDistData "255";
BA_ "Confidence" SG_ 926 PARK_rightSideRearRawDistData 0;
BA_ "GenSigSNA" SG_ 926 PARK_rightSideRearRawDistData "255";
BA_ "Confidence" SG_ 926 PARK_leftSideFrontRawDistData 0;
BA_ "GenSigSNA" SG_ 926 PARK_leftSideFrontRawDistData "255";
BA_ "Confidence" SG_ 926 PARK_leftSideRearRawDistData 0;
BA_ "GenSigSNA" SG_ 926 PARK_leftSideRearRawDistData "255";
BA_ "Confidence" SG_ 926 PARK_pasSidesCounter 0;
BA_ "Confidence" SG_ 926 PARK_pasSidesChecksum 0;
BA_ "Confidence" SG_ 606 PARK_pscEnvSlotType 1;
BA_ "Confidence" SG_ 606 PARK_pscLeftParallelObj1X 0;
BA_ "GenSigSNA" SG_ 606 PARK_pscLeftParallelObj1X "2047";
BA_ "Confidence" SG_ 606 PARK_pscLeftParallelObj1Y 0;
BA_ "GenSigSNA" SG_ 606 PARK_pscLeftParallelObj1Y "2047";
BA_ "Confidence" SG_ 606 PARK_pscLeftParallelObj1Alpha 0;
BA_ "GenSigSNA" SG_ 606 PARK_pscLeftParallelObj1Alpha "127";
BA_ "Confidence" SG_ 606 PARK_pscLeftParallelObj2Y 0;
BA_ "GenSigSNA" SG_ 606 PARK_pscLeftParallelObj2Y "2047";
BA_ "Confidence" SG_ 606 PARK_pscLeftParallelObj2X 0;
BA_ "GenSigSNA" SG_ 606 PARK_pscLeftParallelObj2X "2047";
BA_ "Confidence" SG_ 606 PARK_pscLeftParallelObj2Alpha 0;
BA_ "GenSigSNA" SG_ 606 PARK_pscLeftParallelObj2Alpha "127";
BA_ "Confidence" SG_ 606 PARK_pscLeftCrossObj1X 0;
BA_ "GenSigSNA" SG_ 606 PARK_pscLeftCrossObj1X "2047";
BA_ "Confidence" SG_ 606 PARK_pscLeftCrossObj1Y 0;
BA_ "GenSigSNA" SG_ 606 PARK_pscLeftCrossObj1Y "2047";
BA_ "Confidence" SG_ 606 PARK_pscLeftCrossObj1Alpha 0;
BA_ "GenSigSNA" SG_ 606 PARK_pscLeftCrossObj1Alpha "127";
BA_ "Confidence" SG_ 606 PARK_pscLeftCrossObj2Y 0;
BA_ "GenSigSNA" SG_ 606 PARK_pscLeftCrossObj2Y "2047";
BA_ "Confidence" SG_ 606 PARK_pscLeftCrossObj2X 0;
BA_ "GenSigSNA" SG_ 606 PARK_pscLeftCrossObj2X "2047";
BA_ "Confidence" SG_ 606 PARK_pscLeftCrossObj2Alpha 0;
BA_ "GenSigSNA" SG_ 606 PARK_pscLeftCrossObj2Alpha "127";
BA_ "Confidence" SG_ 606 PARK_pscRightParallelObj1X 0;
BA_ "GenSigSNA" SG_ 606 PARK_pscRightParallelObj1X "2047";
BA_ "Confidence" SG_ 606 PARK_pscRightParallelObj1Y 0;
BA_ "GenSigSNA" SG_ 606 PARK_pscRightParallelObj1Y "2047";
BA_ "Confidence" SG_ 606 PARK_pscRightParallelObj1Alpha 0;
BA_ "GenSigSNA" SG_ 606 PARK_pscRightParallelObj1Alpha "127";
BA_ "Confidence" SG_ 606 PARK_pscRightParallelObj2Y 0;
BA_ "GenSigSNA" SG_ 606 PARK_pscRightParallelObj2Y "2047";
BA_ "Confidence" SG_ 606 PARK_pscRightParallelObj2X 0;
BA_ "GenSigSNA" SG_ 606 PARK_pscRightParallelObj2X "2047";
BA_ "Confidence" SG_ 606 PARK_pscRightParallelObj2Alpha 0;
BA_ "GenSigSNA" SG_ 606 PARK_pscRightParallelObj2Alpha "127";
BA_ "Confidence" SG_ 606 PARK_pscRightCrossObj1X 0;
BA_ "GenSigSNA" SG_ 606 PARK_pscRightCrossObj1X "2047";
BA_ "Confidence" SG_ 606 PARK_pscRightCrossObj1Y 0;
BA_ "GenSigSNA" SG_ 606 PARK_pscRightCrossObj1Y "2047";
BA_ "Confidence" SG_ 606 PARK_pscRightCrossObj1Alpha 0;
BA_ "GenSigSNA" SG_ 606 PARK_pscRightCrossObj1Alpha "127";
BA_ "Confidence" SG_ 606 PARK_pscRightCrossObj2Y 0;
BA_ "GenSigSNA" SG_ 606 PARK_pscRightCrossObj2Y "2047";
BA_ "Confidence" SG_ 606 PARK_pscRightCrossObj2X 0;
BA_ "GenSigSNA" SG_ 606 PARK_pscRightCrossObj2X "2047";
BA_ "Confidence" SG_ 606 PARK_pscRightCrossObj2Alpha 0;
BA_ "GenSigSNA" SG_ 606 PARK_pscRightCrossObj2Alpha "127";
BA_ "Confidence" SG_ 542 PARK_pscParkStatus 0;
BA_ "GenSigSNA" SG_ 542 PARK_pscParkStatus "7";
BA_ "Confidence" SG_ 542 PARK_pscParkAbortReason 0;
BA_ "GenSigSNA" SG_ 542 PARK_pscParkAbortReason "31";
BA_ "Confidence" SG_ 542 PARK_pscParallelSpace 0;
BA_ "Confidence" SG_ 542 PARK_pscCrossSpace 0;
BA_ "Confidence" SG_ 542 PARK_pscParallelRightParkable 0;
BA_ "GenSigSNA" SG_ 542 PARK_pscParallelRightParkable "3";
BA_ "Confidence" SG_ 542 PARK_pscParallelLeftParkable 0;
BA_ "GenSigSNA" SG_ 542 PARK_pscParallelLeftParkable "3";
BA_ "Confidence" SG_ 542 PARK_pscCrossRightParkable 0;
BA_ "GenSigSNA" SG_ 542 PARK_pscCrossRightParkable "3";
BA_ "Confidence" SG_ 542 PARK_pscMaxVelocity 0;
BA_ "GenSigSNA" SG_ 542 PARK_pscMaxVelocity "63";
BA_ "Confidence" SG_ 542 PARK_pscCrossLeftParkable 0;
BA_ "GenSigSNA" SG_ 542 PARK_pscCrossLeftParkable "3";
BA_ "Confidence" SG_ 542 PARK_pscParkInstruction 0;
BA_ "GenSigSNA" SG_ 542 PARK_pscParkInstruction "7";
BA_ "Confidence" SG_ 542 PARK_pscManeuverDistance 0;
BA_ "GenSigSNA" SG_ 542 PARK_pscManeuverDistance "2047";
BA_ "Confidence" SG_ 542 PARK_pscAngleActive 0;
BA_ "Confidence" SG_ 542 PARK_pscAngleRequest 0;
BA_ "Confidence" SG_ 542 PARK_pscStatusCounter 0;
BA_ "Confidence" SG_ 542 PARK_pscStatusChecksum 0;
BA_ "Confidence" SG_ 590 PARK_pscVehSlotType 1;
BA_ "Confidence" SG_ 590 PARK_pscLeftParallelVehX 0;
BA_ "GenSigSNA" SG_ 590 PARK_pscLeftParallelVehX "2047";
BA_ "Confidence" SG_ 590 PARK_pscLeftParallelVehY 0;
BA_ "GenSigSNA" SG_ 590 PARK_pscLeftParallelVehY "2047";
BA_ "Confidence" SG_ 590 PARK_pscLeftParallelPsi 0;
BA_ "GenSigSNA" SG_ 590 PARK_pscLeftParallelPsi "8191";
BA_ "Confidence" SG_ 590 PARK_pscLeftParallelSizeX 0;
BA_ "GenSigSNA" SG_ 590 PARK_pscLeftParallelSizeX "255";
BA_ "Confidence" SG_ 590 PARK_pscLeftParallelSizeY 0;
BA_ "GenSigSNA" SG_ 590 PARK_pscLeftParallelSizeY "255";
BA_ "Confidence" SG_ 590 PARK_pscLeftCrossVehX 0;
BA_ "GenSigSNA" SG_ 590 PARK_pscLeftCrossVehX "2047";
BA_ "Confidence" SG_ 590 PARK_pscLeftCrossVehY 0;
BA_ "GenSigSNA" SG_ 590 PARK_pscLeftCrossVehY "2047";
BA_ "Confidence" SG_ 590 PARK_pscLeftCrossPsi 0;
BA_ "GenSigSNA" SG_ 590 PARK_pscLeftCrossPsi "8191";
BA_ "Confidence" SG_ 590 PARK_pscLeftCrossSizeX 0;
BA_ "GenSigSNA" SG_ 590 PARK_pscLeftCrossSizeX "255";
BA_ "Confidence" SG_ 590 PARK_pscLeftCrossSizeY 0;
BA_ "GenSigSNA" SG_ 590 PARK_pscLeftCrossSizeY "255";
BA_ "Confidence" SG_ 590 PARK_pscRightParallelVehX 0;
BA_ "GenSigSNA" SG_ 590 PARK_pscRightParallelVehX "2047";
BA_ "Confidence" SG_ 590 PARK_pscRightParallelVehY 0;
BA_ "GenSigSNA" SG_ 590 PARK_pscRightParallelVehY "2047";
BA_ "Confidence" SG_ 590 PARK_pscRightParallelPsi 0;
BA_ "GenSigSNA" SG_ 590 PARK_pscRightParallelPsi "8191";
BA_ "Confidence" SG_ 590 PARK_pscRightParallelSizeX 0;
BA_ "GenSigSNA" SG_ 590 PARK_pscRightParallelSizeX "255";
BA_ "Confidence" SG_ 590 PARK_pscRightParallelSizeY 0;
BA_ "GenSigSNA" SG_ 590 PARK_pscRightParallelSizeY "255";
BA_ "Confidence" SG_ 590 PARK_pscRightCrossVehX 0;
BA_ "GenSigSNA" SG_ 590 PARK_pscRightCrossVehX "2047";
BA_ "Confidence" SG_ 590 PARK_pscRightCrossVehY 0;
BA_ "GenSigSNA" SG_ 590 PARK_pscRightCrossVehY "2047";
BA_ "Confidence" SG_ 590 PARK_pscRightCrossPsi 0;
BA_ "GenSigSNA" SG_ 590 PARK_pscRightCrossPsi "8191";
BA_ "Confidence" SG_ 590 PARK_pscRightCrossSizeX 0;
BA_ "GenSigSNA" SG_ 590 PARK_pscRightCrossSizeX "255";
BA_ "Confidence" SG_ 590 PARK_pscRightCrossSizeY 0;
BA_ "GenSigSNA" SG_ 590 PARK_pscRightCrossSizeY "255";
BA_ "Confidence" SG_ 526 PARK_sdiSensor1RawDistData 0;
BA_ "GenSigSNA" SG_ 526 PARK_sdiSensor1RawDistData "511";
BA_ "Confidence" SG_ 526 PARK_sdiSensor2RawDistData 0;
BA_ "GenSigSNA" SG_ 526 PARK_sdiSensor2RawDistData "511";
BA_ "Confidence" SG_ 526 PARK_sdiSensor3RawDistData 0;
BA_ "GenSigSNA" SG_ 526 PARK_sdiSensor3RawDistData "511";
BA_ "Confidence" SG_ 526 PARK_sdiSensor4RawDistData 0;
BA_ "GenSigSNA" SG_ 526 PARK_sdiSensor4RawDistData "511";
BA_ "Confidence" SG_ 526 PARK_sdiSensor5RawDistData 0;
BA_ "GenSigSNA" SG_ 526 PARK_sdiSensor5RawDistData "511";
BA_ "Confidence" SG_ 526 PARK_sdiSensor6RawDistData 0;
BA_ "GenSigSNA" SG_ 526 PARK_sdiSensor6RawDistData "511";
BA_ "Confidence" SG_ 526 PARK_sdiFrontCounter 0;
BA_ "Confidence" SG_ 526 PARK_sdiFrontChecksum 0;
BA_ "Confidence" SG_ 558 PARK_sdiSensor7RawDistData 0;
BA_ "GenSigSNA" SG_ 558 PARK_sdiSensor7RawDistData "511";
BA_ "Confidence" SG_ 558 PARK_sdiSensor8RawDistData 0;
BA_ "GenSigSNA" SG_ 558 PARK_sdiSensor8RawDistData "511";
BA_ "Confidence" SG_ 558 PARK_sdiSensor9RawDistData 0;
BA_ "GenSigSNA" SG_ 558 PARK_sdiSensor9RawDistData "511";
BA_ "Confidence" SG_ 558 PARK_sdiSensor10RawDistData 0;
BA_ "GenSigSNA" SG_ 558 PARK_sdiSensor10RawDistData "511";
BA_ "Confidence" SG_ 558 PARK_sdiSensor11RawDistData 0;
BA_ "GenSigSNA" SG_ 558 PARK_sdiSensor11RawDistData "511";
BA_ "Confidence" SG_ 558 PARK_sdiSensor12RawDistData 0;
BA_ "GenSigSNA" SG_ 558 PARK_sdiSensor12RawDistData "511";
BA_ "Confidence" SG_ 558 PARK_sdiRearCounter 0;
BA_ "Confidence" SG_ 558 PARK_sdiRearChecksum 0;
BA_ "Confidence" SG_ 814 PARK_frontRightSensorState 0;
BA_ "GenSigSNA" SG_ 814 PARK_frontRightSensorState "3";
BA_ "Confidence" SG_ 814 PARK_frontRightMiddleSensorState 0;
BA_ "GenSigSNA" SG_ 814 PARK_frontRightMiddleSensorState "3";
BA_ "Confidence" SG_ 814 PARK_frontLeftMiddleSensorState 0;
BA_ "GenSigSNA" SG_ 814 PARK_frontLeftMiddleSensorState "3";
BA_ "Confidence" SG_ 814 PARK_frontLeftSensorState 0;
BA_ "GenSigSNA" SG_ 814 PARK_frontLeftSensorState "3";
BA_ "Confidence" SG_ 814 PARK_frontLeftRawDistData 0;
BA_ "GenSigSNA" SG_ 814 PARK_frontLeftRawDistData "255";
BA_ "Confidence" SG_ 814 PARK_frontRightRawDistData 0;
BA_ "GenSigSNA" SG_ 814 PARK_frontRightRawDistData "255";
BA_ "Confidence" SG_ 814 PARK_systemStatusFront 0;
BA_ "GenSigSNA" SG_ 814 PARK_systemStatusFront "3";
BA_ "Confidence" SG_ 814 PARK_frontDtcPresent 0;
BA_ "GenSigSNA" SG_ 814 PARK_frontDtcPresent "3";
BA_ "Confidence" SG_ 814 PARK_sensorStatusFrontCounter 0;
BA_ "Confidence" SG_ 814 PARK_sensorStatusFrontChecksum 0;
BA_ "Confidence" SG_ 830 PARK_rearRightSensorState 0;
BA_ "GenSigSNA" SG_ 830 PARK_rearRightSensorState "3";
BA_ "Confidence" SG_ 830 PARK_rearRightMiddleSensorState 0;
BA_ "GenSigSNA" SG_ 830 PARK_rearRightMiddleSensorState "3";
BA_ "Confidence" SG_ 830 PARK_rearLeftMiddleSensorState 0;
BA_ "GenSigSNA" SG_ 830 PARK_rearLeftMiddleSensorState "3";
BA_ "Confidence" SG_ 830 PARK_rearLeftSensorState 0;
BA_ "GenSigSNA" SG_ 830 PARK_rearLeftSensorState "3";
BA_ "Confidence" SG_ 830 PARK_rearLeftRawDistData 0;
BA_ "GenSigSNA" SG_ 830 PARK_rearLeftRawDistData "255";
BA_ "Confidence" SG_ 830 PARK_rearRightRawDistData 0;
BA_ "GenSigSNA" SG_ 830 PARK_rearRightRawDistData "255";
BA_ "Confidence" SG_ 830 PARK_systemStatusRear 0;
BA_ "GenSigSNA" SG_ 830 PARK_systemStatusRear "3";
BA_ "Confidence" SG_ 830 PARK_rearDtcPresent 0;
BA_ "GenSigSNA" SG_ 830 PARK_rearDtcPresent "3";
BA_ "Confidence" SG_ 830 PARK_sensorStatusRearCounter 0;
BA_ "Confidence" SG_ 830 PARK_sensorStatusRearChecksum 0;
BA_ "Confidence" SG_ 799 PARK_status 0;
BA_ "GenSigSNA" SG_ 799 PARK_status "3";
BA_ "Confidence" SG_ 799 PARK_serviceRequest 0;
BA_ "GenSigSNA" SG_ 799 PARK_serviceRequest "3";
BA_ "Confidence" SG_ 799 PARK_systemDtcPresent 0;
BA_ "GenSigSNA" SG_ 799 PARK_systemDtcPresent "3";
BA_ "Confidence" SG_ 799 PARK_statusCounter 0;
BA_ "Confidence" SG_ 799 PARK_statusChecksum 0;
BA_ "Confidence" SG_ 799 PARK_majorVersion 0;
BA_ "GenSigSNA" SG_ 799 PARK_majorVersion "255";
BA_ "Confidence" SG_ 799 PARK_minorVersion 0;
BA_ "GenSigSNA" SG_ 799 PARK_minorVersion "255";
BA_ "Confidence" SG_ 799 PARK_subMinorVersion 0;
BA_ "GenSigSNA" SG_ 799 PARK_subMinorVersion "255";
BA_ "Confidence" SG_ 782 PARK_frontSVACharID 0;
BA_ "Confidence" SG_ 782 PARK_pscRightCurbType 0;
BA_ "Confidence" SG_ 782 PARK_rearSVACharID 0;
BA_ "Confidence" SG_ 782 PARK_pscLeftCurbType 0;
BA_ "Confidence" SG_ 782 PARK_autoCalComplete 0;
BA_ "Confidence" SG_ 782 PARK_geometryType 0;
BA_ "Confidence" SG_ 782 PARK_tireFitment 0;
BA_ "GenSigSNA" SG_ 782 PARK_tireFitment "3";
BA_ "Confidence" SG_ 782 PARK_rackDetected 0;
BA_ "GenSigSNA" SG_ 782 PARK_rackDetected "3";
BA_ "Confidence" SG_ 782 PARK_sdiActive 0;
BA_ "Confidence" SG_ 782 PARK_sdiNoise 0;
BA_ "GenSigSNA" SG_ 782 PARK_sdiNoise "3";
BA_ "Confidence" SG_ 782 PARK_sdiBlindSpotRight 0;
BA_ "GenSigSNA" SG_ 782 PARK_sdiBlindSpotRight "3";
BA_ "Confidence" SG_ 782 PARK_sdiBlindSpotLeft 0;
BA_ "GenSigSNA" SG_ 782 PARK_sdiBlindSpotLeft "3";
BA_ "Confidence" SG_ 782 PARK_sensorType 0;
BA_ "GenSigSNA" SG_ 782 PARK_sensorType "3";
BA_ "Confidence" SG_ 782 PARK_status2Counter 0;
BA_ "Confidence" SG_ 782 PARK_status2Checksum 0;
BA_ "Confidence" SG_ 1630 PARK_udsResponseData 1;
BA_ "Confidence" SG_ 894 PARK_matrixIndex 1;
BA_ "Confidence" SG_ 1060 PCS_alertID 1;
BA_ "Confidence" SG_ 1060 PCS_alertSet 1;
BA_ "Confidence" SG_ 1060 PCS_alertSource 1;
BA_ "Confidence" SG_ 1060 PCS_a001_llcFrequency 1;
BA_ "Confidence" SG_ 1060 PCS_a001_llcCurrent 1;
BA_ "Confidence" SG_ 1060 PCS_a001_phState 1;
BA_ "Confidence" SG_ 1060 PCS_a001_pfcCurrentRms 1;
BA_ "Confidence" SG_ 1060 PCS_a001_intBusV 1;
BA_ "Confidence" SG_ 1060 PCS_a002_phState 1;
BA_ "Confidence" SG_ 1060 PCS_a003_phState 1;
BA_ "Confidence" SG_ 1060 PCS_a004_phState 1;
BA_ "Confidence" SG_ 1060 PCS_a005_outputV 1;
BA_ "Confidence" SG_ 1060 PCS_a005_outputVOvThreshold 1;
BA_ "Confidence" SG_ 1060 PCS_a006_phState 1;
BA_ "Confidence" SG_ 1060 PCS_a006_intBusPrechargeTarget 1;
BA_ "Confidence" SG_ 1060 PCS_a006_intBusV 1;
BA_ "Confidence" SG_ 1060 PCS_a006_inputVrms 1;
BA_ "Confidence" SG_ 1060 PCS_a006_inputVToIntBusDeltaMax 1;
BA_ "Confidence" SG_ 1060 PCS_a006_inputFrequency 1;
BA_ "Confidence" SG_ 1060 PCS_a007_phATemperature 1;
BA_ "Confidence" SG_ 1060 PCS_a007_phBTemperature 1;
BA_ "Confidence" SG_ 1060 PCS_a007_phCTemperature 1;
BA_ "Confidence" SG_ 1060 PCS_a007_ambientTemperature 1;
BA_ "Confidence" SG_ 1060 PCS_a007_inputVrms 1;
BA_ "Confidence" SG_ 1060 PCS_a007_inputIrms 1;
BA_ "Confidence" SG_ 1060 PCS_a008_phState 1;
BA_ "Confidence" SG_ 1060 PCS_a008_phaseTemperature 1;
BA_ "Confidence" SG_ 1060 PCS_a008_inputVrms 1;
BA_ "Confidence" SG_ 1060 PCS_a008_inputIrms 1;
BA_ "Confidence" SG_ 1060 PCS_a009_phState 1;
BA_ "Confidence" SG_ 1060 PCS_a009_pfcCurrentRms 1;
BA_ "Confidence" SG_ 1060 PCS_a009_pfcCurrentTarget 1;
BA_ "Confidence" SG_ 1060 PCS_a009_llcCurrent 1;
BA_ "Confidence" SG_ 1060 PCS_a009_intBusV 1;
BA_ "Confidence" SG_ 1060 PCS_a010_phState 1;
BA_ "Confidence" SG_ 1060 PCS_a010_pfcCurrentRms 1;
BA_ "Confidence" SG_ 1060 PCS_a010_llcCurrent 1;
BA_ "Confidence" SG_ 1060 PCS_a010_intBusV 1;
BA_ "Confidence" SG_ 1060 PCS_a010_intBusVTarget 1;
BA_ "Confidence" SG_ 1060 PCS_a011_phState 1;
BA_ "Confidence" SG_ 1060 PCS_a011_llcCurrent 1;
BA_ "Confidence" SG_ 1060 PCS_a011_llcCurrentTarget 1;
BA_ "Confidence" SG_ 1060 PCS_a011_llcFrequency 1;
BA_ "Confidence" SG_ 1060 PCS_a011_intBusV 1;
BA_ "Confidence" SG_ 1060 PCS_a011_outputV 1;
BA_ "Confidence" SG_ 1060 PCS_a012_phState 1;
BA_ "Confidence" SG_ 1060 PCS_a012_llcFrequency 1;
BA_ "Confidence" SG_ 1060 PCS_a012_llcCurrent 1;
BA_ "Confidence" SG_ 1060 PCS_a012_outOfIBandDuration 1;
BA_ "Confidence" SG_ 1060 PCS_a012_batteryV 1;
BA_ "Confidence" SG_ 1060 PCS_a012_transientRetryCount 1;
BA_ "Confidence" SG_ 1060 PCS_a013_phState 1;
BA_ "Confidence" SG_ 1060 PCS_a013_intBusPrechargeTarget 1;
BA_ "Confidence" SG_ 1060 PCS_a013_intBusV 1;
BA_ "Confidence" SG_ 1060 PCS_a013_inputVrms 1;
BA_ "Confidence" SG_ 1060 PCS_a013_inputVToIntBusDeltaMax 1;
BA_ "Confidence" SG_ 1060 PCS_a013_inputFrequency 1;
BA_ "Confidence" SG_ 1060 PCS_a014_phaTemperature 1;
BA_ "Confidence" SG_ 1060 PCS_a014_phbTemperature 1;
BA_ "Confidence" SG_ 1060 PCS_a014_phcTemperature 1;
BA_ "Confidence" SG_ 1060 PCS_a015_lvBusVoltage 1;
BA_ "SystemSignalLongSymbol" SG_ 1060 PCS_a016_phAVoltSrcMissingDetect "PCS_a016_phAVoltSrcMissingDetected";
BA_ "SystemSignalLongSymbol" SG_ 1060 PCS_a016_phBVoltSrcMissingDetect "PCS_a016_phBVoltSrcMissingDetected";
BA_ "SystemSignalLongSymbol" SG_ 1060 PCS_a016_phCVoltSrcMissingDetect "PCS_a016_phCVoltSrcMissingDetected";
BA_ "Confidence" SG_ 1060 PCS_a018_PhaseDiff_L1N_L2N 1;
BA_ "Confidence" SG_ 1060 PCS_a018_PhaseDiff_L2N_L3N 1;
BA_ "Confidence" SG_ 1060 PCS_a018_PhaseDiff_L1N_L3N 1;
BA_ "Confidence" SG_ 1060 PCS_a018_PhaseDiff_L1L2_L1N 1;
BA_ "Confidence" SG_ 1060 PCS_a019_pcsMaxAvailablePower 1;
BA_ "Confidence" SG_ 1060 PCS_a019_utilityPowerAvailable 1;
BA_ "Confidence" SG_ 1060 PCS_a019_userPowerRequest 1;
BA_ "Confidence" SG_ 1060 PCS_a025_cpu2ErrorCode 1;
BA_ "SystemSignalLongSymbol" SG_ 1060 PCS_a025_bootromRequestStatusFla "PCS_a025_bootromRequestStatusFlag";
BA_ "Confidence" SG_ 1060 PCS_a027_chgPhATemp 1;
BA_ "Confidence" SG_ 1060 PCS_a027_chgPhBTemp 1;
BA_ "Confidence" SG_ 1060 PCS_a027_chgPhCTemp 1;
BA_ "Confidence" SG_ 1060 PCS_a027_chgPhANoFlowBucket 1;
BA_ "Confidence" SG_ 1060 PCS_a027_chgPhBNoFlowBucket 1;
BA_ "Confidence" SG_ 1060 PCS_a027_chgPhCNoFlowBucket 1;
BA_ "Confidence" SG_ 1060 PCS_a028_outputV 1;
BA_ "Confidence" SG_ 1060 PCS_a028_outputVUvThreshold 1;
BA_ "Confidence" SG_ 1060 PCS_a029_inputVrms 1;
BA_ "Confidence" SG_ 1060 PCS_a029_chgInputPower 1;
BA_ "Confidence" SG_ 1060 PCS_a029_bmsPowerCommand 1;
BA_ "Confidence" SG_ 1060 PCS_a029_phaseConfig 1;
BA_ "GenSigSNA" SG_ 1060 PCS_a029_phaseConfig "0";
BA_ "Confidence" SG_ 1060 PCS_a030_canRxErrorType 1;
BA_ "Confidence" SG_ 1060 PCS_a032_phATransientRetryCount 1;
BA_ "Confidence" SG_ 1060 PCS_a032_phBTransientRetryCount 1;
BA_ "Confidence" SG_ 1060 PCS_a032_phCTransientRetryCount 1;
BA_ "Confidence" SG_ 1060 PCS_a033_HV_busV 1;
BA_ "Confidence" SG_ 1060 PCS_a034_HV_busV 1;
BA_ "Confidence" SG_ 1060 PCS_a035_LV_busV 1;
BA_ "Confidence" SG_ 1060 PCS_a036_LV_busV 1;
BA_ "Confidence" SG_ 1060 PCS_a038_dcdcClaFaultCode 1;
BA_ "Confidence" SG_ 1060 PCS_a038_dcdcSubState 1;
BA_ "Confidence" SG_ 1060 PCS_a038_dcdcLvBusV 1;
BA_ "Confidence" SG_ 1060 PCS_a038_dcdcHvBusV 1;
BA_ "Confidence" SG_ 1060 PCS_a038_dcdcLvBusCurrent_A 1;
BA_ "SystemSignalLongSymbol" SG_ 1060 PCS_a038_dcdcPwmEnableDeasserted "PCS_a038_dcdcPwmEnableDeassertedCount";
BA_ "Confidence" SG_ 1060 PCS_a040_dcdcLvVoltageTarget 1;
BA_ "Confidence" SG_ 1060 PCS_a040_dcdcLvVoltage 1;
BA_ "Confidence" SG_ 1060 PCS_a040_dcdcLvOutputCurrent 1;
BA_ "Confidence" SG_ 1060 PCS_a041_dcdcTemperature 1;
BA_ "Confidence" SG_ 1060 PCS_a043_dcdcLvBusV 1;
BA_ "Confidence" SG_ 1060 PCS_a043_dcdcHvBusV 1;
BA_ "Confidence" SG_ 1060 PCS_a043_hvPrechargeTargetV 1;
BA_ "Confidence" SG_ 1060 PCS_a044_FaultReasonCode 1;
BA_ "GenSigSNA" SG_ 1060 PCS_a044_FaultReasonCode "0";
BA_ "Confidence" SG_ 1060 PCS_a044_shortTime_us 1;
BA_ "Confidence" SG_ 1060 PCS_a044_dcdcLvBusCurrent_A 1;
BA_ "Confidence" SG_ 1060 PCS_a044_vTankPeak_abs_V 1;
BA_ "Confidence" SG_ 1060 PCS_a045_hvBusEstimated_C_uF 1;
BA_ "Confidence" SG_ 1060 PCS_a045_hvBusEstimated_R_kOhm 1;
BA_ "Confidence" SG_ 1060 PCS_a046_hvBusEstimated_C_uF 1;
BA_ "Confidence" SG_ 1060 PCS_a046_hvBusEstimated_R_kOhm 1;
BA_ "SystemSignalLongSymbol" SG_ 1060 PCS_a047_cpu1BootLoaderCrcMismat "PCS_a047_cpu1BootLoaderCrcMismatch";
BA_ "SystemSignalLongSymbol" SG_ 1060 PCS_a047_cpu2BootLoaderCrcMismat "PCS_a047_cpu2BootLoaderCrcMismatch";
BA_ "Confidence" SG_ 1060 PCS_a049_dcdcTemperature 1;
BA_ "Confidence" SG_ 1060 PCS_a051_phState 1;
BA_ "Confidence" SG_ 1060 PCS_a051_pfcCurrentRms 1;
BA_ "Confidence" SG_ 1060 PCS_a051_llcCurrent 1;
BA_ "Confidence" SG_ 1060 PCS_a051_intBusV 1;
BA_ "Confidence" SG_ 1060 PCS_a051_intBusVTarget 1;
BA_ "Confidence" SG_ 1060 PCS_a051_intBusStaticRipple 1;
BA_ "Confidence" SG_ 1060 PCS_a052_inputVrms 1;
BA_ "Confidence" SG_ 1060 PCS_a053_inputVrms 1;
BA_ "Confidence" SG_ 1060 PCS_a053_inputIrms 1;
BA_ "Confidence" SG_ 1060 PCS_a053_acChargeCurrentLimit 1;
BA_ "Confidence" SG_ 1060 PCS_a053_startingInputVrms 1;
BA_ "Confidence" SG_ 1060 PCS_a053_phaseConfig 1;
BA_ "GenSigSNA" SG_ 1060 PCS_a053_phaseConfig "0";
BA_ "Confidence" SG_ 1060 PCS_a054_inputVrms 1;
BA_ "Confidence" SG_ 1060 PCS_a054_inputIrms 1;
BA_ "Confidence" SG_ 1060 PCS_a054_acChargeCurrentLimit 1;
BA_ "Confidence" SG_ 1060 PCS_a054_startingInputVrms 1;
BA_ "Confidence" SG_ 1060 PCS_a054_phaseConfig 1;
BA_ "GenSigSNA" SG_ 1060 PCS_a054_phaseConfig "0";
BA_ "Confidence" SG_ 1060 PCS_a057_inputVrms 1;
BA_ "Confidence" SG_ 1060 PCS_a057_inputFrequency 1;
BA_ "Confidence" SG_ 1060 PCS_a058_inputVrms 1;
BA_ "Confidence" SG_ 1060 PCS_a058_inputFrequency 1;
BA_ "Confidence" SG_ 1060 PCS_a059_inputVrms 1;
BA_ "Confidence" SG_ 1060 PCS_a059_inputOvRmsThreshold 1;
BA_ "Confidence" SG_ 1060 PCS_a060_inputVPeak 1;
BA_ "Confidence" SG_ 1060 PCS_a060_inputOvPeakThreshold 1;
BA_ "Confidence" SG_ 1060 PCS_a061_chgInputVdcOffset_L1N 1;
BA_ "Confidence" SG_ 1060 PCS_a061_chgInputVdcOffset_L2N 1;
BA_ "Confidence" SG_ 1060 PCS_a061_chgInputVdcOffset_L3N 1;
BA_ "Confidence" SG_ 1060 PCS_a061_chgInputVdcOffset_L1L2 1;
BA_ "SystemSignalLongSymbol" SG_ 1060 PCS_a061_PllSourceIrrational_L1L "PCS_a061_PllSourceIrrational_L1L2";
BA_ "Confidence" SG_ 1060 PCS_a062_chgInputIOffset 1;
BA_ "Confidence" SG_ 1060 PCS_a063_chgOutputV 1;
BA_ "Confidence" SG_ 1060 PCS_a063_hvpHvLinkVoltage 1;
BA_ "Confidence" SG_ 1060 PCS_a064_chgOutputIOffset 1;
BA_ "Confidence" SG_ 1060 PCS_a065_inputVrms 1;
BA_ "Confidence" SG_ 1060 PCS_a065_inputFrequency 1;
BA_ "Confidence" SG_ 1060 PCS_a066_dcdcHvBusVolt 1;
BA_ "Confidence" SG_ 1060 PCS_a066_hvpHvLinkVoltage 1;
BA_ "Confidence" SG_ 1060 PCS_a067_dcdcLvBusVolt 1;
BA_ "Confidence" SG_ 1060 PCS_a067_vcfrontPcsEFuseV 1;
BA_ "GenSigSNA" SG_ 1060 PCS_a067_vcfrontPcsEFuseV "1023";
BA_ "Confidence" SG_ 1060 PCS_a067_vcfrontVcrightVoltage 1;
BA_ "GenSigSNA" SG_ 1060 PCS_a067_vcfrontVcrightVoltage "1023";
BA_ "Confidence" SG_ 1060 PCS_a068_dcdcTankVolt 1;
BA_ "Confidence" SG_ 1060 PCS_a068_dcdcTankVoltOffset 1;
BA_ "Confidence" SG_ 1060 PCS_a069_phState 1;
BA_ "Confidence" SG_ 1060 PCS_a069_inputIDelta 1;
BA_ "Confidence" SG_ 1060 PCS_a069_inputVrms 1;
BA_ "Confidence" SG_ 1060 PCS_a069_intBusV 1;
BA_ "Confidence" SG_ 1060 PCS_a069_inputFrequency 1;
BA_ "Confidence" SG_ 1060 PCS_a070_phState 1;
BA_ "Confidence" SG_ 1060 PCS_a070_inputVDelta 1;
BA_ "Confidence" SG_ 1060 PCS_a070_inputVrms 1;
BA_ "Confidence" SG_ 1060 PCS_a070_intBusV 1;
BA_ "Confidence" SG_ 1060 PCS_a070_inputFrequency 1;
BA_ "Confidence" SG_ 1060 PCS_a071_phState 1;
BA_ "Confidence" SG_ 1060 PCS_a071_inputVrms 1;
BA_ "Confidence" SG_ 1060 PCS_a071_intBusV 1;
BA_ "Confidence" SG_ 1060 PCS_a071_inputFrequency 1;
BA_ "Confidence" SG_ 1060 PCS_a071_llcFrequency 1;
BA_ "Confidence" SG_ 1060 PCS_a073_inputL1NVrms 1;
BA_ "Confidence" SG_ 1060 PCS_a073_inputL2NVrms 1;
BA_ "Confidence" SG_ 1060 PCS_a073_inputL3NVrms 1;
BA_ "Confidence" SG_ 1060 PCS_a073_inputNGVrms 1;
BA_ "Confidence" SG_ 1060 PCS_a073_phaseConfig 1;
BA_ "GenSigSNA" SG_ 1060 PCS_a073_phaseConfig "0";
BA_ "Confidence" SG_ 1060 PCS_a073_cpType 1;
BA_ "Confidence" SG_ 1060 PCS_a074_dcdcLvBusV 1;
BA_ "Confidence" SG_ 1060 PCS_a074_dcdcHvBusV 1;
BA_ "Confidence" SG_ 1060 PCS_a075_dcdcLvBusV 1;
BA_ "Confidence" SG_ 1060 PCS_a075_dcdcHvBusV 1;
BA_ "Confidence" SG_ 1060 PCS_a075_dcdcSubState 1;
BA_ "Confidence" SG_ 1060 PCS_a076_pcsControlRequest 1;
BA_ "Confidence" SG_ 1060 PCS_a076_dcdcSubState 1;
BA_ "SystemSignalLongSymbol" SG_ 1060 PCS_a076_dcdcPwmEnableDeasserted "PCS_a076_dcdcPwmEnableDeassertedCount";
BA_ "Confidence" SG_ 1060 PCS_a078_phaTemperature 1;
BA_ "Confidence" SG_ 1060 PCS_a078_phbTemperature 1;
BA_ "Confidence" SG_ 1060 PCS_a078_phcTemperature 1;
BA_ "Confidence" SG_ 1060 PCS_a078_dcdcTemperature 1;
BA_ "Confidence" SG_ 1060 PCS_a078_ptCoolantTemp 1;
BA_ "Confidence" SG_ 1060 PCS_a079_eepromOperation 1;
BA_ "GenSigSNA" SG_ 1060 PCS_a079_eepromOperation "15";
BA_ "Confidence" SG_ 1060 PCS_a079_eepromOperationRegion 1;
BA_ "SystemSignalLongSymbol" SG_ 1060 PCS_a079_eepromOperationErrorCod "PCS_a079_eepromOperationErrorCode";
BA_ "Confidence" SG_ 1060 PCS_a080_phANVRAMStoredState 1;
BA_ "Confidence" SG_ 1060 PCS_a080_phBNVRAMStoredState 1;
BA_ "Confidence" SG_ 1060 PCS_a080_phCNVRAMStoredState 1;
BA_ "Confidence" SG_ 1060 PCS_a081_dcdcLvBusV 1;
BA_ "Confidence" SG_ 1060 PCS_a081_dcdcHvBusV 1;
BA_ "Confidence" SG_ 1060 PCS_a081_faultedSubstate 1;
BA_ "Confidence" SG_ 1060 PCS_a082_dcdcLvBusV 1;
BA_ "Confidence" SG_ 1060 PCS_a082_dcdcHvBusV 1;
BA_ "Confidence" SG_ 1060 PCS_a082_faultedSubstate 1;
BA_ "Confidence" SG_ 1060 PCS_a085_dcdcHalfPeriodUs 1;
BA_ "Confidence" SG_ 1060 PCS_a086_dcdcTemperature 1;
BA_ "Confidence" SG_ 1060 PCS_a086_pcsAmbientTemperature 1;
BA_ "Confidence" SG_ 1060 PCS_a086_vcfrontPTCoolantTemp 1;
BA_ "Confidence" SG_ 1060 PCS_a088_gridConfig 1;
BA_ "GenSigSNA" SG_ 1060 PCS_a088_gridConfig "0";
BA_ "Confidence" SG_ 1060 PCS_a088_phAFrequency 1;
BA_ "Confidence" SG_ 1060 PCS_a088_phBFrequency 1;
BA_ "Confidence" SG_ 1060 PCS_a088_phCFrequency 1;
BA_ "Confidence" SG_ 1060 PCS_a089_hvSlewRate 1;
BA_ "Confidence" SG_ 1060 PCS_a089_avgSlewRate 1;
BA_ "Confidence" SG_ 1060 PCS_a089_G 1;
BA_ "Confidence" SG_ 1060 PCS_a089_HV_busV 1;
BA_ "Confidence" SG_ 1060 PCS_a089_PhaseShift 1;
BA_ "Confidence" SG_ 1060 PCS_a089_Freq 1;
BA_ "Confidence" SG_ 1060 PCS_a090_vRmsL1N 1;
BA_ "Confidence" SG_ 1060 PCS_a090_vRmsL2N 1;
BA_ "Confidence" SG_ 1060 PCS_a090_vRmsL3N 1;
BA_ "Confidence" SG_ 1060 PCS_a090_vRmsL1L2 1;
BA_ "Confidence" SG_ 1060 PCS_a090_evaluatedGridConfig 1;
BA_ "GenSigSNA" SG_ 1060 PCS_a090_evaluatedGridConfig "0";
BA_ "Confidence" SG_ 1060 PCS_a091_intBusTarget 1;
BA_ "Confidence" SG_ 1060 PCS_a091_intBusMaxRippleLevel 1;
BA_ "Confidence" SG_ 1060 PCS_a091_pfcCurrentIrms 1;
BA_ "Confidence" SG_ 1060 PCS_a091_phaseInputVrms 1;
BA_ "Confidence" SG_ 1060 PCS_a091_phaseTemp 1;
BA_ "Confidence" SG_ 1060 PCS_a092_pfcIrmsPhA 1;
BA_ "Confidence" SG_ 1060 PCS_a092_pfcIrmsPhB 1;
BA_ "Confidence" SG_ 1060 PCS_a092_pfcIrmsPhC 1;
BA_ "Confidence" SG_ 1060 PCS_a092_chgTempPhA 1;
BA_ "Confidence" SG_ 1060 PCS_a092_chgTempPhB 1;
BA_ "Confidence" SG_ 1060 PCS_a092_chgTempPhC 1;
BA_ "Confidence" SG_ 1060 PCS_a093_powerRail5VN 1;
BA_ "Confidence" SG_ 1060 PCS_a093_powerRail3V3 1;
BA_ "Confidence" SG_ 1060 PCS_a093_powerRail1V5 1;
BA_ "Confidence" SG_ 1060 PCS_a093_powerRail1V2 1;
BA_ "Confidence" SG_ 1060 PCS_a094_malfunctionCode 1;
BA_ "Confidence" SG_ 1060 PCS_a095_powerRail5VN 1;
BA_ "Confidence" SG_ 1060 PCS_a095_pcsControlRequest 1;
BA_ "Confidence" SG_ 1060 PCS_a096_gridConfig 1;
BA_ "GenSigSNA" SG_ 1060 PCS_a096_gridConfig "0";
BA_ "Confidence" SG_ 1060 PCS_a096_phAFrequency 1;
BA_ "Confidence" SG_ 1060 PCS_a096_phBFrequency 1;
BA_ "Confidence" SG_ 1060 PCS_a096_phCFrequency 1;
BA_ "Confidence" SG_ 1060 PCS_a097_phANVRAMStoredState 1;
BA_ "Confidence" SG_ 1060 PCS_a097_phBNVRAMStoredState 1;
BA_ "Confidence" SG_ 1060 PCS_a097_phCNVRAMStoredState 1;
BA_ "Confidence" SG_ 1060 PCS_a100_inputVrms 1;
BA_ "Confidence" SG_ 1060 PCS_a100_phIntBusVolt 1;
BA_ "Confidence" SG_ 1060 PCS_a100_phKwhCounter 1;
BA_ "Confidence" SG_ 1060 PCS_a100_phKwhCounterDeltaFromMa 1;
BA_ "SystemSignalLongSymbol" SG_ 1060 PCS_a100_phKwhCounterDeltaFromMa "PCS_a100_phKwhCounterDeltaFromMax";
BA_ "Confidence" SG_ 1060 PCS_a102_pcsControlRequest 1;
BA_ "Confidence" SG_ 1060 PCS_a104_ambientTemperature 1;
BA_ "SystemSignalLongSymbol" SG_ 1060 PCS_a108_installedInAWrongPlatfo "PCS_a108_installedInAWrongPlatform";
BA_ "Confidence" SG_ 1060 PCS_a109_inputL2NVrms 1;
BA_ "Confidence" SG_ 1060 PCS_a109_inputL3NVrms 1;
BA_ "Confidence" SG_ 932 PCS_matrixIndex 1;
BA_ "SystemSignalLongSymbol" SG_ 932 PCS_a032_excessiveGridTransients "PCS_a032_excessiveGridTransientsDetected";
BA_ "SystemSignalLongSymbol" SG_ 932 PCS_a073_unexpectedAcInputVoltag "PCS_a073_unexpectedAcInputVoltage";
BA_ "SystemSignalLongSymbol" SG_ 932 PCS_a084_vDropFastInParasiticDio "PCS_a084_vDropFastInParasiticDiodeRegion";
BA_ "SystemSignalLongSymbol" SG_ 932 PCS_a089_hvBusDischargeIrrationa "PCS_a089_hvBusDischargeIrrational";
BA_ "SystemSignalLongSymbol" SG_ 932 PCS_a090_expectedAcVoltageSource "PCS_a090_expectedAcVoltageSourceMissing";
BA_ "SystemSignalLongSymbol" SG_ 932 PCS_a092_chgPowerLimitedByBusRip "PCS_a092_chgPowerLimitedByBusRipple";
BA_ "SystemSignalLongSymbol" SG_ 932 PCS_a095_dcdcSensorlessModeActiv "PCS_a095_dcdcSensorlessModeActive";
BA_ "SystemSignalLongSymbol" SG_ 932 PCS_a098_gridFreqDroopDetectedSi "PCS_a098_gridFreqDroopDetectedSilent";
BA_ "SystemSignalLongSymbol" SG_ 932 PCS_a099_microGridOverLoadedSile "PCS_a099_microGridOverLoadedSilent";
BA_ "SystemSignalLongSymbol" SG_ 932 PCS_a101_phMachineModelIrrationa "PCS_a101_phMachineModelIrrational";
BA_ "SystemSignalLongSymbol" SG_ 932 PCS_a102_resetWithDCDCCmdAsserte "PCS_a102_resetWithDCDCCmdAsserted";
BA_ "SystemSignalLongSymbol" SG_ 932 PCS_a105_redundantVoltageSourceI "PCS_a105_redundantVoltageSourceIrrational";
BA_ "SystemSignalLongSymbol" SG_ 932 PCS_a106_clockSourceNotFromExter "PCS_a106_clockSourceNotFromExternalCrystal";
BA_ "SystemSignalLongSymbol" SG_ 932 PCS_a108_misconfigurationDetecte "PCS_a108_misconfigurationDetected";
BA_ "SystemSignalLongSymbol" SG_ 932 PCS_a109_deltaChargingL2L3Swappe "PCS_a109_deltaChargingL2L3SwappedDetected";
BA_ "Confidence" SG_ 612 PCS_chgInputVoltage 0;
BA_ "Confidence" SG_ 612 PCS_chgLineCurrent 0;
BA_ "Confidence" SG_ 612 PCS_chgAcVoltagePresent 0;
BA_ "Confidence" SG_ 612 PCS_chgInputPower 0;
BA_ "Confidence" SG_ 612 PCS_chgAcCurrentLimit 0;
BA_ "Confidence" SG_ 516 PCS_chgMainState 0;
BA_ "Confidence" SG_ 516 PCS_hvChargeStatus 1;
BA_ "Confidence" SG_ 516 PCS_gridConfig 0;
BA_ "GenSigSNA" SG_ 516 PCS_gridConfig "0";
BA_ "Confidence" SG_ 516 PCS_chgPHAEnable 0;
BA_ "Confidence" SG_ 516 PCS_chgPHBEnable 0;
BA_ "Confidence" SG_ 516 PCS_hvInletConductorEnergizedAc 0;
BA_ "Confidence" SG_ 516 PCS_chgHighPowerActive 0;
BA_ "Confidence" SG_ 516 PCS_chgPHCEnable 0;
BA_ "Confidence" SG_ 516 PCS_chgInstantAcPowerAvailable 0;
BA_ "Confidence" SG_ 516 PCS_chgMaxAcPowerAvailable 0;
BA_ "GenSigSNA" SG_ 516 PCS_chgMaxAcPowerAvailable "255";
BA_ "Confidence" SG_ 516 PCS_chgPHALineCurrentRequest 0;
BA_ "Confidence" SG_ 516 PCS_chgPHBLineCurrentRequest 0;
BA_ "Confidence" SG_ 516 PCS_chgPHCLineCurrentRequest 0;
BA_ "Confidence" SG_ 516 PCS_chgPwmEnableLine 0;
BA_ "Confidence" SG_ 516 PCS_chargeShutdownRequest 1;
BA_ "Confidence" SG_ 516 PCS_hwVariantType 0;
BA_ "GenSigSNA" SG_ 516 PCS_hwVariantType "3";
BA_ "Confidence" SG_ 692 PCS_dcdcLvBusVolt 0;
BA_ "Confidence" SG_ 692 PCS_dcdcHvBusVolt 0;
BA_ "Confidence" SG_ 692 PCS_dcdcLvOutputCurrent 0;
BA_ "Confidence" SG_ 548 PCS_dcdcPrechargeStatus 0;
BA_ "Confidence" SG_ 548 PCS_dcdcLvSupportStatus 0;
BA_ "Confidence" SG_ 548 PCS_dcdcHvBusDischargeStatus 0;
BA_ "Confidence" SG_ 548 PCS_coldSleepAllowed 0;
BA_ "Confidence" SG_ 548 PCS_dcdcPchgHVBusLowRDetected 0;
BA_ "Confidence" SG_ 548 PCS_dcdcSubState 0;
BA_ "Confidence" SG_ 548 PCS_dcdcFaulted 0;
BA_ "Confidence" SG_ 548 PCS_okToBePowerCycled 0;
BA_ "Confidence" SG_ 548 PCS_dcdcOutputIsLimited 0;
BA_ "Confidence" SG_ 548 PCS_dcdcMaxOutputCurrentAllowed 0;
BA_ "Confidence" SG_ 548 PCS_dcdcPrechargeRtyCnt 0;
BA_ "Confidence" SG_ 548 PCS_dcdcLvSupportRtyCnt 0;
BA_ "Confidence" SG_ 548 PCS_dcdcDischargeRtyCnt 0;
BA_ "Confidence" SG_ 548 PCS_dcdcPwmEnableLine 0;
BA_ "Confidence" SG_ 548 PCS_dcdcSupportingFixedLvTarget 0;
BA_ "Confidence" SG_ 548 PCS_ecuLogUploadRequest 0;
BA_ "Confidence" SG_ 548 PCS_dcdcPrechargeRestartCnt 0;
BA_ "Confidence" SG_ 548 PCS_dcdcInitialPrechargeSubState 0;
VAL_ 862 PARK_rearLeftMiddleRawDistData 255 "SNA" ;
VAL_ 862 PARK_rearMiddleRawDistData 255 "SNA" ;
VAL_ 862 PARK_rearRightMiddleRawDistData 255 "SNA" ;
VAL_ 926 PARK_rightSideFrontRawDistData 255 "SNA" ;
VAL_ 926 PARK_rightSideRearRawDistData 255 "SNA" ;
VAL_ 926 PARK_leftSideFrontRawDistData 255 "SNA" ;
VAL_ 926 PARK_leftSideRearRawDistData 255 "SNA" ;
VAL_ 606 PARK_pscEnvSlotType 3 "RIGHT_CROSS" 2 "RIGHT_PARALLEL" 1 "LEFT_CROSS" 0 "LEFT_PARALLEL" ;
VAL_ 606 PARK_pscLeftParallelObj1X 2047 "SNA" 2046 "NO_SPACE" ;
VAL_ 606 PARK_pscLeftParallelObj1Y 2047 "SNA" 2046 "NO_SPACE" ;
VAL_ 606 PARK_pscLeftParallelObj1Alpha 127 "SNA" 126 "NO_SPACE" ;
VAL_ 606 PARK_pscLeftParallelObj2Y 2047 "SNA" 2046 "NO_SPACE" ;
VAL_ 606 PARK_pscLeftParallelObj2X 2047 "SNA" 2046 "NO_SPACE" ;
VAL_ 606 PARK_pscLeftParallelObj2Alpha 127 "SNA" 126 "NO_SPACE" ;
VAL_ 606 PARK_pscLeftCrossObj1X 2047 "SNA" 2046 "NO_SPACE" ;
VAL_ 606 PARK_pscLeftCrossObj1Y 2047 "SNA" 2046 "NO_SPACE" ;
VAL_ 606 PARK_pscLeftCrossObj1Alpha 127 "SNA" 126 "NO_SPACE" ;
VAL_ 606 PARK_pscLeftCrossObj2Y 2047 "SNA" 2046 "NO_SPACE" ;
VAL_ 606 PARK_pscLeftCrossObj2X 2047 "SNA" 2046 "NO_SPACE" ;
VAL_ 606 PARK_pscLeftCrossObj2Alpha 127 "SNA" 126 "NO_SPACE" ;
VAL_ 606 PARK_pscRightParallelObj1X 2047 "SNA" 2046 "NO_SPACE" ;
VAL_ 606 PARK_pscRightParallelObj1Y 2047 "SNA" 2046 "NO_SPACE" ;
VAL_ 606 PARK_pscRightParallelObj1Alpha 127 "SNA" 126 "NO_SPACE" ;
VAL_ 606 PARK_pscRightParallelObj2Y 2047 "SNA" 2046 "NO_SPACE" ;
VAL_ 606 PARK_pscRightParallelObj2X 2047 "SNA" 2046 "NO_SPACE" ;
VAL_ 606 PARK_pscRightParallelObj2Alpha 127 "SNA" 126 "NO_SPACE" ;
VAL_ 606 PARK_pscRightCrossObj1X 2047 "SNA" 2046 "NO_SPACE" ;
VAL_ 606 PARK_pscRightCrossObj1Y 2047 "SNA" 2046 "NO_SPACE" ;
VAL_ 606 PARK_pscRightCrossObj1Alpha 127 "SNA" 126 "NO_SPACE" ;
VAL_ 606 PARK_pscRightCrossObj2Y 2047 "SNA" 2046 "NO_SPACE" ;
VAL_ 606 PARK_pscRightCrossObj2X 2047 "SNA" 2046 "NO_SPACE" ;
VAL_ 606 PARK_pscRightCrossObj2Alpha 127 "SNA" 126 "NO_SPACE" ;
VAL_ 542 PARK_pscParkStatus 7 "SNA" 6 "FAULT" 5 "GUIDANCE_FINISHED" 4 "PRE_GUIDANCE" 3 "GUIDANCE_RIGHT" 2 "GUIDANCE_LEFT" 1 "SEARCHING" 0 "NOT_AVAILABLE" ;
VAL_ 542 PARK_pscParkAbortReason 31 "SNA" 25 "PSC_MOVEMENT_AT_ACTIVATION" 24 "PSC_MAX_WAY_BEHIND_HINT" 23 "PSC_PARK_STC_FAILED" 22 "PSC_PARK_PONR_NOT_REACHED" 21 "PSC_VCTL_GENERAL_ABORT" 20 "PSC_HIGH_TORQUE" 19 "PSC_ASYNC_CTRL_SYSTEM" 18 "ERROR" 17 "SYSTEM_SERVICE" 16 "SYSTEM_FAULT" 15 "ECU_INTERNAL_FAULT" 14 "DAS_ABORT" 13 "EPAS_FAULT" 12 "VEHICLE_DYNAMICS_INTERVENTION" 11 "HANDS_ON_DETECTED" 10 "FULL_WARNING_ON_BOTH_SIDES" 9 "PARK_SPACE_TOO_SMALL" 8 "OBSTACLE_ON_PATH" 7 "MAX_YAW_ANGLE_REACHED" 6 "MAX_SWA_DEV_EXCEEDED" 5 "OFF_TRACK" 4 "UNCONTROLLED_TRAVEL_DIST_REACHED" 3 "NO_VALID_PATH" 2 "MAX_NUM_OF_MOVES" 1 "VELOCITY_TOO_HIGH" 0 "NONE" ;
VAL_ 542 PARK_pscParallelSpace 3 "BOTH_AVAILABLE" 2 "LEFT_AVAILABLE" 1 "RIGHT_AVAILABLE" 0 "NONE_AVAILABLE" ;
VAL_ 542 PARK_pscCrossSpace 3 "BOTH_AVAILABLE" 2 "LEFT_AVAILABLE" 1 "RIGHT_AVAILABLE" 0 "NONE_AVAILABLE" ;
VAL_ 542 PARK_pscParallelRightParkable 3 "SNA" 2 "PARKING_SLOT_OK_POSITION_OK" 1 "PARKING_SLOT_OK" 0 "NONE" ;
VAL_ 542 PARK_pscParallelLeftParkable 3 "SNA" 2 "PARKING_SLOT_OK_POSITION_OK" 1 "PARKING_SLOT_OK" 0 "NONE" ;
VAL_ 542 PARK_pscCrossRightParkable 3 "SNA" 2 "PARKING_SLOT_OK_POSITION_OK" 1 "PARKING_SLOT_OK" 0 "NONE" ;
VAL_ 542 PARK_pscMaxVelocity 63 "SNA" ;
VAL_ 542 PARK_pscCrossLeftParkable 3 "SNA" 2 "PARKING_SLOT_OK_POSITION_OK" 1 "PARKING_SLOT_OK" 0 "NONE" ;
VAL_ 542 PARK_pscParkInstruction 7 "SNA" 5 "EXPLORATION" 4 "ABORTED" 3 "DRIVE_BACKWARD" 2 "DRIVE_FORWARD" 1 "STOP" 0 "NO_MESSAGE" ;
VAL_ 542 PARK_pscManeuverDistance 2047 "SNA" ;
VAL_ 542 PARK_pscAngleActive 1 "REQUEST_CONTROL" 0 "INACTIVE" ;
VAL_ 590 PARK_pscVehSlotType 3 "RIGHT_CROSS" 2 "RIGHT_PARALLEL" 1 "LEFT_CROSS" 0 "LEFT_PARALLEL" ;
VAL_ 590 PARK_pscLeftParallelVehX 2047 "SNA" 2046 "NO_SPACE" ;
VAL_ 590 PARK_pscLeftParallelVehY 2047 "SNA" 2046 "NO_SPACE" ;
VAL_ 590 PARK_pscLeftParallelPsi 8191 "SNA" 8190 "NO_SPACE" ;
VAL_ 590 PARK_pscLeftParallelSizeX 255 "SNA" 254 "NO_SPACE" ;
VAL_ 590 PARK_pscLeftParallelSizeY 255 "SNA" 254 "NO_SPACE" ;
VAL_ 590 PARK_pscLeftCrossVehX 2047 "SNA" 2046 "NO_SPACE" ;
VAL_ 590 PARK_pscLeftCrossVehY 2047 "SNA" 2046 "NO_SPACE" ;
VAL_ 590 PARK_pscLeftCrossPsi 8191 "SNA" 8190 "NO_SPACE" ;
VAL_ 590 PARK_pscLeftCrossSizeX 255 "SNA" 254 "NO_SPACE" ;
VAL_ 590 PARK_pscLeftCrossSizeY 255 "SNA" 254 "NO_SPACE" ;
VAL_ 590 PARK_pscRightParallelVehX 2047 "SNA" 2046 "NO_SPACE" ;
VAL_ 590 PARK_pscRightParallelVehY 2047 "SNA" 2046 "NO_SPACE" ;
VAL_ 590 PARK_pscRightParallelPsi 8191 "SNA" 8190 "NO_SPACE" ;
VAL_ 590 PARK_pscRightParallelSizeX 255 "SNA" 254 "NO_SPACE" ;
VAL_ 590 PARK_pscRightParallelSizeY 255 "SNA" 254 "NO_SPACE" ;
VAL_ 590 PARK_pscRightCrossVehX 2047 "SNA" 2046 "NO_SPACE" ;
VAL_ 590 PARK_pscRightCrossVehY 2047 "SNA" 2046 "NO_SPACE" ;
VAL_ 590 PARK_pscRightCrossPsi 8191 "SNA" 8190 "NO_SPACE" ;
VAL_ 590 PARK_pscRightCrossSizeX 255 "SNA" 254 "NO_SPACE" ;
VAL_ 590 PARK_pscRightCrossSizeY 255 "SNA" 254 "NO_SPACE" ;
VAL_ 526 PARK_sdiSensor1RawDistData 511 "SNA" 500 "NO_OBJECT_DETECTED" 1 "NEAR_DETECTION" 0 "BLOCKED" ;
VAL_ 526 PARK_sdiSensor2RawDistData 511 "SNA" 500 "NO_OBJECT_DETECTED" 1 "NEAR_DETECTION" 0 "BLOCKED" ;
VAL_ 526 PARK_sdiSensor3RawDistData 511 "SNA" 500 "NO_OBJECT_DETECTED" 1 "NEAR_DETECTION" 0 "BLOCKED" ;
VAL_ 526 PARK_sdiSensor4RawDistData 511 "SNA" 500 "NO_OBJECT_DETECTED" 1 "NEAR_DETECTION" 0 "BLOCKED" ;
VAL_ 526 PARK_sdiSensor5RawDistData 511 "SNA" 500 "NO_OBJECT_DETECTED" 1 "NEAR_DETECTION" 0 "BLOCKED" ;
VAL_ 526 PARK_sdiSensor6RawDistData 511 "SNA" 500 "NO_OBJECT_DETECTED" 1 "NEAR_DETECTION" 0 "BLOCKED" ;
VAL_ 558 PARK_sdiSensor7RawDistData 511 "SNA" 500 "NO_OBJECT_DETECTED" 1 "NEAR_DETECTION" 0 "BLOCKED" ;
VAL_ 558 PARK_sdiSensor8RawDistData 511 "SNA" 500 "NO_OBJECT_DETECTED" 1 "NEAR_DETECTION" 0 "BLOCKED" ;
VAL_ 558 PARK_sdiSensor9RawDistData 511 "SNA" 500 "NO_OBJECT_DETECTED" 1 "NEAR_DETECTION" 0 "BLOCKED" ;
VAL_ 558 PARK_sdiSensor10RawDistData 511 "SNA" 500 "NO_OBJECT_DETECTED" 1 "NEAR_DETECTION" 0 "BLOCKED" ;
VAL_ 558 PARK_sdiSensor11RawDistData 511 "SNA" 500 "NO_OBJECT_DETECTED" 1 "NEAR_DETECTION" 0 "BLOCKED" ;
VAL_ 558 PARK_sdiSensor12RawDistData 511 "SNA" 500 "NO_OBJECT_DETECTED" 1 "NEAR_DETECTION" 0 "BLOCKED" ;
VAL_ 814 PARK_frontRightSensorState 3 "SNA" 2 "TEMPORARY_FAILURE" 1 "PERMANENT_FAILURE" 0 "NO_FAILURE" ;
VAL_ 814 PARK_frontRightMiddleSensorState 3 "SNA" 2 "TEMPORARY_FAILURE" 1 "PERMANENT_FAILURE" 0 "NO_FAILURE" ;
VAL_ 814 PARK_frontLeftMiddleSensorState 3 "SNA" 2 "TEMPORARY_FAILURE" 1 "PERMANENT_FAILURE" 0 "NO_FAILURE" ;
VAL_ 814 PARK_frontLeftSensorState 3 "SNA" 2 "TEMPORARY_FAILURE" 1 "PERMANENT_FAILURE" 0 "NO_FAILURE" ;
VAL_ 814 PARK_frontLeftRawDistData 255 "SNA" ;
VAL_ 814 PARK_frontRightRawDistData 255 "SNA" ;
VAL_ 814 PARK_systemStatusFront 3 "SNA" 2 "UNUSED" 1 "ENABLED" 0 "DISABLED" ;
VAL_ 814 PARK_frontDtcPresent 3 "SNA" 2 "UNUSED" 1 "TRUE" 0 "FALSE" ;
VAL_ 830 PARK_rearRightSensorState 3 "SNA" 2 "TEMPORARY_FAILURE" 1 "PERMANENT_FAILURE" 0 "NO_FAILURE" ;
VAL_ 830 PARK_rearRightMiddleSensorState 3 "SNA" 2 "TEMPORARY_FAILURE" 1 "PERMANENT_FAILURE" 0 "NO_FAILURE" ;
VAL_ 830 PARK_rearLeftMiddleSensorState 3 "SNA" 2 "TEMPORARY_FAILURE" 1 "PERMANENT_FAILURE" 0 "NO_FAILURE" ;
VAL_ 830 PARK_rearLeftSensorState 3 "SNA" 2 "TEMPORARY_FAILURE" 1 "PERMANENT_FAILURE" 0 "NO_FAILURE" ;
VAL_ 830 PARK_rearLeftRawDistData 255 "SNA" ;
VAL_ 830 PARK_rearRightRawDistData 255 "SNA" ;
VAL_ 830 PARK_systemStatusRear 3 "SNA" 2 "UNUSED" 1 "ENABLED" 0 "DISABLED" ;
VAL_ 830 PARK_rearDtcPresent 3 "SNA" 2 "UNUSED" 1 "TRUE" 0 "FALSE" ;
VAL_ 799 PARK_status 3 "SNA" 2 "TEMPORARY_FAILURE" 1 "ENABLED" 0 "DISABLED" ;
VAL_ 799 PARK_serviceRequest 3 "SNA" 2 "UNUSED" 1 "FAILURE" 0 "NO_FAILURE" ;
VAL_ 799 PARK_systemDtcPresent 3 "SNA" 2 "UNUSED" 1 "TRUE" 0 "FALSE" ;
VAL_ 799 PARK_majorVersion 255 "SNA" ;
VAL_ 799 PARK_minorVersion 255 "SNA" ;
VAL_ 799 PARK_subMinorVersion 255 "SNA" ;
VAL_ 782 PARK_pscRightCurbType 2 "HIGH_CURB" 1 "LOW_CURB" 0 "VIRTUAL_CURB" ;
VAL_ 782 PARK_pscLeftCurbType 2 "HIGH_CURB" 1 "LOW_CURB" 0 "VIRTUAL_CURB" ;
VAL_ 782 PARK_autoCalComplete 1 "COMPLETE" 0 "INCOMPLETE" ;
VAL_ 782 PARK_geometryType 3 "MODELY" 2 "MODEL3" 1 "MODELX" 0 "MODELS" ;
VAL_ 782 PARK_tireFitment 3 "SNA" 2 "NOT_USED" 1 "STAGGERED" 0 "SQUARE" ;
VAL_ 782 PARK_rackDetected 3 "SNA" 2 "RACK_DETECTED" 1 "NO_RACK" 0 "UNKNOWN" ;
VAL_ 782 PARK_sdiActive 1 "SDI_ENABLED" 0 "SDI_DISABLED" ;
VAL_ 782 PARK_sdiNoise 3 "SDI_NOISE_SNA" 2 "SDI_NOISE_RAIN" 1 "SDI_NOISE_HIGH" 0 "SDI_NOISE_NOMINAL" ;
VAL_ 782 PARK_sdiBlindSpotRight 3 "SNA" 2 "UNUSED" 1 "WARNING" 0 "NO_WARNING" ;
VAL_ 782 PARK_sdiBlindSpotLeft 3 "SNA" 2 "UNUSED" 1 "WARNING" 0 "NO_WARNING" ;
VAL_ 782 PARK_sensorType 3 "SNA" 2 "VALEO_HP" 1 "VALEO_HPFL" 0 "NONE" ;
VAL_ 894 PARK_matrixIndex 1 "AlertMatrix1" 0 "AlertMatrix0" ;
VAL_ 1060 PCS_alertID 109 "a109_deltaChargingL2L3SwappedDetected" 108 "a108_misconfigurationDetected" 107 "a107_vcPcsDCDCInterfaceMia" 106 "a106_clockSourceNotFromExternalCrystal" 105 "a105_redundantVoltageSourceIrrational" 104 "a104_ambientTempRationality" 103 "a103_pchgWithLowLvDetected" 102 "a102_resetWithDCDCCmdAsserted" 101 "a101_phMachineModelIrrational" 100 "a100_suspectedViperChipIssue" 99 "a099_microGridOverLoadedSilent" 98 "a098_gridFreqDroopDetectedSilent" 97 "a097_rebootPhaseDetected" 96 "a096_microGridOverLoaded" 95 "a095_dcdcSensorlessModeActive" 94 "a094_pcsDcdcNeedService" 93 "a093_powerRailRationality" 92 "a092_chgPowerLimitedByBusRipple" 91 "a091_chgIntBusRationality" 90 "a090_expectedAcVoltageSourceMissing" 89 "a089_hvBusDischargeIrrational" 88 "a088_gridFreqDroopDetected" 87 "a087_nvramRecordStatusError" 86 "a086_dcdcInsufficientCooling" 85 "a085_dcdcFetsNotSwitching" 84 "a084_vDropFastInParasiticDiodeRegion" 83 "a083_triggerOdin" 82 "a082_dcdcPchgUnsafeDiVoltage" 81 "a081_dcdcPchgTimeout" 80 "a080_damagedPhaseDetected" 79 "a079_eepromOperationError" 78 "a078_chgStopDcdcTooHot" 77 "a077_microGridWobbleDetected" 76 "a076_dcdcEnDeassertedErr" 75 "a075_hvBusDischargeTimeout" 74 "a074_hvBusDischargeFailure" 73 "a073_unexpectedAcInputVoltage" 72 "a072_cpu2ClaStopped" 71 "a071_chgPfcILoopRationality" 70 "a070_chgPfcLineDvdt" 69 "a069_chgPfcLineDidt" 68 "a068_dcdcTankvRationality" 67 "a067_dcdcLvRationality" 66 "a066_dcdcHvRationality" 65 "a065_chgPllNotLocked" 64 "a064_chgIOutRationality" 63 "a063_chgVOutRationality" 62 "a062_chgILineRationality" 61 "a061_chgVLineRationality" 60 "a060_chgInputOvPeak" 59 "a059_chgInputOvRms" 58 "a058_chgInputUnderFreq" 57 "a057_chgInputOverFreq" 56 "a056_chgLineImpedanceTooHigh" 55 "a055_chgLineImpedanceHigh" 54 "a054_chgInputVDropTooHigh" 53 "a053_chgInputVDropHigh" 52 "a052_acVoltageNotPresent" 51 "a051_chgIntBusUv" 50 "a050_dcdc12VsupportFaulted" 49 "a049_dcdcTempRationality" 48 "a048_softwareAssertion" 47 "a047_bootloaderCrcMismatch" 46 "a046_hvBusHighImpedence" 45 "a045_hvBusLowImpedance" 44 "a044_12vSupportRegulation" 43 "a043_hvBusPrechargeFailure" 42 "a042_dcdcEnableLineMismatch" 41 "a041_dcdcOverTemp" 40 "a040_dcdcMaxPowerReached" 39 "a039_sdModuleClkFault" 38 "a038_claFaulted" 37 "a037_resonantTankOc" 36 "a036_lvBusOv" 35 "a035_lvBusUv" 34 "a034_hvBusOv" 33 "a033_hvBusUv" 32 "a032_excessiveGridTransientsDetected" 31 "a031_uiMia" 30 "a030_canRationality" 29 "a029_chgPowerRationality" 28 "a028_chgOutputUv" 27 "a027_chgInsufficientCooling" 26 "a026_watchdogAlarmed" 25 "a025_cpu2Malfunction" 24 "a024_vcfrontMia" 23 "a023_cpMia" 22 "a022_bmsMia" 21 "a021_hvpMia" 20 "a020_chgEnableLineMismatch" 19 "a019_acChargePowerLimited" 18 "a018_chgUnknownGridConfig" 17 "a017_chgWallPowerRemoval" 16 "a016_chgAllPhasesFaulted" 15 "a015_chg12vUv" 14 "a014_chgTempRationality" 13 "a013_chgPrechargeFailedBoost" 12 "a012_chgPfcIBandTracerFault" 11 "a011_chgLlcCurrentRegulation" 10 "a010_chgIntBusVRegulation" 9 "a009_chgPfcCurrentRegulation" 8 "a008_chgPhaseOverTemp" 7 "a007_chgPhaseTempHot" 6 "a006_chgPrechargeFailedScr" 5 "a005_chgOutputOv" 4 "a004_chgHwIntBusOv" 3 "a003_chgHwInputOv" 2 "a002_chgHwOutputOc" 1 "a001_chgHwInputOc" 0 "ALERT_DO_NOT_USE_ZERO" ;
VAL_ 1060 PCS_alertSet 1 "SET" 0 "CLEARED" ;
VAL_ 1060 PCS_alertSource 5 "DCDC" 4 "CHG_SYSTEM" 3 "CHG_PHC" 2 "CHG_PHB" 1 "CHG_PHA" 0 "DEFAULT" ;
VAL_ 1060 PCS_a001_phState 6 "SHUTTING_DOWN" 5 "CLEAR_FAULTS" 4 "FAULT" 3 "ENABLE" 2 "PRECHARGE" 1 "IDLE" 0 "INIT" ;
VAL_ 1060 PCS_a002_phState 6 "SHUTTING_DOWN" 5 "CLEAR_FAULTS" 4 "FAULT" 3 "ENABLE" 2 "PRECHARGE" 1 "IDLE" 0 "INIT" ;
VAL_ 1060 PCS_a003_phState 6 "SHUTTING_DOWN" 5 "CLEAR_FAULTS" 4 "FAULT" 3 "ENABLE" 2 "PRECHARGE" 1 "IDLE" 0 "INIT" ;
VAL_ 1060 PCS_a004_phState 6 "SHUTTING_DOWN" 5 "CLEAR_FAULTS" 4 "FAULT" 3 "ENABLE" 2 "PRECHARGE" 1 "IDLE" 0 "INIT" ;
VAL_ 1060 PCS_a006_phState 6 "SHUTTING_DOWN" 5 "CLEAR_FAULTS" 4 "FAULT" 3 "ENABLE" 2 "PRECHARGE" 1 "IDLE" 0 "INIT" ;
VAL_ 1060 PCS_a006_inputFrequency 0 "FREQUENCY_UNKNOWN" ;
VAL_ 1060 PCS_a008_phState 6 "SHUTTING_DOWN" 5 "CLEAR_FAULTS" 4 "FAULT" 3 "ENABLE" 2 "PRECHARGE" 1 "IDLE" 0 "INIT" ;
VAL_ 1060 PCS_a009_phState 6 "SHUTTING_DOWN" 5 "CLEAR_FAULTS" 4 "FAULT" 3 "ENABLE" 2 "PRECHARGE" 1 "IDLE" 0 "INIT" ;
VAL_ 1060 PCS_a010_phState 6 "SHUTTING_DOWN" 5 "CLEAR_FAULTS" 4 "FAULT" 3 "ENABLE" 2 "PRECHARGE" 1 "IDLE" 0 "INIT" ;
VAL_ 1060 PCS_a011_phState 6 "SHUTTING_DOWN" 5 "CLEAR_FAULTS" 4 "FAULT" 3 "ENABLE" 2 "PRECHARGE" 1 "IDLE" 0 "INIT" ;
VAL_ 1060 PCS_a012_phState 6 "SHUTTING_DOWN" 5 "CLEAR_FAULTS" 4 "FAULT" 3 "ENABLE" 2 "PRECHARGE" 1 "IDLE" 0 "INIT" ;
VAL_ 1060 PCS_a013_phState 6 "SHUTTING_DOWN" 5 "CLEAR_FAULTS" 4 "FAULT" 3 "ENABLE" 2 "PRECHARGE" 1 "IDLE" 0 "INIT" ;
VAL_ 1060 PCS_a013_inputFrequency 0 "FREQUENCY_UNKNOWN" ;
VAL_ 1060 PCS_a018_PhaseDiff_L1N_L2N 0 "PHASE_DIFF_UNKNOWN" ;
VAL_ 1060 PCS_a018_PhaseDiff_L2N_L3N 0 "PHASE_DIFF_UNKNOWN" ;
VAL_ 1060 PCS_a018_PhaseDiff_L1N_L3N 0 "PHASE_DIFF_UNKNOWN" ;
VAL_ 1060 PCS_a018_PhaseDiff_L1L2_L1N 0 "PHASE_DIFF_UNKNOWN" ;
VAL_ 1060 PCS_a025_cpu2ErrorCode 10 "CPU2_HWID_CHK_INCOMPLETED" 9 "CRC_VALIDATION_FAILED" 8 "APP_HWID_BAD" 7 "FAILED_TO_RETRIEVE_HWID" 6 "BOOTLOADER_STATUS_INVALID" 5 "FAILED_TO_RETRIEVE_APPCRC" 4 "BOOTSTATUS_INVALID" 3 "APPCRC_MISMATCH" 2 "NO_APP_INSTALLED" 1 "LOSSCOMMS_BOOTLOADER" 0 "NONE" ;
VAL_ 1060 PCS_a029_phaseConfig 9 "TOTAL_NUM" 8 "SINGLE_PHASE_EVSE_PARALLEL" 7 "SINGLE_PHASE_BRIDGED_HARNESS" 6 "MFG_TEST_CONFIG_2" 5 "MFG_TEST_CONFIG_1" 4 "SINGLE_PHASE_IEC_GB" 3 "THREE_PHASE_DELTA" 2 "THREE_PHASE" 1 "SINGLE_PHASE" 0 "SNA" ;
VAL_ 1060 PCS_a030_canRxErrorType 6 "UNKNOWN_ID" 5 "DATAINVALID" 4 "SEQUENCE" 3 "CHECKSUM" 2 "LENGTH_LONG" 1 "LENGTH_SHORT" 0 "NONE" ;
VAL_ 1060 PCS_a038_dcdcClaFaultCode 8 "DEBUG_FORCED" 7 "VTANK_DVDT" 6 "TBCTR_TIMEOUT" 5 "LV_BRD_B_BOOTSTRAP_PRD" 4 "LV_BRD_A_BOOTSTRAP_PRD" 3 "UNEQUAL_ONTIME_ACCUM" 2 "UNEQUAL_ONTIME" 1 "UNEQUAL_PERIOD" 0 "NOT_FAULTED" ;
VAL_ 1060 PCS_a038_dcdcSubState 18 "NUM" 17 "FAULTED" 16 "CLEAR_FAULTS" 15 "PCHG_FAULTED" 14 "DIS_HVBUS_FAULTED" 13 "LV_SUPPORT_FAULTED" 12 "SHUTDOWN" 11 "PCHG_FLT_FAST_DIS_HVBUS" 10 "PCHG_ACTIVE" 9 "PCHG_DI_RECOVERY_WAIT" 8 "PCHG_DWELL_WAIT" 7 "PCHG_DWELL_CHARGE" 6 "PCHG_SLOW_DIS_HVBUS" 5 "PCHG_FAST_DIS_HVBUS" 4 "SLOW_DIS_HVBUS" 3 "FAST_DIS_HVBUS" 2 "LV_SUPPORT_ACTIVE" 1 "STANDBY" 0 "PWR_UP_INIT" ;
VAL_ 1060 PCS_a044_FaultReasonCode 3 "IRRATIONAL_SHORTTIME" 2 "WRONG_DIRECTION" 1 "HIGH_CURRENT" 0 "SNA" ;
VAL_ 1060 PCS_a051_phState 6 "SHUTTING_DOWN" 5 "CLEAR_FAULTS" 4 "FAULT" 3 "ENABLE" 2 "PRECHARGE" 1 "IDLE" 0 "INIT" ;
VAL_ 1060 PCS_a053_phaseConfig 9 "TOTAL_NUM" 8 "SINGLE_PHASE_EVSE_PARALLEL" 7 "SINGLE_PHASE_BRIDGED_HARNESS" 6 "MFG_TEST_CONFIG_2" 5 "MFG_TEST_CONFIG_1" 4 "SINGLE_PHASE_IEC_GB" 3 "THREE_PHASE_DELTA" 2 "THREE_PHASE" 1 "SINGLE_PHASE" 0 "SNA" ;
VAL_ 1060 PCS_a054_phaseConfig 9 "TOTAL_NUM" 8 "SINGLE_PHASE_EVSE_PARALLEL" 7 "SINGLE_PHASE_BRIDGED_HARNESS" 6 "MFG_TEST_CONFIG_2" 5 "MFG_TEST_CONFIG_1" 4 "SINGLE_PHASE_IEC_GB" 3 "THREE_PHASE_DELTA" 2 "THREE_PHASE" 1 "SINGLE_PHASE" 0 "SNA" ;
VAL_ 1060 PCS_a057_inputFrequency 0 "FREQUENCY_UNKNOWN" ;
VAL_ 1060 PCS_a058_inputFrequency 0 "FREQUENCY_UNKNOWN" ;
VAL_ 1060 PCS_a065_inputFrequency 0 "FREQUENCY_UNKNOWN" ;
VAL_ 1060 PCS_a067_vcfrontPcsEFuseV 1023 "SNA" ;
VAL_ 1060 PCS_a067_vcfrontVcrightVoltage 1023 "SNA" ;
VAL_ 1060 PCS_a069_phState 6 "SHUTTING_DOWN" 5 "CLEAR_FAULTS" 4 "FAULT" 3 "ENABLE" 2 "PRECHARGE" 1 "IDLE" 0 "INIT" ;
VAL_ 1060 PCS_a069_inputFrequency 0 "FREQUENCY_UNKNOWN" ;
VAL_ 1060 PCS_a070_phState 6 "SHUTTING_DOWN" 5 "CLEAR_FAULTS" 4 "FAULT" 3 "ENABLE" 2 "PRECHARGE" 1 "IDLE" 0 "INIT" ;
VAL_ 1060 PCS_a070_inputFrequency 0 "FREQUENCY_UNKNOWN" ;
VAL_ 1060 PCS_a071_phState 6 "SHUTTING_DOWN" 5 "CLEAR_FAULTS" 4 "FAULT" 3 "ENABLE" 2 "PRECHARGE" 1 "IDLE" 0 "INIT" ;
VAL_ 1060 PCS_a071_inputFrequency 0 "FREQUENCY_UNKNOWN" ;
VAL_ 1060 PCS_a073_phaseConfig 9 "TOTAL_NUM" 8 "SINGLE_PHASE_EVSE_PARALLEL" 7 "SINGLE_PHASE_BRIDGED_HARNESS" 6 "MFG_TEST_CONFIG_2" 5 "MFG_TEST_CONFIG_1" 4 "SINGLE_PHASE_IEC_GB" 3 "THREE_PHASE_DELTA" 2 "THREE_PHASE" 1 "SINGLE_PHASE" 0 "SNA" ;
VAL_ 1060 PCS_a073_cpType 3 "IEC_CCS" 2 "GB" 1 "EURO_IEC" 0 "US_TESLA" ;
VAL_ 1060 PCS_a075_dcdcSubState 18 "NUM" 17 "FAULTED" 16 "CLEAR_FAULTS" 15 "PCHG_FAULTED" 14 "DIS_HVBUS_FAULTED" 13 "LV_SUPPORT_FAULTED" 12 "SHUTDOWN" 11 "PCHG_FLT_FAST_DIS_HVBUS" 10 "PCHG_ACTIVE" 9 "PCHG_DI_RECOVERY_WAIT" 8 "PCHG_DWELL_WAIT" 7 "PCHG_DWELL_CHARGE" 6 "PCHG_SLOW_DIS_HVBUS" 5 "PCHG_FAST_DIS_HVBUS" 4 "SLOW_DIS_HVBUS" 3 "FAST_DIS_HVBUS" 2 "LV_SUPPORT_ACTIVE" 1 "STANDBY" 0 "PWR_UP_INIT" ;
VAL_ 1060 PCS_a076_pcsControlRequest 3 "DISCHARGE" 2 "PRECHARGE" 1 "SUPPORT" 0 "SHUTDOWN" ;
VAL_ 1060 PCS_a076_dcdcSubState 18 "NUM" 17 "FAULTED" 16 "CLEAR_FAULTS" 15 "PCHG_FAULTED" 14 "DIS_HVBUS_FAULTED" 13 "LV_SUPPORT_FAULTED" 12 "SHUTDOWN" 11 "PCHG_FLT_FAST_DIS_HVBUS" 10 "PCHG_ACTIVE" 9 "PCHG_DI_RECOVERY_WAIT" 8 "PCHG_DWELL_WAIT" 7 "PCHG_DWELL_CHARGE" 6 "PCHG_SLOW_DIS_HVBUS" 5 "PCHG_FAST_DIS_HVBUS" 4 "SLOW_DIS_HVBUS" 3 "FAST_DIS_HVBUS" 2 "LV_SUPPORT_ACTIVE" 1 "STANDBY" 0 "PWR_UP_INIT" ;
VAL_ 1060 PCS_a079_eepromOperation 15 "OPERATION_SNA" 9 "WRITE_RECORD_DATA" 8 "WRITE_RECORD_DESC" 7 "WRITE_RECORD_METADATA" 6 "WRITE_VALIDITY_MARKER" 5 "WRITE_REGION_VALIDITY" 4 "READ_RECORD_DATA" 3 "READ_RECORD_DESC" 2 "READ_RECORD_METADATA" 1 "READ_REGION_VALIDITY_MARKERS" 0 "READ_REGION_VALIDITY" ;
VAL_ 1060 PCS_a079_eepromOperationRegion 3 "UNDEFINED_REGION" 2 "SECONDARY_REGION" 1 "PRIMARY_REGION" 0 "VALIDITY_REGION" ;
VAL_ 1060 PCS_a080_phANVRAMStoredState 4 "RUNNING_CNT_EXPIRED" 3 "RUNNING_CNT_2" 2 "RUNNING_CNT_1" 1 "RUNNING_CNT_0" 0 "PENDING" ;
VAL_ 1060 PCS_a080_phBNVRAMStoredState 4 "RUNNING_CNT_EXPIRED" 3 "RUNNING_CNT_2" 2 "RUNNING_CNT_1" 1 "RUNNING_CNT_0" 0 "PENDING" ;
VAL_ 1060 PCS_a080_phCNVRAMStoredState 4 "RUNNING_CNT_EXPIRED" 3 "RUNNING_CNT_2" 2 "RUNNING_CNT_1" 1 "RUNNING_CNT_0" 0 "PENDING" ;
VAL_ 1060 PCS_a081_faultedSubstate 18 "NUM" 17 "FAULTED" 16 "CLEAR_FAULTS" 15 "PCHG_FAULTED" 14 "DIS_HVBUS_FAULTED" 13 "LV_SUPPORT_FAULTED" 12 "SHUTDOWN" 11 "PCHG_FLT_FAST_DIS_HVBUS" 10 "PCHG_ACTIVE" 9 "PCHG_DI_RECOVERY_WAIT" 8 "PCHG_DWELL_WAIT" 7 "PCHG_DWELL_CHARGE" 6 "PCHG_SLOW_DIS_HVBUS" 5 "PCHG_FAST_DIS_HVBUS" 4 "SLOW_DIS_HVBUS" 3 "FAST_DIS_HVBUS" 2 "LV_SUPPORT_ACTIVE" 1 "STANDBY" 0 "PWR_UP_INIT" ;
VAL_ 1060 PCS_a082_faultedSubstate 18 "NUM" 17 "FAULTED" 16 "CLEAR_FAULTS" 15 "PCHG_FAULTED" 14 "DIS_HVBUS_FAULTED" 13 "LV_SUPPORT_FAULTED" 12 "SHUTDOWN" 11 "PCHG_FLT_FAST_DIS_HVBUS" 10 "PCHG_ACTIVE" 9 "PCHG_DI_RECOVERY_WAIT" 8 "PCHG_DWELL_WAIT" 7 "PCHG_DWELL_CHARGE" 6 "PCHG_SLOW_DIS_HVBUS" 5 "PCHG_FAST_DIS_HVBUS" 4 "SLOW_DIS_HVBUS" 3 "FAST_DIS_HVBUS" 2 "LV_SUPPORT_ACTIVE" 1 "STANDBY" 0 "PWR_UP_INIT" ;
VAL_ 1060 PCS_a088_gridConfig 9 "TOTAL_NUM" 8 "SINGLE_PHASE_EVSE_PARALLEL" 7 "SINGLE_PHASE_BRIDGED_HARNESS" 6 "MFG_TEST_CONFIG_2" 5 "MFG_TEST_CONFIG_1" 4 "SINGLE_PHASE_IEC_GB" 3 "THREE_PHASE_DELTA" 2 "THREE_PHASE" 1 "SINGLE_PHASE" 0 "SNA" ;
VAL_ 1060 PCS_a088_phAFrequency 0 "FREQUENCY_UNKNOWN" ;
VAL_ 1060 PCS_a088_phBFrequency 0 "FREQUENCY_UNKNOWN" ;
VAL_ 1060 PCS_a088_phCFrequency 0 "FREQUENCY_UNKNOWN" ;
VAL_ 1060 PCS_a090_evaluatedGridConfig 9 "TOTAL_NUM" 8 "SINGLE_PHASE_EVSE_PARALLEL" 7 "SINGLE_PHASE_BRIDGED_HARNESS" 6 "MFG_TEST_CONFIG_2" 5 "MFG_TEST_CONFIG_1" 4 "SINGLE_PHASE_IEC_GB" 3 "THREE_PHASE_DELTA" 2 "THREE_PHASE" 1 "SINGLE_PHASE" 0 "SNA" ;
VAL_ 1060 PCS_a094_malfunctionCode 2 "SENSORS" 1 "POWERRAIL" 0 "NONE" ;
VAL_ 1060 PCS_a095_pcsControlRequest 3 "DISCHARGE" 2 "PRECHARGE" 1 "SUPPORT" 0 "SHUTDOWN" ;
VAL_ 1060 PCS_a096_gridConfig 9 "TOTAL_NUM" 8 "SINGLE_PHASE_EVSE_PARALLEL" 7 "SINGLE_PHASE_BRIDGED_HARNESS" 6 "MFG_TEST_CONFIG_2" 5 "MFG_TEST_CONFIG_1" 4 "SINGLE_PHASE_IEC_GB" 3 "THREE_PHASE_DELTA" 2 "THREE_PHASE" 1 "SINGLE_PHASE" 0 "SNA" ;
VAL_ 1060 PCS_a096_phAFrequency 0 "FREQUENCY_UNKNOWN" ;
VAL_ 1060 PCS_a096_phBFrequency 0 "FREQUENCY_UNKNOWN" ;
VAL_ 1060 PCS_a096_phCFrequency 0 "FREQUENCY_UNKNOWN" ;
VAL_ 1060 PCS_a097_phANVRAMStoredState 4 "RUNNING_CNT_EXPIRED" 3 "RUNNING_CNT_2" 2 "RUNNING_CNT_1" 1 "RUNNING_CNT_0" 0 "PENDING" ;
VAL_ 1060 PCS_a097_phBNVRAMStoredState 4 "RUNNING_CNT_EXPIRED" 3 "RUNNING_CNT_2" 2 "RUNNING_CNT_1" 1 "RUNNING_CNT_0" 0 "PENDING" ;
VAL_ 1060 PCS_a097_phCNVRAMStoredState 4 "RUNNING_CNT_EXPIRED" 3 "RUNNING_CNT_2" 2 "RUNNING_CNT_1" 1 "RUNNING_CNT_0" 0 "PENDING" ;
VAL_ 1060 PCS_a102_pcsControlRequest 3 "DISCHARGE" 2 "PRECHARGE" 1 "SUPPORT" 0 "SHUTDOWN" ;
VAL_ 932 PCS_matrixIndex 1 "AlertMatrix1" 0 "AlertMatrix0" ;
VAL_ 516 PCS_chgMainState 9 "PCS_CHG_STATE_CLEAR_FAULTS" 8 "PCS_CHG_STATE_FAULTED" 7 "PCS_CHG_STATE_SHUTDOWN" 6 "PCS_CHG_STATE_ENABLE" 5 "PCS_CHG_STATE_SYSTEM_CONFIG" 4 "PCS_CHG_STATE_QUALIFY_LINE_CONFIG" 3 "PCS_CHG_STATE_WAIT_FOR_LINE_VOLTAGE" 2 "PCS_CHG_STATE_STARTUP" 1 "PCS_CHG_STATE_IDLE" 0 "PCS_CHG_STATE_INIT" ;
VAL_ 516 PCS_hvChargeStatus 3 "FAULTED" 2 "ENABLED" 1 "BLOCKED" 0 "STANDBY" ;
VAL_ 516 PCS_gridConfig 3 "GRID_CONFIG_THREE_PHASE_DELTA" 2 "GRID_CONFIG_THREE_PHASE" 1 "GRID_CONFIG_SINGLE_PHASE" 0 "GRID_CONFIG_SNA" ;
VAL_ 516 PCS_chgMaxAcPowerAvailable 255 "SNA" ;
VAL_ 516 PCS_chargeShutdownRequest 2 "EMERGENCY_SHUTDOWN_REQUESTED" 1 "GRACEFUL_SHUTDOWN_REQUESTED" 0 "NO_SHUTDOWN_REQUESTED" ;
VAL_ 516 PCS_hwVariantType 3 "PCS_HW_VARIANT_TYPE_SNA" 2 "PCS_THREE_PHASES_VARIANT" 1 "PCS_32A_SINGLE_PHASE_VARIANT" 0 "PCS_48A_SINGLE_PHASE_VARIANT" ;
VAL_ 548 PCS_dcdcPrechargeStatus 3 "PCS_DCDC_PRECHARGE_IMPEDANCE_CHECK" 2 "PCS_DCDC_PRECHARGE_FAULTED" 1 "PCS_DCDC_PRECHARGE_ACTIVE" 0 "PCS_DCDC_PRECHARGE_IDLE" ;
VAL_ 548 PCS_dcdcLvSupportStatus 2 "PCS_DCDC_LV_SUPPORT_FAULTED" 1 "PCS_DCDC_LV_SUPPORT_ACTIVE" 0 "PCS_DCDC_LV_SUPPORT_IDLE" ;
VAL_ 548 PCS_dcdcHvBusDischargeStatus 2 "PCS_DCDC_DIS_HVBUS_FAULTED" 1 "PCS_DCDC_DIS_HVBUS_ACTIVE" 0 "PCS_DCDC_DIS_HVBUS_IDLE" ;
VAL_ 548 PCS_dcdcSubState 18 "DCDC_SUBSTATE_NUM" 17 "DCDC_SUBSTATE_FAULTED" 16 "DCDC_SUBSTATE_CLEAR_FAULTS" 15 "DCDC_SUBSTATE_PCHG_FAULTED" 14 "DCDC_SUBSTATE_DIS_HVBUS_FAULTED" 13 "DCDC_SUBSTATE_LV_SUPPORT_FAULTED" 12 "DCDC_SUBSTATE_SHUTDOWN" 11 "DCDC_SUBSTATE_PCHG_FLT_FAST_DIS_HVBUS" 10 "DCDC_SUBSTATE_PCHG_ACTIVE" 9 "DCDC_SUBSTATE_PCHG_DI_RECOVERY_WAIT" 8 "DCDC_SUBSTATE_PCHG_DWELL_WAIT" 7 "DCDC_SUBSTATE_PCHG_DWELL_CHARGE" 6 "DCDC_SUBSTATE_PCHG_SLOW_DIS_HVBUS" 5 "DCDC_SUBSTATE_PCHG_FAST_DIS_HVBUS" 4 "DCDC_SUBSTATE_SLOW_DIS_HVBUS" 3 "DCDC_SUBSTATE_FAST_DIS_HVBUS" 2 "DCDC_SUBSTATE_LV_SUPPORT_ACTIVE" 1 "DCDC_SUBSTATE_STANDBY" 0 "DCDC_SUBSTATE_PWR_UP_INIT" ;
VAL_ 548 PCS_ecuLogUploadRequest 3 "REQUEST_PRIORITY_3" 2 "REQUEST_PRIORITY_2" 1 "REQUEST_PRIORITY_1" 0 "REQUEST_PRIORITY_NONE" ;
VAL_ 548 PCS_dcdcInitialPrechargeSubState 18 "DCDC_SUBSTATE_NUM" 17 "DCDC_SUBSTATE_FAULTED" 16 "DCDC_SUBSTATE_CLEAR_FAULTS" 15 "DCDC_SUBSTATE_PCHG_FAULTED" 14 "DCDC_SUBSTATE_DIS_HVBUS_FAULTED" 13 "DCDC_SUBSTATE_LV_SUPPORT_FAULTED" 12 "DCDC_SUBSTATE_SHUTDOWN" 11 "DCDC_SUBSTATE_PCHG_FLT_FAST_DIS_HVBUS" 10 "DCDC_SUBSTATE_PCHG_ACTIVE" 9 "DCDC_SUBSTATE_PCHG_DI_RECOVERY_WAIT" 8 "DCDC_SUBSTATE_PCHG_DWELL_WAIT" 7 "DCDC_SUBSTATE_PCHG_DWELL_CHARGE" 6 "DCDC_SUBSTATE_PCHG_SLOW_DIS_HVBUS" 5 "DCDC_SUBSTATE_PCHG_FAST_DIS_HVBUS" 4 "DCDC_SUBSTATE_SLOW_DIS_HVBUS" 3 "DCDC_SUBSTATE_FAST_DIS_HVBUS" 2 "DCDC_SUBSTATE_LV_SUPPORT_ACTIVE" 1 "DCDC_SUBSTATE_STANDBY" 0 "DCDC_SUBSTATE_PWR_UP_INIT" ;
